VERSION ""

NS_ :

BS_:

BU_: ACU ALC BCM ESCL HFM HPCU HVAC_CU LCU_ADB LCU_MBL MainLiB12V USM eRDC_L eRDC_R

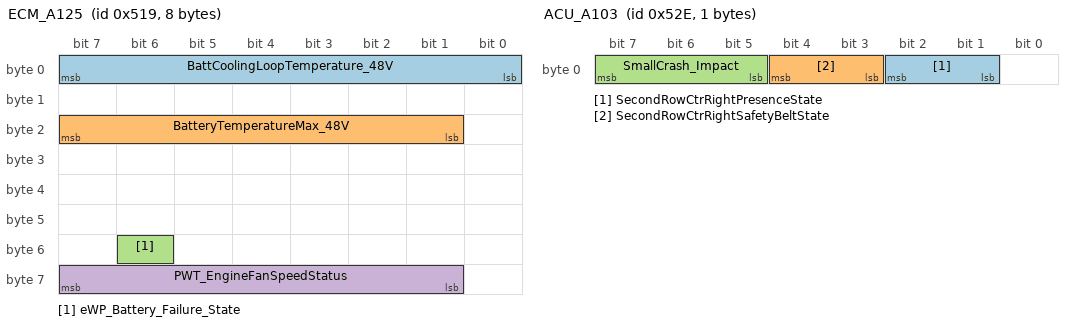
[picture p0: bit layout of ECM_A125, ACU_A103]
BO_ 1305 ECM_A125: 8 BCM
  SG_ BattCoolingLoopTemperature_48V : 7|8@0+ (1,-50) [-50|130] "°C" HVAC_CU
  SG_ BatteryTemperatureMax_48V : 23|7@0+ (1,-40) [-40|80] "°C" HVAC_CU
  SG_ eWP_Battery_Failure_State : 54|1@0+ (1,0) [0|0] "" HVAC_CU
  SG_ PWT_EngineFanSpeedStatus : 63|7@0+ (1,0) [0|100] "%" USM

BO_ 1306 HFM_BLM_pairing_Frame: 8 HFM
  SG_ HFM_BLM_pairing : 7|64@0+ (1,0) [0|0] "" BCM

BO_ 1308 BLM_HFM_pairing_Frame: 8 BCM
  SG_ BLM_HFM_pairing : 7|64@0+ (1,0) [0|0] "" HFM

BO_ 1311 BCM_A121: 3 BCM
  SG_ Flush_MovingRequest : 7|2@0+ (1,0) [0|0] "" HFM

BO_ 1315 BCM_A8: 3 BCM
  SG_ AbsoluteTimeSince1rstIgnition : 7|24@0+ (1,0) [0|1.677E7] "min" HVAC_CU,USM

BO_ 1322 HVAC_A9: 8 HVAC_CU
  SG_ HVAC_CalID2 : 7|64@0+ (1,0) [0|1.84467440737095E19] "" BCM

BO_ 1326 ACU_A103: 1 ACU
  SG_ SecondRowCtrRightPresenceState : 2|2@0+ (1,0) [0|0] "" BCM
  SG_ SecondRowCtrRightSafetyBeltState : 4|2@0+ (1,0) [0|0] "" BCM
  SG_ SmallCrash_Impact : 7|3@0+ (1,0) [0|0] "" BCM

BO_ 1328 HEVC_A167: 8 BCM
  SG_ HVbatCoolingSaveRequest : 57|1@0+ (1,0) [0|0] "" HVAC_CU
  SG_ HVbatCoolingSave_AmbTempThres : 63|6@0+ (1,-10) [-10|50] "degC" HVAC_CU

BO_ 1332 ACU_A101: 8 ACU
  SG_ CRC_ACU_A101 : 7|8@0+ (1,0) [0|255] "" BCM
  SG_ AIRBAGMalfunction : 8|1@0+ (1,0) [0|0] "" BCM
  SG_ ActiveHoodWarningLampCheck : 9|1@0+ (1,0) [0|0] "" BCM
  SG_ ActiveHoodMalfunction : 11|2@0+ (1,0) [0|0] "" BCM
  SG_ Clock_ACU_A101 : 15|4@0+ (1,0) [0|15] "" BCM
  SG_ PassengerAlertState : 17|2@0+ (1,0) [0|0] "" BCM
  SG_ PassengerAIRBAG_Inhibition : 18|1@0+ (1,0) [0|0] "" BCM
  SG_ CrashDetectionOutOfOrder_v2 : 20|2@0+ (1,0) [0|0] "" BCM
  SG_ CrashDetected_v2 : 22|2@0+ (1,0) [0|0] "" BCM
  SG_ AirbagWarningLampCheck : 23|1@0+ (1,0) [0|0] "" BCM
  SG_ SecondRowCenterPresenceState : 26|2@0+ (1,0) [0|0] "" BCM,HVAC_CU,USM
  SG_ RolloverDetectionMalfunction : 27|1@0+ (1,0) [0|0] "" BCM
  SG_ PassengerSafetyBeltBuckleState : 29|2@0+ (1,0) [0|0] "" BCM,HVAC_CU,USM
  SG_ PassengerPresenceState : 31|2@0+ (1,0) [0|0] "" BCM,HVAC_CU,USM
  SG_ SecondRowRightPresenceState : 33|2@0+ (1,0) [0|0] "" BCM,HVAC_CU,USM
  SG_ SecondRowLeftSafetyBeltState : 35|2@0+ (1,0) [0|0] "" BCM,HVAC_CU,USM
  SG_ SecondRowLeftPresenceState : 37|2@0+ (1,0) [0|0] "" BCM,HVAC_CU,USM
  SG_ SecondRowCenterSafetyBeltState : 39|2@0+ (1,0) [0|0] "" BCM,HVAC_CU,USM
  SG_ ThirdRowLeftPresenceState : 41|2@0+ (1,0) [0|0] "" BCM,HVAC_CU,USM
  SG_ ThirdRowCenterSafetyBeltState : 43|2@0+ (1,0) [0|0] "" BCM,HVAC_CU,USM
  SG_ ThirdRowCenterPresenceState : 45|2@0+ (1,0) [0|0] "" BCM,USM
  SG_ SecondRowRightSafetyBeltState : 47|2@0+ (1,0) [0|0] "" BCM,HVAC_CU,USM
  SG_ FirstRowCenterPresenceState : 49|2@0+ (1,0) [0|0] "" BCM,HVAC_CU,USM
  SG_ ThirdRowRightSafetyBeltState : 51|2@0+ (1,0) [0|0] "" BCM,HVAC_CU,USM
  SG_ ThirdRowRightPresenceState : 53|2@0+ (1,0) [0|0] "" BCM,HVAC_CU,USM
  SG_ ThirdRowLeftSafetyBeltState : 55|2@0+ (1,0) [0|0] "" BCM,HVAC_CU,USM
  SG_ PassengerAIRBAG_Status_Display : 59|2@0+ (1,0) [0|0] "" BCM
  SG_ PassengerAIRBAG_Inhibition_v2 : 61|2@0+ (1,0) [0|0] "" BCM
  SG_ FirstRowCenterSafetyBeltState : 63|2@0+ (1,0) [0|0] "" BCM,HVAC_CU,USM

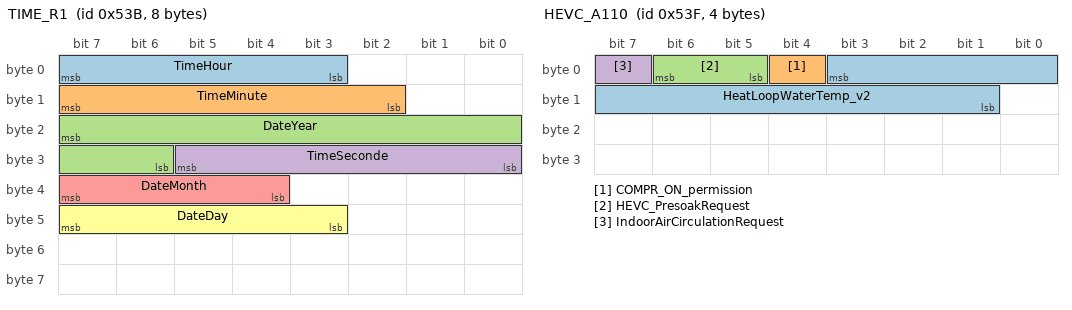
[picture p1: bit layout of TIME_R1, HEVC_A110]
BO_ 1339 TIME_R1: 8 BCM
  SG_ TimeHour : 7|5@0+ (1,0) [0|23] "h" ACU,HVAC_CU
  SG_ TimeMinute : 15|6@0+ (1,0) [0|59] "min" ACU,HVAC_CU
  SG_ DateYear : 23|10@0+ (1,2000) [2000|3000] "year" ACU
  SG_ TimeSeconde : 29|6@0+ (1,0) [0|59] "s" ACU
  SG_ DateMonth : 39|4@0+ (1,0) [0|12] "month" ACU
  SG_ DateDay : 47|5@0+ (1,0) [0|31] "day" ACU

BO_ 1343 HEVC_A110: 4 BCM
  SG_ HeatLoopWaterTemp_v2 : 3|11@0+ (0.1,-40) [-40|100] "°C" HVAC_CU
  SG_ COMPR_ON_permission : 4|1@0+ (1,0) [0|0] "" HVAC_CU
  SG_ HEVC_PresoakRequest : 6|2@0+ (1,0) [0|0] "" HVAC_CU
  SG_ IndoorAirCirculationRequest : 7|1@0+ (1,0) [0|0] "" HVAC_CU

BO_ 1352 HVAC_A8: 8 HVAC_CU
  SG_ HVAC_CalID1 : 7|64@0+ (1,0) [0|1.84467440737095E19] "" BCM

BO_ 1360 ECM_A121: 4 BCM
  SG_ EngineThrottlePosition : 7|7@0+ (1,0) [0|100] "%" ACU
  SG_ HVlightChargeRequest : 15|1@0+ (1,0) [0|0] "" USM

BO_ 1361 ADAS_A162: 8 BCM
  SG_ ELKA_OTOC_ActivationState : 52|1@0+ (1,0) [0|0] "" ACU
  SG_ ELKS_ActivationState : 54|1@0+ (1,0) [0|0] "" ACU

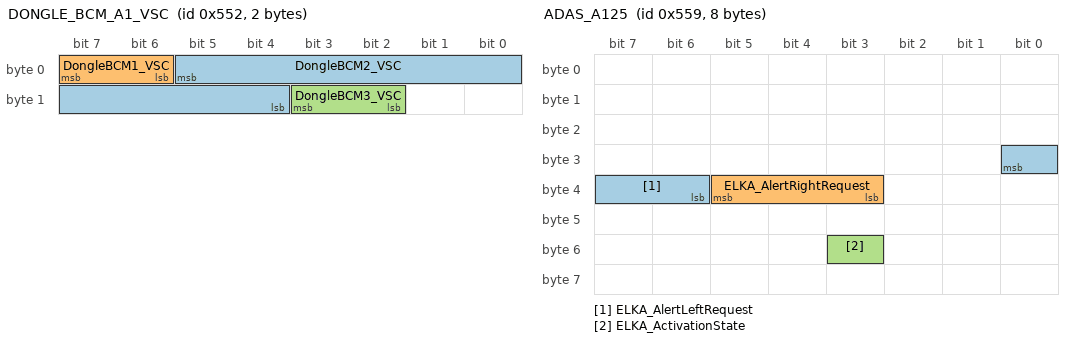
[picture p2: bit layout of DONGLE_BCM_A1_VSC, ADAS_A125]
BO_ 1362 DONGLE_BCM_A1_VSC: 2 HFM
  SG_ DongleBCM2_VSC : 5|10@0+ (1,0) [0|0] "" BCM
  SG_ DongleBCM1_VSC : 7|2@0+ (1,0) [0|0] "" BCM
  SG_ DongleBCM3_VSC : 11|2@0+ (1,0) [0|0] "" BCM

BO_ 1364 HVAC_A112: 7 HVAC_CU
  SG_ ClimElecConsumptionLimitDisplay : 1|2@0+ (1,0) [0|0] "" BCM
  SG_ ClimVariableAirFlowDisplay : 4|3@0+ (1,0) [0|0] "" BCM
  SG_ ClimRearOFFModeDisplay : 5|1@0+ (1,0) [0|0] "" BCM
  SG_ ClimRearLockStatus : 7|2@0+ (1,0) [0|0] "" BCM
  SG_ ClimLinkPrio3rdLSeatAutoDisp : 10|3@0+ (1,0) [0|0] "" BCM
  SG_ ClimIRSensorOn_Display : 12|2@0+ (1,0) [0|0] "" BCM
  SG_ ClimLinkPriorityRRSeatAutoDisp : 15|3@0+ (1,0) [0|0] "" BCM
  SG_ ProactiveRecyclingStatus : 16|1@0+ (1,0) [0|0] "" BCM
  SG_ ClimAllSeatAutoDisplay : 18|2@0+ (1,0) [0|0] "" BCM
  SG_ ClimLinkPrio3rdRSeatAutoDisp : 21|3@0+ (1,0) [0|0] "" BCM
  SG_ ClimRearOFFModeDisplayStatus : 22|1@0+ (1,0) [0|0] "" BCM
  SG_ ClimRearLockDisplayStatus : 23|1@0+ (1,0) [0|0] "" BCM
  SG_ HVBatteryCoolingType : 25|2@0+ (1,0) [0|0] "" BCM
  SG_ RecyPollutionStatus : 27|2@0+ (1,0) [0|0] "" BCM
  SG_ MistingRisk : 31|4@0+ (1,0) [0|10] "WU" BCM
  SG_ SecondRightSeatModeDisp : 33|2@0+ (1,0) [0|0] "" BCM
  SG_ SecondLeftSeatModeDisp : 35|2@0+ (1,0) [0|0] "" BCM
  SG_ FrontRightSeatModeDisp : 37|2@0+ (1,0) [0|0] "" BCM
  SG_ FrontLeftSeatModeDisp : 39|2@0+ (1,0) [0|0] "" BCM
  SG_ ClimLinkOccupantForSeatDisplay : 41|2@0+ (1,0) [0|0] "" BCM
  SG_ ClimLinkOccupantForDRZoneDisp : 43|2@0+ (1,0) [0|0] "" BCM
  SG_ ClimShortcutRequest : 47|4@0+ (1,0) [0|0] "" BCM
  SG_ ClimPartialAutoState : 55|1@0+ (1,0) [0|0] "" BCM

BO_ 1369 ADAS_A125: 8 BCM
  SG_ ELKA_AlertLeftRequest : 24|3@0+ (1,0) [0|0] "" ACU
  SG_ ELKA_AlertRightRequest : 37|3@0+ (1,0) [0|0] "" ACU
  SG_ ELKA_ActivationState : 51|1@0+ (1,0) [0|0] "" ACU

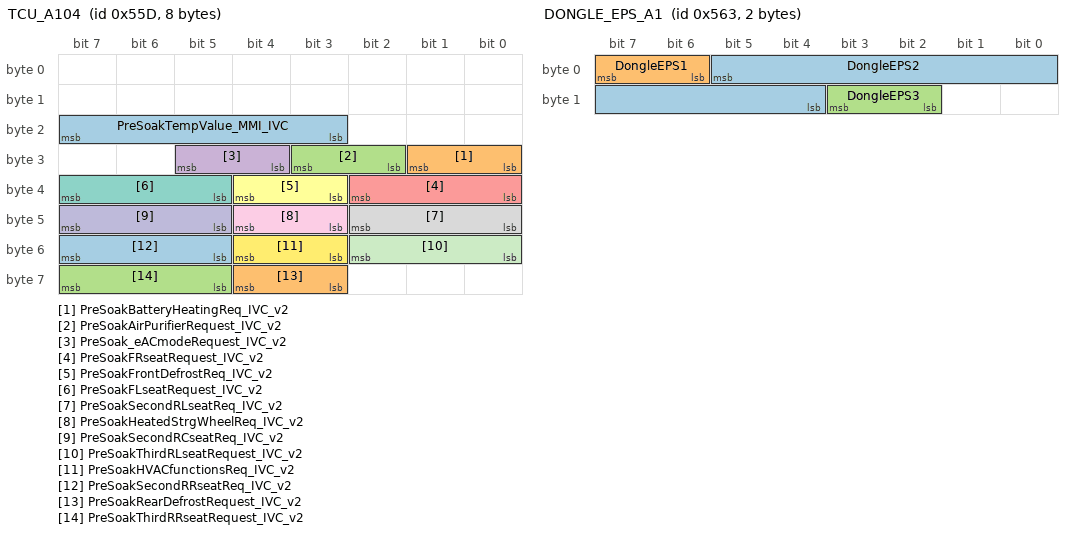
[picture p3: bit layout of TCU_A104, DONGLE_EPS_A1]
BO_ 1373 TCU_A104: 8 BCM
  SG_ PreSoakTempValue_MMI_IVC : 23|5@0+ (0.5,16) [16|32] "°C" HVAC_CU
  SG_ PreSoakBatteryHeatingReq_IVC_v2 : 25|2@0+ (1,0) [0|0] "" HVAC_CU
  SG_ PreSoakAirPurifierRequest_IVC_v2 : 27|2@0+ (1,0) [0|0] "" HVAC_CU
  SG_ PreSoak_eACmodeRequest_IVC_v2 : 29|2@0+ (1,0) [0|0] "" HVAC_CU
  SG_ PreSoakFRseatRequest_IVC_v2 : 34|3@0+ (1,0) [0|0] "" HVAC_CU
  SG_ PreSoakFrontDefrostReq_IVC_v2 : 36|2@0+ (1,0) [0|0] "" HVAC_CU
  SG_ PreSoakFLseatRequest_IVC_v2 : 39|3@0+ (1,0) [0|0] "" HVAC_CU
  SG_ PreSoakSecondRLseatReq_IVC_v2 : 42|3@0+ (1,0) [0|0] "" HVAC_CU
  SG_ PreSoakHeatedStrgWheelReq_IVC_v2 : 44|2@0+ (1,0) [0|0] "" HVAC_CU
  SG_ PreSoakSecondRCseatReq_IVC_v2 : 47|3@0+ (1,0) [0|0] "" HVAC_CU
  SG_ PreSoakThirdRLseatRequest_IVC_v2 : 50|3@0+ (1,0) [0|0] "" HVAC_CU
  SG_ PreSoakHVACfunctionsReq_IVC_v2 : 52|2@0+ (1,0) [0|0] "" HVAC_CU
  SG_ PreSoakSecondRRseatReq_IVC_v2 : 55|3@0+ (1,0) [0|0] "" HVAC_CU
  SG_ PreSoakRearDefrostRequest_IVC_v2 : 60|2@0+ (1,0) [0|0] "" HVAC_CU
  SG_ PreSoakThirdRRseatRequest_IVC_v2 : 63|3@0+ (1,0) [0|0] "" HVAC_CU

BO_ 1379 DONGLE_EPS_A1: 2 BCM
  SG_ DongleEPS2 : 5|10@0+ (1,0) [0|0] "" HFM
  SG_ DongleEPS1 : 7|2@0+ (1,0) [0|0] "" HFM
  SG_ DongleEPS3 : 11|2@0+ (1,0) [0|0] "" HFM

BO_ 1381 SRRR_A106: 6 BCM
  SG_ BSWrad_AlertStatus : 4|2@0+ (1,0) [0|0] "" ACU

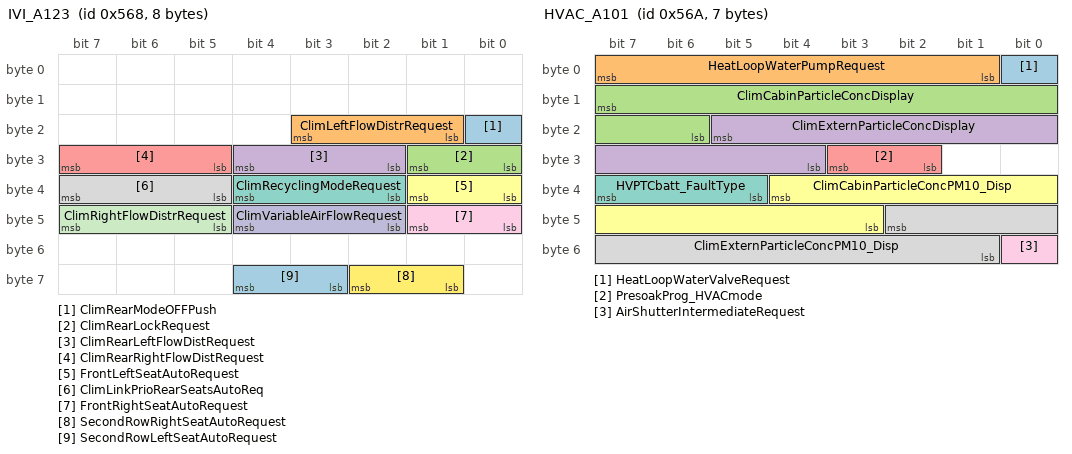
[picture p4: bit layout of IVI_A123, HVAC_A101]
BO_ 1384 IVI_A123: 8 BCM
  SG_ ClimRearModeOFFPush : 16|1@0+ (1,0) [0|1] "-" HVAC_CU
  SG_ ClimLeftFlowDistrRequest : 19|3@0+ (1,0) [0|0] "" HVAC_CU
  SG_ ClimRearLockRequest : 25|2@0+ (1,0) [0|0] "" HVAC_CU
  SG_ ClimRearLeftFlowDistRequest : 28|3@0+ (1,0) [0|0] "" HVAC_CU
  SG_ ClimRearRightFlowDistRequest : 31|3@0+ (1,0) [0|0] "" HVAC_CU
  SG_ FrontLeftSeatAutoRequest : 33|2@0+ (1,0) [0|0] "" HVAC_CU
  SG_ ClimRecyclingModeRequest : 36|3@0+ (1,0) [0|0] "" HVAC_CU
  SG_ ClimLinkPrioRearSeatsAutoReq : 39|3@0+ (1,0) [0|0] "" HVAC_CU
  SG_ FrontRightSeatAutoRequest : 41|2@0+ (1,0) [0|0] "" HVAC_CU
  SG_ ClimVariableAirFlowRequest : 44|3@0+ (1,0) [0|0] "" HVAC_CU
  SG_ ClimRightFlowDistrRequest : 47|3@0+ (1,0) [0|0] "" HVAC_CU
  SG_ SecondRowRightSeatAutoRequest : 58|2@0+ (1,0) [0|0] "" HVAC_CU
  SG_ SecondRowLeftSeatAutoRequest : 60|2@0+ (1,0) [0|0] "" HVAC_CU

BO_ 1386 HVAC_A101: 7 HVAC_CU
  SG_ HeatLoopWaterValveRequest : 0|1@0+ (1,0) [0|0] "" BCM
  SG_ HeatLoopWaterPumpRequest : 7|7@0+ (1,0) [0|100] "%" BCM
  SG_ ClimCabinParticleConcDisplay : 15|10@0+ (5,0) [0|4095] "µg/m3" BCM
  SG_ ClimExternParticleConcDisplay : 21|10@0+ (5,0) [0|4095] "µg/m3" BCM
  SG_ PresoakProg_HVACmode : 27|2@0+ (1,0) [0|0] "" BCM
  SG_ ClimCabinParticleConcPM10_Disp : 36|10@0+ (5,0) [0|4095] "µg/m3" BCM
  SG_ HVPTCbatt_FaultType : 39|3@0+ (1,0) [0|0] "" BCM
  SG_ ClimExternParticleConcPM10_Disp : 42|10@0+ (5,0) [0|4095] "µg/m3" BCM
  SG_ AirShutterIntermediateRequest : 48|1@0+ (1,0) [0|0] "" BCM

BO_ 1387 HVAC_A110: 8 HVAC_CU
  SG_ HVAC_CVN : 7|64@0+ (1,0) [0|1.84467440737095E19] "" BCM

BO_ 1391 HVAC_A109: 2 HVAC_CU
  SG_ AC_eBattPTCInterlockHVConnector : 11|2@0+ (1,0) [0|0] "" BCM

BO_ 1392 IVI_A119: 8 BCM
  SG_ FOTA_ReadyToSleep_IVI : 9|1@0+ (1,0) [0|0] "" USM

BO_ 1395 HEVC_A137: 6 BCM
  SG_ SecondaryShaft_Speed : 31|12@0+ (100,-32700) [-32700|32700] "rpm" ACU
  SG_ HSG_ElecMachineSpeed_EDR : 35|12@0+ (100,-20000) [-20000|20000] "rpm" ACU

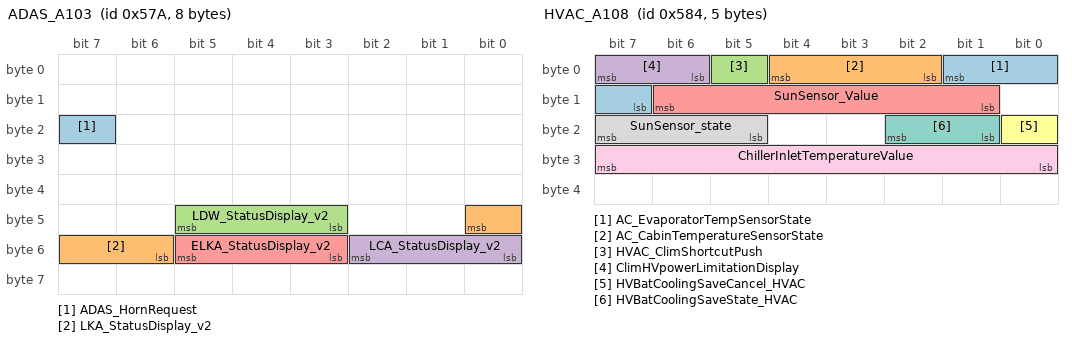
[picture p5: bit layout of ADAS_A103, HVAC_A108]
BO_ 1402 ADAS_A103: 8 BCM
  SG_ ADAS_HornRequest : 23|1@0+ (1,0) [0|0] "" USM
  SG_ LKA_StatusDisplay_v2 : 40|3@0+ (1,0) [0|0] "" ACU
  SG_ LDW_StatusDisplay_v2 : 45|3@0+ (1,0) [0|0] "" ACU
  SG_ LCA_StatusDisplay_v2 : 50|3@0+ (1,0) [0|0] "" ACU
  SG_ ELKA_StatusDisplay_v2 : 53|3@0+ (1,0) [0|0] "" ACU

BO_ 1405 AVM_N104: 7 BCM
  SG_ RPK_ModeRequest : 55|2@0+ (1,0) [0|0] "" HFM

BO_ 1409 ESCL3_to_BCM: 8 ESCL
  SG_ Blank_Coded : 0|1@0+ (1,0) [0|0] "" HFM
  SG_ LockingFinished : 1|1@0+ (1,0) [0|0] "" HFM
  SG_ Undefined_position : 2|1@0+ (1,0) [0|0] "" HFM
  SG_ UnlockingFinished : 3|1@0+ (1,0) [0|0] "" HFM
  SG_ LockForbidden : 4|1@0+ (1,0) [0|0] "" HFM
  SG_ AntiscanOn : 5|1@0+ (1,0) [0|0] "" HFM
  SG_ WrongCode : 6|1@0+ (1,0) [0|0] "" HFM
  SG_ SteeringLockCOP : 7|1@0+ (1,0) [0|0] "" HFM
  SG_ SteeringLockMajorElectronicFailure : 9|1@0+ (1,0) [0|0] "" HFM
  SG_ Steering_actuator_failure : 10|1@0+ (1,0) [0|0] "" HFM
  SG_ ESCL3Position : 13|3@0+ (1,0) [0|0] "" HFM
  SG_ SteeringLock_Minor_Electronic_Failure : 14|1@0+ (1,0) [0|0] "" HFM
  SG_ ResetInfo_Verrou : 15|1@0+ (1,0) [0|0] "" HFM
  SG_ PowerSupplyFeedback : 18|1@0+ (1,0) [0|0] "" HFM
  SG_ SafetyLineInhibition : 20|1@0+ (1,0) [0|0] "" HFM
  SG_ SpeedInhibition : 23|1@0+ (1,0) [0|0] "" HFM
  SG_ SensorTestAuthorized : 31|1@0+ (1,0) [0|0] "" HFM
  SG_ CRC_ESCL3_to_BCM : 39|8@0+ (1,0) [0|255] "" HFM
  SG_ Inconsistency_Frame : 43|1@0+ (1,0) [0|0] "" HFM
  SG_ Clock_ESCL3_to_BCM : 47|4@0+ (1,0) [0|15] "" HFM

BO_ 1412 HVAC_A108: 5 HVAC_CU
  SG_ AC_EvaporatorTempSensorState : 1|3@0+ (1,0) [0|0] "" BCM
  SG_ AC_CabinTemperatureSensorState : 4|3@0+ (1,0) [0|0] "" BCM
  SG_ HVAC_ClimShortcutPush : 5|1@0+ (1,0) [0|0] "" BCM
  SG_ ClimHVpowerLimitationDisplay : 7|2@0+ (1,0) [0|0] "" BCM
  SG_ SunSensor_Value : 14|6@0+ (25,0) [0|1200] "W/m2" BCM
  SG_ HVBatCoolingSaveCancel_HVAC : 16|1@0+ (1,0) [0|0] "" BCM
  SG_ HVBatCoolingSaveState_HVAC : 18|2@0+ (1,0) [0|0] "" BCM
  SG_ SunSensor_state : 23|3@0+ (1,0) [0|0] "" BCM
  SG_ ChillerInletTemperatureValue : 31|8@0+ (1,-40) [-40|105] "°C" BCM

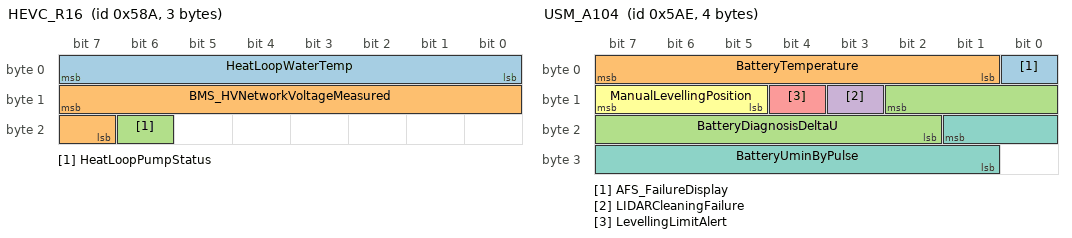
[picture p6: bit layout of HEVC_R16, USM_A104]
BO_ 1418 HEVC_R16: 3 BCM
  SG_ HeatLoopWaterTemp : 7|8@0+ (1,-40) [-40|214] "°C" HVAC_CU
  SG_ BMS_HVNetworkVoltageMeasured : 15|9@0+ (1,0) [0|500] "V" HVAC_CU
  SG_ HeatLoopPumpStatus : 22|1@0+ (1,0) [0|0] "" HVAC_CU

BO_ 1430 ADAS_A166: 1 BCM
  SG_ AEB_Classification : 4|3@0+ (1,0) [0|0] "" ACU
  SG_ AEB_Activation_Flag : 7|3@0+ (1,0) [0|0] "" ACU

BO_ 1436 HFP_R5: 6 BCM
  SG_ HFP_MapContentDisplay : 31|3@0+ (1,0) [0|0] "" ACU

BO_ 1449 IVI_A109: 8 BCM
  SG_ ClimFrontDefrostPush : 0|1@0+ (1,0) [0|1] "-" HVAC_CU
  SG_ ClimRearDefrostPush : 1|1@0+ (1,0) [0|1] "-" HVAC_CU
  SG_ SecondRowLeftSeatAutoPush : 2|1@0+ (1,0) [0|1] "-" HVAC_CU
  SG_ SecondRowRightSeatAutoPush : 3|1@0+ (1,0) [0|1] "-" HVAC_CU
  SG_ ThirdRowLeftSeatAutoPush : 4|1@0+ (1,0) [0|1] "-" HVAC_CU
  SG_ ThirdRowRightSeatAutoPush : 5|1@0+ (1,0) [0|1] "-" HVAC_CU
  SG_ ClimHeatedSteeringWheelPush : 6|1@0+ (1,0) [0|1] "-" HVAC_CU
  SG_ ClimHeatedSteeringWheelAutoPush : 7|1@0+ (1,0) [0|1] "-" HVAC_CU
  SG_ ClimRearLeftTempRequest : 15|9@0+ (0.5,10) [10|127.5] "°" HVAC_CU
  SG_ ClimRearRightTempRequest : 22|9@0+ (0.5,10) [10|127.5] "°" HVAC_CU
  SG_ ClimRearRightFlowDistrVentPush : 24|1@0+ (1,0) [0|1] "" HVAC_CU
  SG_ ClimRearLeftFlowDistrVentPush : 25|1@0+ (1,0) [0|1] "" HVAC_CU
  SG_ ClimRearRightFlowDistrDefPush : 26|1@0+ (1,0) [0|1] "" HVAC_CU
  SG_ ClimRearLeftFlowDistrDefPush : 27|1@0+ (1,0) [0|1] "" HVAC_CU
  SG_ ClimRearRightSyncPush : 28|1@0+ (1,0) [0|1] "" HVAC_CU
  SG_ ClimRearLeftSyncPush : 29|1@0+ (1,0) [0|1] "" HVAC_CU
  SG_ ClimLinkPriorityHeatStrgAutoReq : 34|3@0+ (1,0) [0|0] "" HVAC_CU
  SG_ ClimRearRightAutoNormalPush : 35|1@0+ (1,0) [0|1] "" HVAC_CU
  SG_ ClimRearLeftAutoNormalPush : 36|1@0+ (1,0) [0|1] "" HVAC_CU
  SG_ ClimRearACPush : 37|1@0+ (1,0) [0|1] "" HVAC_CU
  SG_ ClimRearRightFlowDistrFeetPush : 38|1@0+ (1,0) [0|1] "" HVAC_CU
  SG_ ClimRearLeftFlowDistrFeetPush : 39|1@0+ (1,0) [0|1] "" HVAC_CU
  SG_ ClimFPrearLeftBlowingRequest : 43|4@0+ (1,0) [0|0] "" HVAC_CU
  SG_ ClimFPrearRightBlowingRequest : 47|4@0+ (1,0) [0|0] "" HVAC_CU
  SG_ ClimLinkPriorityRRSeatAutoReq : 50|3@0+ (1,0) [0|0] "" HVAC_CU
  SG_ ClimACmaxPush : 51|1@0+ (1,0) [0|1] "-" HVAC_CU
  SG_ ClimAllSeatAutoNormalRequest : 57|2@0+ (1,0) [0|0] "" HVAC_CU
  SG_ ClimLinkPrio3rdRSeatAutoReq : 60|3@0+ (1,0) [0|0] "" HVAC_CU
  SG_ ClimLinkPrio3rdLSeatAutoReq : 63|3@0+ (1,0) [0|0] "" HVAC_CU

BO_ 1454 USM_A104: 4 USM
  SG_ AFS_FailureDisplay : 0|1@0+ (1,0) [0|0] "" BCM
  SG_ BatteryTemperature : 7|7@0+ (1,-40) [-40|80] "°C" BCM
  SG_ BatteryDiagnosisDeltaU : 10|9@0+ (0.05,0) [0|17] "V" BCM
  SG_ LIDARCleaningFailure : 11|1@0+ (1,0) [0|0] "" BCM
  SG_ LevellingLimitAlert : 12|1@0+ (1,0) [0|0] "" BCM
  SG_ ManualLevellingPosition : 15|3@0+ (1,0) [0|0] "" BCM
  SG_ BatteryUminByPulse : 17|9@0+ (0.05,0) [0|17] "V" BCM

BO_ 1457 BCM_R9: 4 BCM
  SG_ LightingSystemFailureDisplay : 17|1@0+ (1,0) [0|0] "" LCU_ADB

BO_ 1458 HEVC_R112: 8 BCM
  SG_ SportModeThmgtRequest : 63|2@0+ (1,0) [0|0] "" HVAC_CU

BO_ 1462 HVAC_A105: 8 HVAC_CU
  SG_ ClimRearLeftTempDisplay : 7|9@0+ (0.5,0) [10|127.5] "°" BCM
  SG_ ClimFrontDefrostDisplayStatus : 8|1@0+ (1,0) [0|0] "" BCM
  SG_ ClimHeatedSteerWheelDispStatus : 9|1@0+ (1,0) [0|0] "" BCM
  SG_ ClimRearLeftTempDisplayStatus : 10|1@0+ (1,0) [0|0] "" BCM
  SG_ ClimHeatedSteerWheelAutoDisplay : 12|2@0+ (1,0) [0|0] "" BCM
  SG_ ClimFrontDefrostDisplay : 14|2@0+ (1,0) [0|0] "" BCM
  SG_ ClimRearRightTempDisplay : 23|9@0+ (0.5,0) [10|127.5] "°" BCM
  SG_ ClimRearRightSyncDisplayStatus : 24|1@0+ (1,0) [0|0] "" BCM
  SG_ ClimRearRightSyncDisplay : 26|2@0+ (1,0) [0|0] "" BCM
  SG_ ClimRearLeftSyncDisplayStatus : 27|1@0+ (1,0) [0|0] "" BCM
  SG_ ClimRearLeftSyncDisplay : 29|2@0+ (1,0) [0|0] "" BCM
  SG_ ClimRearRightTempDisplayStatus : 30|1@0+ (1,0) [0|0] "" BCM
  SG_ ClimRearRightFlowDistDispStatus : 32|1@0+ (1,0) [0|0] "" BCM
  SG_ ClimRearRightFlowDistrDisplay : 35|3@0+ (1,0) [0|0] "" BCM
  SG_ ClimRearLeftFlowDistrDispStatus : 36|1@0+ (1,0) [0|0] "" BCM
  SG_ ClimRearLeftFlowDistrDisplay : 39|3@0+ (1,0) [0|0] "" BCM
  SG_ ClimRearLeftBlowingAutoDisplay : 41|2@0+ (1,0) [0|0] "" BCM
  SG_ ClimRearRightBlowingAutoDisplay : 43|2@0+ (1,0) [0|0] "" BCM
  SG_ ClimRearRightBlowLevelDisplay : 47|4@0+ (1,0) [0|0] "" BCM
  SG_ ClimRearACDisplay : 49|2@0+ (1,0) [0|0] "" BCM
  SG_ ClimRearRightBlowLevlDispStatus : 50|1@0+ (1,0) [0|0] "" BCM
  SG_ ClimRearLeftBlowLevelDispStatus : 51|1@0+ (1,0) [0|0] "" BCM
  SG_ ClimRearLeftBlowLevelDisplay : 55|4@0+ (1,0) [0|0] "" BCM
  SG_ ClimLinkPrioritHeatStrgAutoDisp : 58|3@0+ (1,0) [0|0] "" BCM
  SG_ ClimRearRightAutoDisplay : 60|2@0+ (1,0) [0|0] "" BCM
  SG_ ClimRearLeftAutoDisplay : 62|2@0+ (1,0) [0|0] "" BCM
  SG_ ClimRearACDisplayStatus : 63|1@0+ (1,0) [0|0] "" BCM

BO_ 1465 IVI_A110: 8 BCM
  SG_ PreSoakHVACfunctionsRequest : 0|2@0+ (1,0) [0|0] "" HVAC_CU
  SG_ PreSoakTempValue_MMI_v2 : 7|7@0+ (0.5,16) [16|32] "°C" HVAC_CU
  SG_ PreSoakFRseatRequest : 10|3@0+ (1,0) [0|0] "" HVAC_CU
  SG_ PreSoakFLseatRequest : 13|3@0+ (1,0) [0|0] "" HVAC_CU
  SG_ PreSoakSecondRLseatRequest : 18|3@0+ (1,0) [0|0] "" HVAC_CU
  SG_ PreSoakSecondRRseatRequest : 21|3@0+ (1,0) [0|0] "" HVAC_CU
  SG_ PreSoak_eACmodeRequest : 23|2@0+ (1,0) [0|0] "" HVAC_CU
  SG_ PreSoakThirdRLseatRequest : 26|3@0+ (1,0) [0|0] "" HVAC_CU
  SG_ PreSoakBatteryHeatingRequest : 28|2@0+ (1,0) [0|0] "" HVAC_CU
  SG_ PreSoakSecondRCseatRequest : 31|3@0+ (1,0) [0|0] "" HVAC_CU
  SG_ PreSoakAirPurifierRequest : 34|2@0+ (1,0) [0|0] "" HVAC_CU
  SG_ PreSoakFrontDefrostRequest : 36|2@0+ (1,0) [0|0] "" HVAC_CU
  SG_ PreSoakThirdRRseatRequest : 39|3@0+ (1,0) [0|0] "" HVAC_CU
  SG_ SecondRowCentralSeatRequest : 43|4@0+ (1,0) [0|0] "" HVAC_CU
  SG_ PreSoakRearDefrostRequest : 45|2@0+ (1,0) [0|0] "" HVAC_CU
  SG_ PreSoakHeatedStrgWheelRequest : 47|2@0+ (1,0) [0|0] "" HVAC_CU
  SG_ FrontRightSeatRequest : 51|4@0+ (1,0) [0|0] "" HVAC_CU
  SG_ FrontLeftSeatRequest : 55|4@0+ (1,0) [0|0] "" HVAC_CU

BO_ 1469 IVI_UserSetPref_A4: 8 BCM
  SG_ IoniserAutoLaunchReq2 : 51|2@0+ (1,0) [0|0] "" HVAC_CU

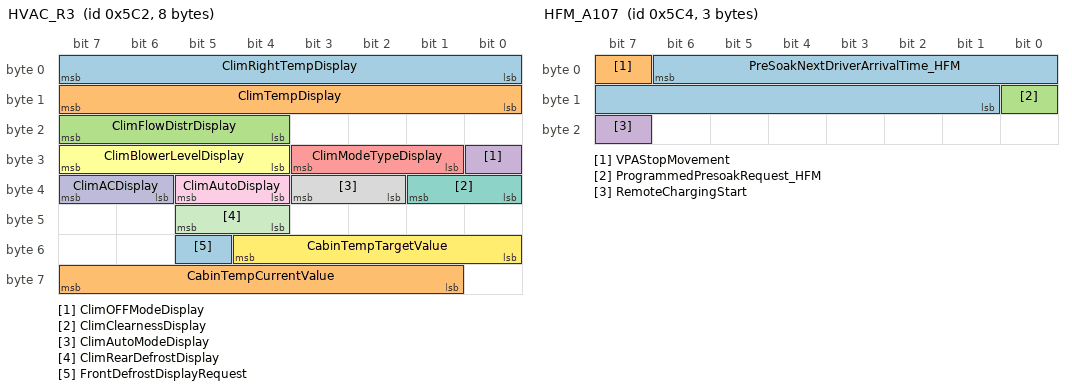
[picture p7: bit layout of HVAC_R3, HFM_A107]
BO_ 1474 HVAC_R3: 8 HVAC_CU
  SG_ ClimRightTempDisplay : 7|8@0+ (0.5,0) [10|127.5] "°" BCM
  SG_ ClimTempDisplay : 15|8@0+ (0.5,0) [10|127.5] "°" BCM
  SG_ ClimFlowDistrDisplay : 23|4@0+ (1,0) [0|0] "" BCM
  SG_ ClimOFFModeDisplay : 24|1@0+ (1,0) [0|0] "" BCM
  SG_ ClimModeTypeDisplay : 27|3@0+ (1,0) [0|0] "" BCM
  SG_ ClimBlowerLevelDisplay : 31|4@0+ (1,0) [0|0] "" BCM
  SG_ ClimClearnessDisplay : 33|2@0+ (1,0) [0|0] "" BCM
  SG_ ClimAutoModeDisplay : 35|2@0+ (1,0) [0|0] "" BCM
  SG_ ClimAutoDisplay : 37|2@0+ (1,0) [0|0] "" BCM
  SG_ ClimACDisplay : 39|2@0+ (1,0) [0|0] "" BCM
  SG_ ClimRearDefrostDisplay : 45|2@0+ (1,0) [0|0] "" BCM
  SG_ CabinTempTargetValue : 52|5@0+ (0.5,16) [16|26] "°C" BCM
  SG_ FrontDefrostDisplayRequest : 53|1@0+ (1,0) [0|0] "" BCM
  SG_ CabinTempCurrentValue : 63|7@0+ (1,-40) [-40|60] "°C" BCM

BO_ 1476 HFM_A107: 3 HFM
  SG_ PreSoakNextDriverArrivalTime_HFM : 6|14@0+ (1,0) [0|10080] "min" BCM
  SG_ VPAStopMovement : 7|1@0+ (1,0) [0|0] "" BCM
  SG_ ProgrammedPresoakRequest_HFM : 8|1@0+ (1,0) [0|0] "" BCM
  SG_ RemoteChargingStart : 23|1@0+ (1,0) [0|0] "" BCM

BO_ 1482 IVI_UserSetPref_A2: 8 BCM
  SG_ HandDrivingActivationRequest2 : 47|2@0+ (1,0) [0|0] "" USM
  SG_ AFS_ActivationRequest2 : 61|2@0+ (1,0) [0|0] "" USM

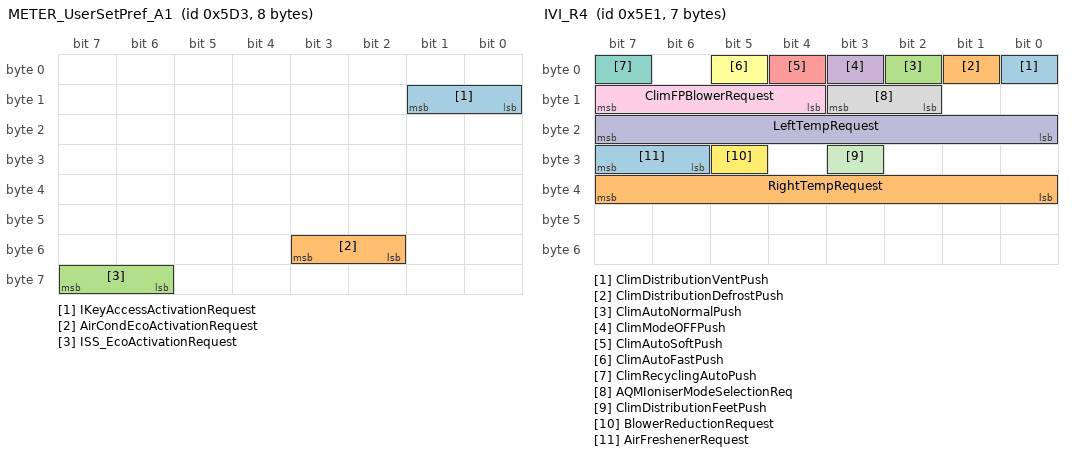
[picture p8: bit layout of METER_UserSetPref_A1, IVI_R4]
BO_ 1491 METER_UserSetPref_A1: 8 BCM
  SG_ IKeyAccessActivationRequest : 9|2@0+ (1,0) [0|0] "" HFM
  SG_ AirCondEcoActivationRequest : 51|2@0+ (1,0) [0|0] "" HVAC_CU
  SG_ ISS_EcoActivationRequest : 63|2@0+ (1,0) [0|0] "" HVAC_CU

BO_ 1499 RemoteFunctionService_HFM_Frame: 8 HFM
  SG_ RemoteFunctionService_HFM : 7|64@0+ (1,0) [0|0] "" BCM

BO_ 1505 IVI_R4: 7 BCM
  SG_ ClimDistributionVentPush : 0|1@0+ (1,0) [0|1] "" HVAC_CU
  SG_ ClimDistributionDefrostPush : 1|1@0+ (1,0) [0|1] "" HVAC_CU
  SG_ ClimAutoNormalPush : 2|1@0+ (1,0) [0|1] "" HVAC_CU
  SG_ ClimModeOFFPush : 3|1@0+ (1,0) [0|1] "" HVAC_CU
  SG_ ClimAutoSoftPush : 4|1@0+ (1,0) [0|1] "" HVAC_CU
  SG_ ClimAutoFastPush : 5|1@0+ (1,0) [0|1] "" HVAC_CU
  SG_ ClimRecyclingAutoPush : 7|1@0+ (1,0) [0|1] "" HVAC_CU
  SG_ AQMIoniserModeSelectionReq : 11|2@0+ (1,0) [0|0] "" HVAC_CU
  SG_ ClimFPBlowerRequest : 15|4@0+ (1,0) [0|0] "" HVAC_CU
  SG_ LeftTempRequest : 23|8@0+ (0.5,10) [10|127.5] "°" HVAC_CU
  SG_ ClimDistributionFeetPush : 27|1@0+ (1,0) [0|1] "" HVAC_CU
  SG_ BlowerReductionRequest : 29|1@0+ (1,0) [0|0] "" HVAC_CU
  SG_ AirFreshenerRequest : 31|2@0+ (1,0) [0|0] "" HVAC_CU
  SG_ RightTempRequest : 39|8@0+ (0.5,10) [10|127.5] "°" HVAC_CU

BO_ 1506 BCM_A101: 8 BCM
  SG_ RESPresoak_ImmediateReqForbid_SP : 60|1@0+ (1,0) [0|0] "" HFM

BO_ 1508 BCM_A115: 8 BCM
  SG_ RESPreSoak_ProgStatus : 9|2@0+ (1,0) [0|0] "" HVAC_CU

BO_ 1509 RemoteFunctionService_TCU_Frame: 8 BCM
  SG_ RemoteFunctionService_TCU : 7|64@0+ (1,0) [0|0] "" HFM

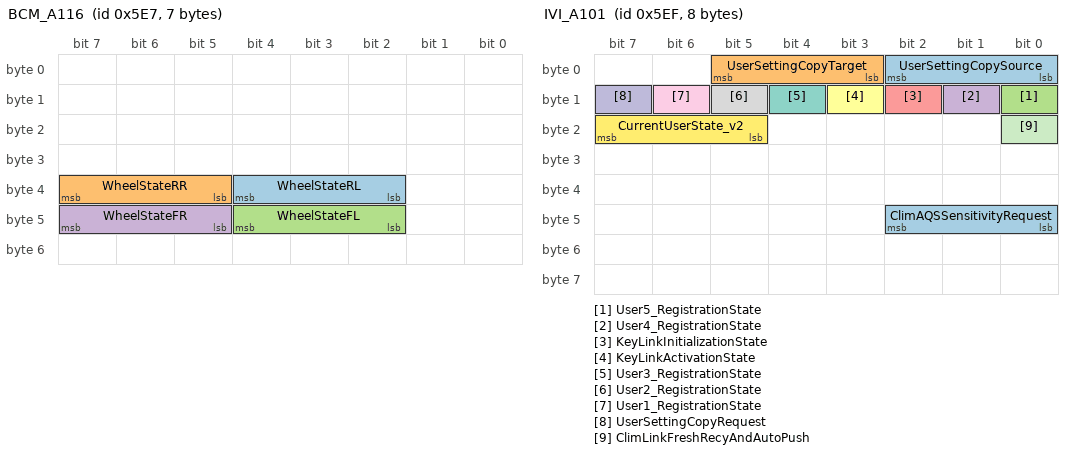
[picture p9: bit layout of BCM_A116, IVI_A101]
BO_ 1511 BCM_A116: 7 BCM
  SG_ WheelStateRL : 36|3@0+ (1,0) [0|0] "" ACU
  SG_ WheelStateRR : 39|3@0+ (1,0) [0|0] "" ACU
  SG_ WheelStateFL : 44|3@0+ (1,0) [0|0] "" ACU
  SG_ WheelStateFR : 47|3@0+ (1,0) [0|0] "" ACU

BO_ 1516 METER_UserSetPref_A2: 8 BCM
  SG_ AFS_ActivationRequest : 61|2@0+ (1,0) [0|0] "" USM

BO_ 1519 IVI_A101: 8 BCM
  SG_ UserSettingCopySource : 2|3@0+ (1,0) [0|0] "" HVAC_CU
  SG_ UserSettingCopyTarget : 5|3@0+ (1,0) [0|0] "" HVAC_CU
  SG_ User5_RegistrationState : 8|1@0+ (1,0) [0|0] "" HVAC_CU
  SG_ User4_RegistrationState : 9|1@0+ (1,0) [0|0] "" HVAC_CU
  SG_ KeyLinkInitializationState : 10|1@0+ (1,0) [0|0] "" HVAC_CU
  SG_ KeyLinkActivationState : 11|1@0+ (1,0) [0|0] "" HVAC_CU
  SG_ User3_RegistrationState : 12|1@0+ (1,0) [0|0] "" HVAC_CU
  SG_ User2_RegistrationState : 13|1@0+ (1,0) [0|0] "" HVAC_CU
  SG_ User1_RegistrationState : 14|1@0+ (1,0) [0|0] "" HVAC_CU
  SG_ UserSettingCopyRequest : 15|1@0+ (1,0) [0|0] "" HVAC_CU
  SG_ ClimLinkFreshRecyAndAutoPush : 16|1@0+ (1,0) [0|1] "" HVAC_CU
  SG_ CurrentUserState_v2 : 23|3@0+ (1,0) [0|0] "" HVAC_CU
  SG_ ClimAQSSensitivityRequest : 42|3@0+ (1,0) [0|0] "" HVAC_CU

BO_ 1526 HEVC_R110: 8 BCM
  SG_ PEBWaterTemp_BLMS : 7|8@0+ (1,-40) [-40|120] "°C" HPCU,HVAC_CU

BO_ 1529 IVI_UserSetPref_A3: 8 BCM
  SG_ WAL_ActivationRequest2 : 49|2@0+ (1,0) [0|0] "" HFM
  SG_ APPRUN_ActivationRequest2 : 63|2@0+ (1,0) [0|0] "" HFM

BO_ 1530 METER_UserSetPref_A3: 8 BCM
  SG_ WAL_ActivationRequest : 49|2@0+ (1,0) [0|0] "" HFM
  SG_ APPRUN_ActivationRequest : 63|2@0+ (1,0) [0|0] "" HFM

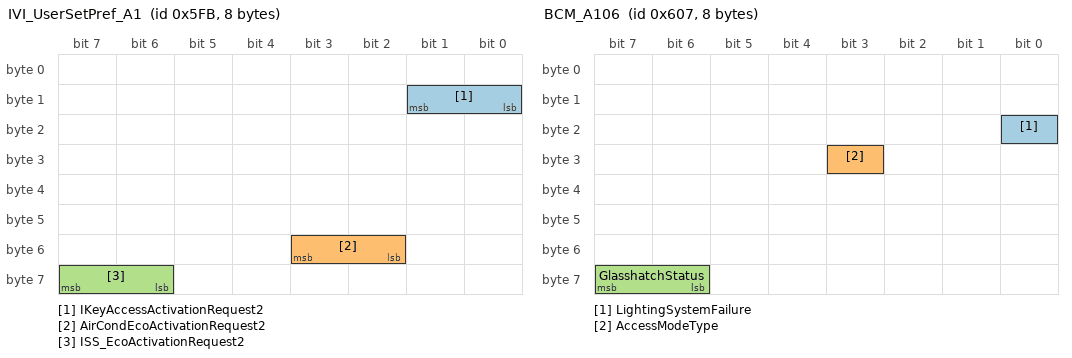
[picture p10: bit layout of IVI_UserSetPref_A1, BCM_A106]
BO_ 1531 IVI_UserSetPref_A1: 8 BCM
  SG_ IKeyAccessActivationRequest2 : 9|2@0+ (1,0) [0|0] "" HFM
  SG_ AirCondEcoActivationRequest2 : 51|2@0+ (1,0) [0|0] "" HVAC_CU
  SG_ ISS_EcoActivationRequest2 : 63|2@0+ (1,0) [0|0] "" HVAC_CU

BO_ 1536 USM_WakeUpFrame: 2 USM
  SG_ USM_WakeUp_Signal : 7|16@0+ (1,0) [0|0] "" BCM

BO_ 1537 ADAS_A119: 8 BCM
  SG_ ACC_StatusDisplay : 5|2@0+ (1,0) [0|0] "" ACU
  SG_ ADAS_ModeDisplay : 7|2@0+ (1,0) [0|0] "" ACU

BO_ 1538 ADAS_A120: 8 BCM
  SG_ LDW_AlertStatus : 21|2@0+ (1,0) [0|0] "" ACU

BO_ 1543 BCM_A106: 8 BCM
  SG_ LightingSystemFailure : 16|1@0+ (1,0) [0|0] "" USM
  SG_ AccessModeType : 27|1@0+ (1,0) [0|0] "" HFM
  SG_ GlasshatchStatus : 63|2@0+ (1,0) [0|0] "" HFM

BO_ 1546 HFM_WakeUpFrame: 2 HFM
  SG_ HFM_WakeUp_Signal : 7|16@0+ (1,0) [0|0] "" BCM

BO_ 1547 USM_N103: 8 USM
  SG_ USM_CalID2 : 7|64@0+ (1,0) [0|1.84467440737095E19] "-" BCM

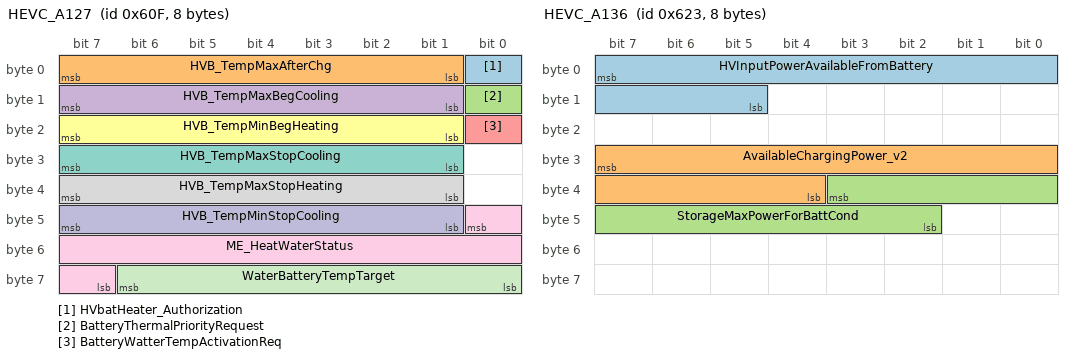
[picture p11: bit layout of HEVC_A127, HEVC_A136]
BO_ 1551 HEVC_A127: 8 BCM
  SG_ HVbatHeater_Authorization : 0|1@0+ (1,0) [0|0] "" HVAC_CU
  SG_ HVB_TempMaxAfterChg : 7|7@0+ (1,-40) [-40|80] "°C" HVAC_CU
  SG_ BatteryThermalPriorityRequest : 8|1@0+ (1,0) [0|0] "" HVAC_CU
  SG_ HVB_TempMaxBegCooling : 15|7@0+ (1,-40) [-40|80] "°C" HVAC_CU
  SG_ BatteryWatterTempActivationReq : 16|1@0+ (1,0) [0|0] "" HVAC_CU
  SG_ HVB_TempMinBegHeating : 23|7@0+ (1,-40) [-40|80] "°C" HVAC_CU
  SG_ HVB_TempMaxStopCooling : 31|7@0+ (1,-40) [-40|80] "°C" HVAC_CU
  SG_ HVB_TempMaxStopHeating : 39|7@0+ (1,-40) [-40|80] "°C" HVAC_CU
  SG_ ME_HeatWaterStatus : 40|10@0+ (10,0) [0|10000] "W" HVAC_CU
  SG_ HVB_TempMinStopCooling : 47|7@0+ (1,-40) [-40|80] "°C" HVAC_CU
  SG_ WaterBatteryTempTarget : 62|7@0+ (1,-40) [-40|60] "°C" HVAC_CU

BO_ 1553 HVAC_A106: 8 HVAC_CU
  SG_ SecondRowCentralSeatStatus : 2|3@0+ (1,0) [0|0] "" BCM
  SG_ ClimEVmodeAdviceForHeating : 5|3@0+ (1,0) [0|0] "" BCM
  SG_ ClimForcedFreshDisplayStatus : 6|1@0+ (1,0) [0|0] "" BCM
  SG_ ClimForcedRecyDisplayStatus : 7|1@0+ (1,0) [0|0] "" BCM
  SG_ ClimForcedFreshDisplay : 9|2@0+ (1,0) [0|0] "" BCM
  SG_ ClimAQSSensitivityDisplay : 12|3@0+ (1,0) [0|0] "" BCM
  SG_ ClimExternalAirPollutionDisplay : 15|3@0+ (1,0) [0|0] "" BCM
  SG_ ClimRearDefrostDisplayStatus : 16|1@0+ (1,0) [0|0] "" BCM
  SG_ ClimExternAirPollutioDispStatus : 17|1@0+ (1,0) [0|0] "" BCM
  SG_ ClimLinkPriorityFLSeatAutoDisp : 20|3@0+ (1,0) [0|0] "" BCM
  SG_ ClimLinkPriorityFRSeatAutoDisp : 23|3@0+ (1,0) [0|0] "" BCM
  SG_ FrontRightSeatDisplayStatus : 24|1@0+ (1,0) [0|0] "" BCM
  SG_ FrontRightSeatStatus : 27|3@0+ (1,0) [0|0] "" BCM
  SG_ FrontLeftSeatStatus : 30|3@0+ (1,0) [0|0] "" BCM
  SG_ FrontLeftSeatDisplayStatus : 31|1@0+ (1,0) [0|0] "" BCM
  SG_ SecondRowLeftSeatAutoDisplay : 33|2@0+ (1,0) [0|0] "" BCM
  SG_ SecondRowRightSeatAutoDisplay : 35|2@0+ (1,0) [0|0] "" BCM
  SG_ FrontLeftSeatAutoDisplay : 37|2@0+ (1,0) [0|0] "" BCM
  SG_ FrontRightSeatAutoDisplay : 39|2@0+ (1,0) [0|0] "" BCM
  SG_ ThirdRowLeftSeatAutoDisplay : 41|2@0+ (1,0) [0|0] "" BCM
  SG_ ThirdRowRightSeatDisplayStatus : 42|1@0+ (1,0) [0|0] "" BCM
  SG_ ThirdRowLeftSeatDisplayStatus : 43|1@0+ (1,0) [0|0] "" BCM
  SG_ ThirdRowRightSeatAutoDisplay : 45|2@0+ (1,0) [0|0] "" BCM
  SG_ SecondRowRightSeatDisplayStatus : 46|1@0+ (1,0) [0|0] "" BCM
  SG_ SecondRowLeftSeatDisplayStatus : 47|1@0+ (1,0) [0|0] "" BCM
  SG_ ClimCabinTempDisplayUnit : 48|1@0+ (1,0) [0|0] "" BCM
  SG_ ClimLastFuncModifiedByCustomer_v2 : 55|4@0+ (1,0) [0|0] "" BCM
  SG_ ClimLinkPrioRearSeatsAutoDisp : 58|3@0+ (1,0) [0|0] "" BCM
  SG_ ClimACmaxDisplay : 63|2@0+ (1,0) [0|0] "" BCM

BO_ 1556 HPCU_A103: 8 HPCU
  SG_ HPCU_CalID1 : 7|64@0+ (1,0) [0|1.84467440737095E19] "-" BCM

BO_ 1558 IVI_A106: 6 BCM
  SG_ ClimateDriverSetting : 13|2@0+ (1,0) [0|0] "" HVAC_CU

BO_ 1562 HEVC_A132: 8 BCM
  SG_ HVFOTAConditionCheckStatus : 34|2@0+ (1,0) [0|0] "" HPCU,HVAC_CU

BO_ 1571 HEVC_A136: 8 BCM
  SG_ HVInputPowerAvailableFromBattery : 7|11@0+ (10,0) [0|15000] "W" HVAC_CU
  SG_ AvailableChargingPower_v2 : 31|12@0+ (0.05,0) [0|200] "kW" HVAC_CU
  SG_ StorageMaxPowerForBattCond : 35|10@0+ (10,0) [0|10000] "W" HVAC_CU

BO_ 1572 HEVC_R105: 7 BCM
  SG_ RER_ElecMachineSpeed_EDR : 39|12@0+ (100,-20000) [-20000|20000] "rpm" ACU
  SG_ REL_ElecMachineSpeed_EDR : 43|12@0+ (100,-20000) [-20000|20000] "rpm" ACU

BO_ 1573 HEVC_A23: 6 BCM
  SG_ OperatingTypeStatus_BLMS : 39|4@0+ (1,0) [0|0] "" HVAC_CU

BO_ 1575 USM_N104: 3 USM
  SG_ BattSens_OBD_CurrRational_Suc : 0|1@0+ (1,0) [0|0] "" BCM
  SG_ BattSens_OBD_CurrRational_Fault : 1|1@0+ (1,0) [0|0] "" BCM
  SG_ BattSens_OBD_CurrOoRLo_Success : 2|1@0+ (1,0) [0|0] "" BCM
  SG_ BattSens_OBD_CurrOoRLo_Fault : 3|1@0+ (1,0) [0|0] "" BCM
  SG_ BattSens_OBD_CurrOoRHi_Success : 4|1@0+ (1,0) [0|0] "" BCM
  SG_ BattSens_OBD_CurrOoRHi_Fault : 5|1@0+ (1,0) [0|0] "" BCM
  SG_ BattSens_OBD_CurrOC_Success : 6|1@0+ (1,0) [0|0] "" BCM
  SG_ BattSens_OBD_CurrOC_Fault : 7|1@0+ (1,0) [0|0] "" BCM
  SG_ BattSensLostComFail_OBD_Success : 8|1@0+ (1,0) [0|0] "" BCM
  SG_ BattSensLostComFail_OBD_Fault : 9|1@0+ (1,0) [0|0] "" BCM
  SG_ BattSens_OBD_TempOoRLo_Success : 10|1@0+ (1,0) [0|0] "" BCM
  SG_ BattSens_OBD_TempOoRLo_Fault : 11|1@0+ (1,0) [0|0] "" BCM
  SG_ BattSens_OBD_TempOoRHi_Success : 12|1@0+ (1,0) [0|0] "" BCM
  SG_ BattSens_OBD_TempOoRHi_Fault : 13|1@0+ (1,0) [0|0] "" BCM
  SG_ BattSens_OBD_TempOC_Success : 14|1@0+ (1,0) [0|0] "" BCM
  SG_ BattSens_OBD_TempOC_Fault : 15|1@0+ (1,0) [0|0] "" BCM
  SG_ BattVoltMeas_OBDRational_Suc : 16|1@0+ (1,0) [0|0] "" BCM
  SG_ BattVoltMeas_OBDRational_Fault : 17|1@0+ (1,0) [0|0] "" BCM
  SG_ BattVoltMeas_OBDOPEN_Success : 18|1@0+ (1,0) [0|0] "" BCM
  SG_ BattVoltMeas_OBDOPEN_Fault : 19|1@0+ (1,0) [0|0] "" BCM
  SG_ BattVoltMeas_OBDOoRLo_Success : 20|1@0+ (1,0) [0|0] "" BCM
  SG_ BattVoltMeas_OBDOoRLo_Fault : 21|1@0+ (1,0) [0|0] "" BCM
  SG_ BattVoltMeas_OBDOoRHi_Success : 22|1@0+ (1,0) [0|0] "" BCM
  SG_ BattVoltMeas_OBDOoRHi_Fault : 23|1@0+ (1,0) [0|0] "" BCM

BO_ 1585 HEVC_A112: 8 BCM
  SG_ HybridTractionMode : 10|3@0+ (1,0) [0|0] "" HVAC_CU

BO_ 1589 USM_N102: 8 USM
  SG_ USM_CalID1 : 7|64@0+ (1,0) [0|1.84467440737095E19] "-" BCM

BO_ 1592 HVAC_A107: 8 HVAC_CU
  SG_ HVpowerRequest_HVAC : 0|1@0+ (1,0) [0|0] "" BCM
  SG_ HVbatteryWaterPumpRequest_HVAC : 7|7@0+ (1.25,0) [0|150] "l/min" BCM
  SG_ ME_HeatWaterRequest : 15|10@0+ (10,0) [0|10000] "W" BCM
  SG_ ValveBattStatus : 17|2@0+ (1,0) [0|0] "" BCM
  SG_ HVbatConditioningMode : 21|4@0+ (1,0) [0|0] "" BCM
  SG_ HeatingBattery_HVACmode : 25|2@0+ (1,0) [0|0] "" BCM
  SG_ DeIcing_HVACmode : 27|2@0+ (1,0) [0|0] "" BCM
  SG_ CoolingBattery_HVACmode : 29|2@0+ (1,0) [0|0] "" BCM
  SG_ CabinCondDuringCharge_HVACmode : 31|2@0+ (1,0) [0|0] "" BCM
  SG_ HVbatHeater_Power : 34|9@0+ (10,0) [0|5000] "W" BCM
  SG_ TractionBatteryCoolingLimited : 35|1@0+ (1,0) [0|0] "" BCM
  SG_ PresoakImmediate_HVACmode : 37|2@0+ (1,0) [0|0] "" BCM
  SG_ PreConditioningBattery_HVACmode : 39|2@0+ (1,0) [0|0] "" BCM
  SG_ eAC_RevCapStatus : 41|2@0+ (1,0) [0|0] "" BCM
  SG_ OutletAirEvaporatorTempValue : 55|8@0+ (1,-40) [-40|105] "degC" BCM
  SG_ EVBattDiag : 57|2@0+ (1,0) [0|0] "" BCM
  SG_ BattCoolingDiag : 59|2@0+ (1,0) [0|0] "" BCM
  SG_ EVLinStatus : 60|1@0+ (1,0) [0|0] "" BCM
  SG_ EVBattStatus : 61|1@0+ (1,0) [0|0] "" BCM
  SG_ IRStateDisplay : 63|2@0+ (1,0) [0|0] "" BCM

BO_ 1601 RemoteFunctionService_DOP_TCU_Frame: 8 BCM
  SG_ RemoteFunctionService_DOP_TCU : 7|64@0+ (1,0) [0|0] "" HFM

BO_ 1602 RemoteFunctionService_HFM_DOPRES_Frame: 8 HFM
  SG_ RemoteFunctionService_HFM_DOPRES : 7|64@0+ (1,0) [0|0] "" BCM

BO_ 1613 CGW_A101: 1 BCM
  SG_ FOTA_ReadyToSleep : 7|1@0+ (1,0) [0|0] "" USM

BO_ 1616 SONAR_A122: 2 BCM
  SG_ APA_CancelReason2 : 1|2@0+ (1,0) [0|0] "" ACU

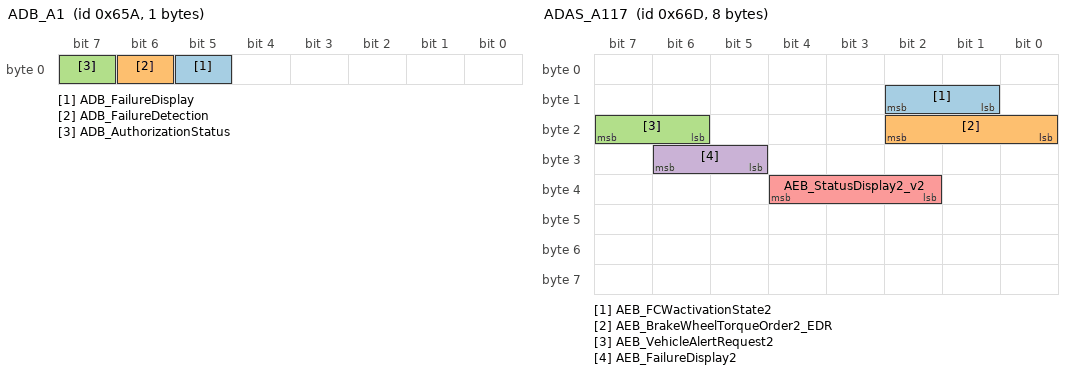
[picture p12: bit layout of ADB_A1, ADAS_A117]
BO_ 1626 ADB_A1: 1 LCU_ADB
  SG_ ADB_FailureDisplay : 5|1@0+ (1,0) [0|0] "" BCM
  SG_ ADB_FailureDetection : 6|1@0+ (1,0) [0|0] "" BCM,USM
  SG_ ADB_AuthorizationStatus : 7|1@0+ (1,0) [0|0] "" BCM

BO_ 1637 CDM_A112: 8 BCM
  SG_ MultiDriveMode_ADB : 39|3@0+ (1,0) [0|0] "" LCU_ADB
  SG_ MultiDriveMode_HVAC : 44|3@0+ (1,0) [0|0] "" HVAC_CU

BO_ 1639 HEVC_A113: 8 BCM
  SG_ ChargingPlugStatus : 0|1@0+ (1,0) [0|0] "" HVAC_CU

BO_ 1640 HEVC_A114: 8 BCM
  SG_ ChargeSpotPowerLevel : 43|9@0+ (0.3,0) [0|150] "kW" HVAC_CU

BO_ 1645 ADAS_A117: 8 BCM
  SG_ AEB_FCWactivationState2 : 10|2@0+ (1,0) [0|0] "" ACU
  SG_ AEB_BrakeWheelTorqueOrder2_EDR : 18|3@0+ (1,0) [0|0] "" ACU
  SG_ AEB_VehicleAlertRequest2 : 23|2@0+ (1,0) [0|0] "" ACU
  SG_ AEB_FailureDisplay2 : 30|2@0+ (1,0) [0|0] "" ACU
  SG_ AEB_StatusDisplay2_v2 : 36|3@0+ (1,0) [0|0] "" ACU

BO_ 1656 HPCU_A104: 8 HPCU
  SG_ HPCU_CalID2 : 7|64@0+ (1,0) [0|1.84467440737095E19] "-" BCM

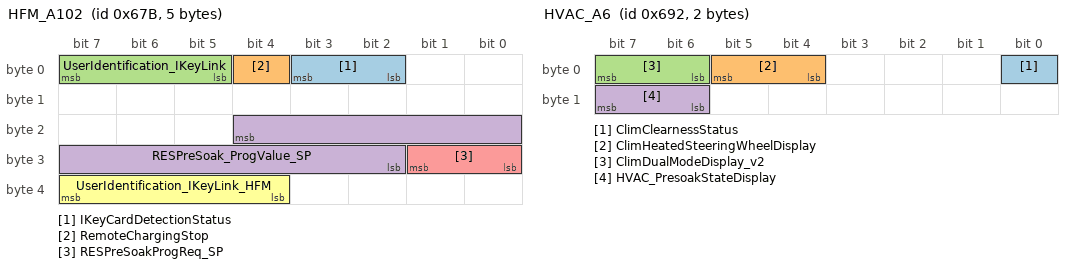
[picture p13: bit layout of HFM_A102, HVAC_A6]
BO_ 1659 HFM_A102: 5 HFM
  SG_ IKeyCardDetectionStatus : 3|2@0+ (1,0) [0|0] "" BCM
  SG_ RemoteChargingStop : 4|1@0+ (1,0) [0|0] "" BCM
  SG_ UserIdentification_IKeyLink : 7|3@0+ (1,0) [0|0] "" BCM,HVAC_CU
  SG_ RESPreSoak_ProgValue_SP : 20|11@0+ (1,0) [0|1440] "min" BCM
  SG_ RESPreSoakProgReq_SP : 25|2@0+ (1,0) [0|0] "" BCM
  SG_ UserIdentification_IKeyLink_HFM : 39|4@0+ (1,0) [0|0] "" BCM

BO_ 1660 HVAC_A102: 8 HVAC_CU
  SG_ RearSeatsLockStatus : 1|2@0+ (1,0) [0|0] "" BCM
  SG_ SecondRowRightSeatStatus : 4|3@0+ (1,0) [0|0] "" BCM
  SG_ SecondRowLeftSeatStatus : 7|3@0+ (1,0) [0|0] "" BCM
  SG_ ClimAutoRecyclingDisplayStatus : 8|1@0+ (1,0) [0|0] "" BCM
  SG_ ClimACDisplayStatus : 9|1@0+ (1,0) [0|0] "" BCM
  SG_ ThirdRowRightSeatStatus : 12|3@0+ (1,0) [0|0] "" BCM
  SG_ ThirdRowLeftSeatStatus : 15|3@0+ (1,0) [0|0] "" BCM
  SG_ ClimEVHeaterDisplayStatus : 16|1@0+ (1,0) [0|0] "" BCM
  SG_ ClimDriverZoneDisplayStatus : 17|1@0+ (1,0) [0|0] "" BCM
  SG_ ClimDriverZoneDisplay : 19|2@0+ (1,0) [0|0] "" BCM
  SG_ ClimClearnessDisplayStatus : 20|1@0+ (1,0) [0|0] "" BCM
  SG_ ClimBlowingLevelDisplayStatus : 21|1@0+ (1,0) [0|0] "" BCM
  SG_ ClimBlowingAutoDisplay : 23|2@0+ (1,0) [0|0] "" BCM
  SG_ ClimHumidityDisplayStatus : 24|1@0+ (1,0) [0|0] "" BCM
  SG_ ClimForestSettingDisplayStatus : 25|1@0+ (1,0) [0|0] "" BCM
  SG_ ClimForestDisplayStatus : 26|1@0+ (1,0) [0|0] "" BCM
  SG_ ClimForestDisplay : 28|2@0+ (1,0) [0|0] "" BCM
  SG_ ClimFlowDistrDisplayStatus : 29|1@0+ (1,0) [0|0] "" BCM
  SG_ ClimEVHeaterDisplay : 31|2@0+ (1,0) [0|0] "" BCM
  SG_ ClimLinkDefrostAndClearnesDisp : 33|2@0+ (1,0) [0|0] "" BCM
  SG_ ClimHumiditySensorSensitivDisp : 36|3@0+ (1,0) [0|0] "" BCM
  SG_ ClimHumidityDisplay : 39|3@0+ (1,0) [0|0] "" BCM
  SG_ ClimRightAutoDisplay : 41|2@0+ (1,0) [0|0] "" BCM
  SG_ ClimOFFModeDisplayStatus : 42|1@0+ (1,0) [0|0] "" BCM
  SG_ ClimLinkMaxFanSpeedAutoDisplay : 45|3@0+ (1,0) [0|0] "" BCM
  SG_ ClimLinkFreshRecyAndAutoDisplay : 47|2@0+ (1,0) [0|0] "" BCM
  SG_ ClimRightFlowDistrDisplayStatus : 48|1@0+ (1,0) [0|0] "" BCM
  SG_ ClimRightBlowingLevelDispStatus : 49|1@0+ (1,0) [0|0] "" BCM
  SG_ ClimRightBlowingLevelDisplay : 53|4@0+ (1,0) [0|0] "" BCM
  SG_ ClimRightBlowingAutoDisplay : 55|2@0+ (1,0) [0|0] "" BCM
  SG_ ClimTempDisplayStatus : 56|1@0+ (1,0) [0|0] "" BCM
  SG_ ClimSyncDisplayStatus : 57|1@0+ (1,0) [0|0] "" BCM
  SG_ ClimSyncDisplay : 59|2@0+ (1,0) [0|0] "" BCM
  SG_ ClimRightTempDisplayStatus : 60|1@0+ (1,0) [0|0] "" BCM
  SG_ ClimRightFlowDistrDisplay : 63|3@0+ (1,0) [0|0] "" BCM

BO_ 1662 IVI_A102: 8 BCM
  SG_ SecondRowRightSeatRequest : 11|4@0+ (1,0) [0|0] "" HVAC_CU
  SG_ SecondRowLeftSeatRequest : 15|4@0+ (1,0) [0|0] "" HVAC_CU
  SG_ ThirdRowRightSeatRequest : 19|4@0+ (1,0) [0|0] "" HVAC_CU
  SG_ ThirdRowLeftSeatRequest : 23|4@0+ (1,0) [0|0] "" HVAC_CU
  SG_ ClimClearnessPush : 24|1@0+ (1,0) [0|1] "-" HVAC_CU
  SG_ ClimACPush : 25|1@0+ (1,0) [0|1] "-" HVAC_CU
  SG_ RearSeatsLockRequest : 31|2@0+ (1,0) [0|0] "" HVAC_CU
  SG_ ClimHumiditySensorSensitivitReq : 34|3@0+ (1,0) [0|0] "" HVAC_CU
  SG_ ClimForestPush : 35|1@0+ (1,0) [0|1] "" HVAC_CU
  SG_ ClimForcedRecyclingPush : 36|1@0+ (1,0) [0|1] "-" HVAC_CU
  SG_ ClimForcedFreshPush : 37|1@0+ (1,0) [0|1] "-" HVAC_CU
  SG_ ClimEVHeaterPush : 38|1@0+ (1,0) [0|1] "-" HVAC_CU
  SG_ ClimDriverZonePush : 39|1@0+ (1,0) [0|1] "" HVAC_CU
  SG_ ClimRightFlowDistrDefPush : 40|1@0+ (1,0) [0|1] "-" HVAC_CU
  SG_ TimeFormatDisplay : 43|1@0+ (1,0) [0|0] "" HVAC_CU
  SG_ ClimFPrightBlowingRequest : 47|4@0+ (1,0) [0|0] "" HVAC_CU
  SG_ ClimRightFlowDistrVentPush : 48|1@0+ (1,0) [0|1] "-" HVAC_CU
  SG_ ClimRightFlowDistrFeetPush : 49|1@0+ (1,0) [0|1] "-" HVAC_CU
  SG_ ClimLinkPriorityFLSeatAutoReq : 52|3@0+ (1,0) [0|0] "" HVAC_CU
  SG_ ClimLinkMaxFanSpeedAutoReq : 55|3@0+ (1,0) [0|0] "" HVAC_CU
  SG_ ClimLinkDefrostAndClearnesPush : 56|1@0+ (1,0) [0|1] "" HVAC_CU
  SG_ ClimRightAutoNormalPush : 57|1@0+ (1,0) [0|1] "-" HVAC_CU
  SG_ FrontRightSeatAutoPush : 58|1@0+ (1,0) [0|1] "-" HVAC_CU
  SG_ FrontLeftSeatAutoPush : 59|1@0+ (1,0) [0|1] "-" HVAC_CU
  SG_ ClimSyncPush : 60|1@0+ (1,0) [0|1] "-" HVAC_CU
  SG_ ClimLinkPriorityFRSeatAutoReq : 63|3@0+ (1,0) [0|0] "" HVAC_CU

BO_ 1663 USM_N105: 8 USM
  SG_ USM_CVN : 7|64@0+ (1,0) [0|1.84467440737095E19] "-" BCM

BO_ 1670 IVI_A130: 8 BCM
  SG_ AnimationPatternRequest : 4|4@0+ (1,0) [0|0] "" USM

BO_ 1671 USM_A106: 1 USM
  SG_ AnimationPatternState : 7|4@0+ (1,0) [0|0] "" BCM

BO_ 1673 RemoteFunctionService_DOP_RES_Frame: 8 BCM
  SG_ RemoteFunctionService_DOP_RES : 7|64@0+ (1,0) [0|0] "" HFM

BO_ 1676 HFM_SGW_pairing_Frame: 8 HFM
  SG_ HFM_SGW_pairing : 7|64@0+ (1,0) [0|0] "" BCM

BO_ 1680 ParkOut_HFM_Frame: 3 HFM
  SG_ ParkOutCode : 7|16@0+ (1,0) [0|65535] "" BCM
  SG_ ParkOutCommand : 23|2@0+ (1,0) [0|0] "" BCM

BO_ 1682 HVAC_A6: 2 HVAC_CU
  SG_ ClimClearnessStatus : 0|1@0+ (1,0) [0|0] "" BCM
  SG_ ClimHeatedSteeringWheelDisplay : 5|2@0+ (1,0) [0|0] "" BCM
  SG_ ClimDualModeDisplay_v2 : 7|2@0+ (1,0) [0|0] "" BCM
  SG_ HVAC_PresoakStateDisplay : 15|2@0+ (1,0) [0|0] "" BCM

BO_ 1683 HPCU_A105: 8 HPCU
  SG_ CONDOutletTemperatureValue : 7|8@0+ (1,-40) [-40|105] "degC" BCM
  SG_ PressureSuction_Sens_Diag : 10|3@0+ (1,0) [0|0] "" BCM
  SG_ COND_Out_Temp_Sens_Diag : 13|3@0+ (1,0) [0|0] "" BCM
  SG_ COND_Out_Temp_Sens_Diag_Status : 15|2@0+ (1,0) [0|0] "" BCM
  SG_ PessureSuction_Value : 23|9@0+ (0.1,0) [0|51] "bar" BCM
  SG_ EXVBattCoolingDiag : 25|2@0+ (1,0) [0|0] "" BCM
  SG_ WaterCondInletTempDiag : 28|3@0+ (1,0) [0|0] "" BCM
  SG_ PressureSuction_Sens_Diag_Status : 30|2@0+ (1,0) [0|0] "" BCM
  SG_ EXVEvapoDiag : 33|2@0+ (1,0) [0|0] "" BCM
  SG_ InnerCondInletTempDiag : 36|3@0+ (1,0) [0|0] "" BCM
  SG_ WaterCondOutletTempDiag : 39|3@0+ (1,0) [0|0] "" BCM
  SG_ EVHeatingModeDiag : 42|2@0+ (1,0) [0|0] "" BCM
  SG_ EXVHeatingDiag : 44|2@0+ (1,0) [0|0] "" BCM
  SG_ InnerCondOutletTempDiag : 47|3@0+ (1,0) [0|0] "" BCM
  SG_ EVDehumidificationDiag : 49|2@0+ (1,0) [0|0] "" BCM
  SG_ HVACLossLinCom_HPCU : 51|2@0+ (1,0) [0|0] "" BCM
  SG_ HEVCLossCanCom_HPCU : 53|2@0+ (1,0) [0|0] "" BCM
  SG_ MeterLossCanCom_HPCU : 55|2@0+ (1,0) [0|0] "" BCM
  SG_ eEPR_Diag : 60|3@0+ (1,0) [0|0] "" BCM
  SG_ TsSensorDiag_HPCU : 63|3@0+ (1,0) [0|0] "" BCM

BO_ 1684 AVM_A118: 3 BCM
  SG_ HFP_MapContentDisplay2 : 10|2@0+ (1,0) [0|0] "" ACU
  SG_ RPES_Authorized : 23|1@0+ (1,0) [0|0] "" HFM

BO_ 1685 CGW_A2: 4 BCM
  SG_ FOTAConditionCheckRequest : 12|2@0+ (1,0) [0|0] "" HFM

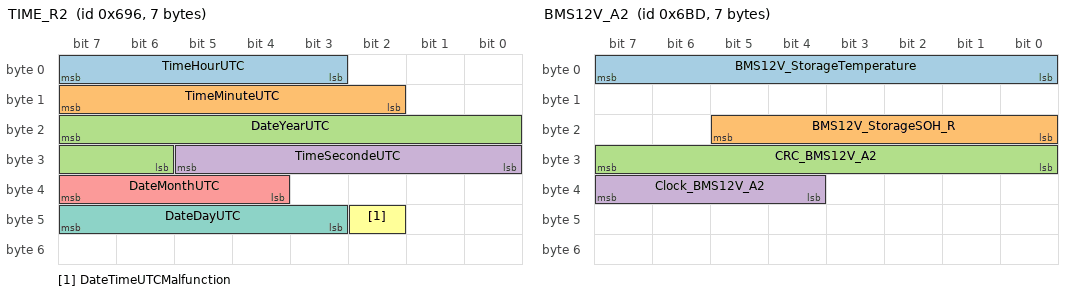
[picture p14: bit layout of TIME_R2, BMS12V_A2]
BO_ 1686 TIME_R2: 7 BCM
  SG_ TimeHourUTC : 7|5@0+ (1,0) [0|23] "h" ACU
  SG_ TimeMinuteUTC : 15|6@0+ (1,0) [0|59] "min" ACU
  SG_ DateYearUTC : 23|10@0+ (1,2000) [2000|3000] "year" ACU
  SG_ TimeSecondeUTC : 29|6@0+ (1,0) [0|59] "s" ACU
  SG_ DateMonthUTC : 39|4@0+ (1,0) [0|12] "month" ACU
  SG_ DateTimeUTCMalfunction : 42|1@0+ (1,0) [0|0] "" ACU
  SG_ DateDayUTC : 47|5@0+ (1,0) [0|31] "day" ACU

BO_ 1694 SGW_HFM_pairing_Frame: 8 BCM
  SG_ SGW_HFM_pairing : 7|64@0+ (1,0) [0|0] "" HFM

BO_ 1695 VehicleID_CANHS_R_01: 4 BCM
  SG_ VehicleID : 7|32@0+ (1,0) [0|0] "" ACU

BO_ 1710 RemoteFunctionService_HFM_DOPTCU_Frame: 8 HFM
  SG_ RemoteFunctionService_HFM_DOPTCU : 7|64@0+ (1,0) [0|0] "" BCM

BO_ 1720 METER_UserSetPref_A6: 3 BCM
  SG_ HandDrivingActivationRequest : 17|2@0+ (1,0) [0|0] "" USM

BO_ 1722 RemoteFunctionService_SGW_Frame: 8 BCM
  SG_ RemoteFunctionService_SGW : 7|64@0+ (1,0) [0|0] "" HFM

BO_ 1725 BMS12V_A2: 7 BCM
  SG_ BMS12V_StorageTemperature : 7|8@0+ (0.5,-45) [-45|80] "°C" USM
  SG_ BMS12V_StorageSOH_R : 21|6@0+ (1,100) [100|160] "%" USM
  SG_ CRC_BMS12V_A2 : 31|8@0+ (1,0) [0|255] "" USM
  SG_ Clock_BMS12V_A2 : 39|4@0+ (1,0) [0|15] "" USM

BO_ 1730 ECM_A120: 6 BCM
  SG_ PulseRecordingRequest : 34|1@0+ (1,0) [0|0] "" USM

BO_ 1737 HEVC_A22: 8 BCM
  SG_ HVBatteryTempMin_BLMS : 7|7@0+ (1,-40) [-40|80] "°C" HVAC_CU
  SG_ HVBatteryTempMax_BLMS : 23|7@0+ (1,-40) [-40|80] "°C" HVAC_CU

BO_ 1741 METER_A102: 8 BCM
  SG_ BatteryCool_eACLimitStatus : 47|2@0+ (1,0) [0|0] "" HVAC_CU

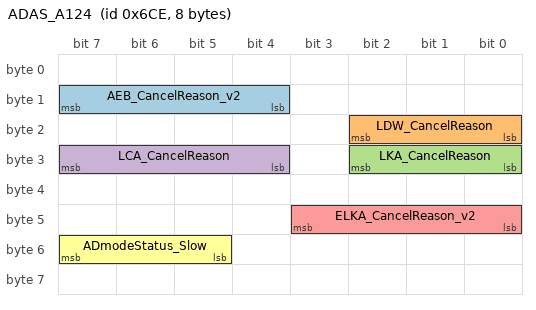
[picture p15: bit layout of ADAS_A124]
BO_ 1742 ADAS_A124: 8 BCM
  SG_ AEB_CancelReason_v2 : 15|4@0+ (1,0) [0|0] "" ACU
  SG_ LDW_CancelReason : 18|3@0+ (1,0) [0|0] "" ACU
  SG_ LKA_CancelReason : 26|3@0+ (1,0) [0|0] "" ACU
  SG_ LCA_CancelReason : 31|4@0+ (1,0) [0|0] "" ACU
  SG_ ELKA_CancelReason_v2 : 43|4@0+ (1,0) [0|0] "" ACU
  SG_ ADmodeStatus_Slow : 55|3@0+ (1,0) [0|0] "" ACU

BO_ 1748 HFM_VKM_pairing_Frame: 8 HFM
  SG_ HFM_VKM_pairing : 7|64@0+ (1,0) [0|0] "" BCM

BO_ 1749 VKM_N112: 8 BCM
  SG_ VKM_HFM_pairing : 7|64@0+ (1,0) [0|0] "" HFM

BO_ 1755 HEVC_A111: 8 BCM
  SG_ DCDCWaterTemp_BLMS : 7|8@0+ (1,-40) [-40|214] "°" HVAC_CU
  SG_ HVB_TempMinStopHeating : 39|7@0+ (1,-40) [-40|80] "°C" HVAC_CU

BO_ 1789 BCM_A114: 8 BCM
  SG_ ADB_RemoteLightingRequest : 5|1@0+ (1,0) [0|0] "" LCU_ADB
  SG_ RESPreSoak_NextDriverArrivalTime_v2 : 13|14@0+ (1,0) [0|10080] "min" HVAC_CU

BO_ 1860 DTOOL_to_HVAC: 8 BCM
  SG_ DTOOL_to_HVAC : 7|64@0+ (1,0) [0|0] "" HVAC_CU

BO_ 1869 DTOOL_to_USM: 8 BCM
  SG_ DTOOL_to_USM : 7|64@0+ (1,0) [0|0] "" USM

BO_ 1874 DTOOL_to_ACU: 8 BCM
  SG_ DTOOL_to_ACU : 7|64@0+ (1,0) [0|0] "" ACU

BO_ 1884 DTOOL_to_AFS: 8 BCM
  SG_ DTOOL_to_AFS : 7|64@0+ (1,0) [0|0] "" LCU_MBL

BO_ 1892 HVAC_to_DTOOL: 8 HVAC_CU
  SG_ HVAC_to_DTOOL : 7|64@0+ (1,0) [0|0] "" BCM

BO_ 1901 USM_to_DTOOL: 8 USM
  SG_ USM_to_DTOOL : 7|64@0+ (1,0) [0|0] "" BCM

BO_ 1906 ACU_to_DTOOL: 8 ACU
  SG_ ACU_to_DTOOL : 7|64@0+ (1,0) [0|0] "" BCM

BO_ 1916 AFS_to_DTOOL: 8 LCU_MBL
  SG_ AFS_to_DTOOL : 7|64@0+ (1,0) [0|0] "" BCM

BO_ 1945 DTOOL_to_HFM: 8 BCM
  SG_ DTOOL_to_HFM : 7|64@0+ (1,0) [0|0] "" HFM

BO_ 1977 HFM_to_DTOOL: 8 HFM
  SG_ HFM_to_DTOOL : 7|64@0+ (1,0) [0|0] "" BCM

BO_ 2033 Scrap_AuthorizationRequestFrame: 8 BCM
  SG_ Scrap_AuthorizationRequest : 7|64@0+ (1,0) [0|0] "" ACU

BO_ 2041 Scrap_AuthorizationStatusFrame: 8 ACU
  SG_ Scrap_AuthorizationStatus : 7|64@0+ (1,0) [0|0] "" BCM

BO_ 2563507968 SIGMA_CDMTriggerFrame: 7 BCM
  SG_ SIGMA_CDM : 4|29@0+ (1,0) [0|0] "" ACU,HFM,HPCU,HVAC_CU,USM,eRDC_L,eRDC_R
  SG_ SIGMA_DTCCDM : 39|24@0+ (1,0) [0|0] "" ACU,HFM,HPCU,HVAC_CU,USM,eRDC_L,eRDC_R

BO_ 2563508007 SIGMA_eHBoxTriggerFrame: 7 BCM
  SG_ SIGMA_eHBox : 4|29@0+ (1,0) [0|0] "" ACU,HFM,HPCU,HVAC_CU,USM,eRDC_L,eRDC_R
  SG_ SIGMA_DTCeHBox : 39|24@0+ (1,0) [0|0] "" ACU,HFM,HPCU,HVAC_CU,USM,eRDC_L,eRDC_R

BO_ 2563508009 SIGMA_PSD_RTriggerFrame: 7 BCM
  SG_ SIGMA_PSD_R : 4|29@0+ (1,0) [0|0] "" ACU,HFM,HPCU,HVAC_CU,USM,eRDC_L,eRDC_R
  SG_ SIGMA_DTCPSD_R : 39|24@0+ (1,0) [0|0] "" ACU,HFM,HPCU,HVAC_CU,USM,eRDC_L,eRDC_R

BO_ 2563508019 SIGMA_PBDTriggerFrame: 7 BCM
  SG_ SIGMA_PBD : 4|29@0+ (1,0) [0|0] "" ACU,HFM,HPCU,HVAC_CU,USM,eRDC_L,eRDC_R
  SG_ SIGMA_DTCPBD : 39|24@0+ (1,0) [0|0] "" ACU,HFM,HPCU,HVAC_CU,USM,eRDC_L,eRDC_R

BO_ 2563508021 SIGMA_RADARTriggerFrame: 7 BCM
  SG_ SIGMA_RADAR : 4|29@0+ (1,0) [0|0] "" ACU,HFM,HPCU,HVAC_CU,USM,eRDC_L,eRDC_R
  SG_ SIGMA_DTCRADAR : 39|24@0+ (1,0) [0|0] "" ACU,HFM,HPCU,HVAC_CU,USM,eRDC_L,eRDC_R

BO_ 2563508022 SIGMA_PSCUTriggerFrame: 7 BCM
  SG_ SIGMA_PSCU : 4|29@0+ (1,0) [0|0] "" ACU,HFM,HPCU,HVAC_CU,USM,eRDC_L,eRDC_R
  SG_ SIGMA_DTCPSCU : 39|24@0+ (1,0) [0|0] "" ACU,HFM,HPCU,HVAC_CU,USM,eRDC_L,eRDC_R

BO_ 2563508030 SIGMA_SRad_RLTriggerFrame: 7 BCM
  SG_ SIGMA_SRad_RL : 4|29@0+ (1,0) [0|0] "" ACU,HFM,HPCU,HVAC_CU,USM,eRDC_L,eRDC_R
  SG_ SIGMA_DTCSRad_RL : 39|24@0+ (1,0) [0|0] "" ACU,HFM,HPCU,HVAC_CU,USM,eRDC_L,eRDC_R

BO_ 2563508035 SIGMA_eRDC_LTriggerFrame: 7 eRDC_L
  SG_ SIGMA_eRDC_L : 4|29@0+ (1,0) [0|0] "" ACU,BCM,HFM,HPCU,HVAC_CU,USM,eRDC_R
  SG_ SIGMA_DTCeRDC_L : 39|24@0+ (1,0) [0|0] "" ACU,BCM,HFM,HPCU,HVAC_CU,USM,eRDC_R

BO_ 2563508037 SIGMA_eRDC_RTriggerFrame: 7 eRDC_R
  SG_ SIGMA_eRDC_R : 4|29@0+ (1,0) [0|0] "" ACU,BCM,HFM,HPCU,HVAC_CU,USM,eRDC_L
  SG_ SIGMA_DTCeRDC_R : 39|24@0+ (1,0) [0|0] "" ACU,BCM,HFM,HPCU,HVAC_CU,USM,eRDC_L

BO_ 2563508042 SIGMA_ANCTriggerFrame: 7 BCM
  SG_ SIGMA_ANC : 4|29@0+ (1,0) [0|0] "" ACU,HFM,HPCU,HVAC_CU,USM,eRDC_L,eRDC_R
  SG_ SIGMA_DTCANC : 39|24@0+ (1,0) [0|0] "" ACU,HFM,HPCU,HVAC_CU,USM,eRDC_L,eRDC_R

BO_ 2563508064 SIGMA_VDCTriggerFrame: 7 BCM
  SG_ SIGMA_VDC : 4|29@0+ (1,0) [0|0] "" ACU,HFM,HPCU,HVAC_CU,USM,eRDC_L,eRDC_R
  SG_ SIGMA_DTCVDC : 39|24@0+ (1,0) [0|0] "" ACU,HFM,HPCU,HVAC_CU,USM,eRDC_L,eRDC_R

BO_ 2563508066 SIGMA_EPSTriggerFrame: 7 BCM
  SG_ SIGMA_EPS : 4|29@0+ (1,0) [0|0] "" ACU,HFM,HPCU,HVAC_CU,USM,eRDC_L,eRDC_R
  SG_ SIGMA_DTCEPS : 39|24@0+ (1,0) [0|0] "" ACU,HFM,HPCU,HVAC_CU,USM,eRDC_L,eRDC_R

BO_ 2563508067 SIGMA_METERTriggerFrame: 7 BCM
  SG_ SIGMA_METER : 4|29@0+ (1,0) [0|0] "" ACU,HFM,HPCU,HVAC_CU,USM,eRDC_L,eRDC_R
  SG_ SIGMA_DTCMETER : 39|24@0+ (1,0) [0|0] "" ACU,HFM,HPCU,HVAC_CU,USM,eRDC_L,eRDC_R

BO_ 2563508068 SIGMA_HVACTriggerFrame: 7 HVAC_CU
  SG_ SIGMA_HVAC : 4|29@0+ (1,0) [0|0] "" ACU,BCM,HFM,HPCU,USM,eRDC_L,eRDC_R
  SG_ SIGMA_DTCHVAC : 39|24@0+ (1,0) [0|0] "" ACU,BCM,HFM,HPCU,USM,eRDC_L,eRDC_R

BO_ 2563508069 SIGMA_BCMTriggerFrame: 7 BCM
  SG_ SIGMA_BCM : 4|29@0+ (1,0) [0|0] "" ACU,HFM,HPCU,HVAC_CU,USM,eRDC_L,eRDC_R
  SG_ SIGMA_DTCBCM : 39|24@0+ (1,0) [0|0] "" ACU,HFM,HPCU,HVAC_CU,USM,eRDC_L,eRDC_R

BO_ 2563508071 SIGMA_IVITriggerFrame: 7 BCM
  SG_ SIGMA_IVI : 4|29@0+ (1,0) [0|0] "" ACU,HFM,HPCU,HVAC_CU,USM,eRDC_L,eRDC_R
  SG_ SIGMA_DTCIVI : 39|24@0+ (1,0) [0|0] "" ACU,HFM,HPCU,HVAC_CU,USM,eRDC_L,eRDC_R

BO_ 2563508072 SIGMA_4WDTriggerFrame: 7 BCM
  SG_ SIGMA_4WD : 4|29@0+ (1,0) [0|0] "" ACU,HFM,HPCU,HVAC_CU,USM,eRDC_L,eRDC_R
  SG_ SIGMA_DTC4WD : 39|24@0+ (1,0) [0|0] "" ACU,HFM,HPCU,HVAC_CU,USM,eRDC_L,eRDC_R

BO_ 2563508077 SIGMA_USMTriggerFrame: 7 USM
  SG_ SIGMA_USM : 4|29@0+ (1,0) [0|0] "" ACU,BCM,HFM,HPCU,HVAC_CU,eRDC_L,eRDC_R
  SG_ SIGMA_DTCUSM : 39|24@0+ (1,0) [0|0] "" ACU,BCM,HFM,HPCU,HVAC_CU,eRDC_L,eRDC_R

BO_ 2563508078 SIGMA_SONARTriggerFrame: 7 BCM
  SG_ SIGMA_SONAR : 4|29@0+ (1,0) [0|0] "" ACU,HFM,HPCU,HVAC_CU,USM,eRDC_L,eRDC_R
  SG_ SIGMA_DTCSONAR : 39|24@0+ (1,0) [0|0] "" ACU,HFM,HPCU,HVAC_CU,USM,eRDC_L,eRDC_R

BO_ 2563508079 SIGMA_DSMUTriggerFrame: 7 BCM
  SG_ SIGMA_DSMU : 4|29@0+ (1,0) [0|0] "" ACU,HFM,HPCU,HVAC_CU,USM,eRDC_L,eRDC_R
  SG_ SIGMA_DTCDSMU : 39|24@0+ (1,0) [0|0] "" ACU,HFM,HPCU,HVAC_CU,USM,eRDC_L,eRDC_R

BO_ 2563508082 SIGMA_ACUTriggerFrame: 7 ACU
  SG_ SIGMA_ACU : 4|29@0+ (1,0) [0|0] "" BCM,HFM,HPCU,HVAC_CU,USM,eRDC_L,eRDC_R
  SG_ SIGMA_DTCACU : 39|24@0+ (1,0) [0|0] "" BCM,HFM,HPCU,HVAC_CU,USM,eRDC_L,eRDC_R

BO_ 2563508089 SIGMA_PSD_LTriggerFrame: 7 BCM
  SG_ SIGMA_PSD_L : 4|29@0+ (1,0) [0|0] "" ACU,HFM,HPCU,HVAC_CU,USM,eRDC_L,eRDC_R
  SG_ SIGMA_DTCPSD_L : 39|24@0+ (1,0) [0|0] "" ACU,HFM,HPCU,HVAC_CU,USM,eRDC_L,eRDC_R

BO_ 2563508093 SIGMA_ADASTriggerFrame: 7 BCM
  SG_ SIGMA_ADAS : 4|29@0+ (1,0) [0|0] "" ACU,HFM,HPCU,HVAC_CU,USM,eRDC_L,eRDC_R
  SG_ SIGMA_DTCADAS : 39|24@0+ (1,0) [0|0] "" ACU,HFM,HPCU,HVAC_CU,USM,eRDC_L,eRDC_R

BO_ 2563508099 SIGMA_A_IVCTriggerFrame: 7 BCM
  SG_ SIGMA_A_IVC : 4|29@0+ (1,0) [0|0] "" ACU,HFM,HPCU,HVAC_CU,USM,eRDC_L,eRDC_R
  SG_ SIGMA_DTCA_IVC : 39|24@0+ (1,0) [0|0] "" ACU,HFM,HPCU,HVAC_CU,USM,eRDC_L,eRDC_R

BO_ 2563508108 SIGMA_INV_METriggerFrame: 7 BCM
  SG_ SIGMA_INV_ME : 4|29@0+ (1,0) [0|0] "" ACU,HFM,HPCU,HVAC_CU,USM,eRDC_L,eRDC_R
  SG_ SIGMA_DTCINV_ME : 39|24@0+ (1,0) [0|0] "" ACU,HFM,HPCU,HVAC_CU,USM,eRDC_L,eRDC_R

BO_ 2563508115 SIGMA_OBC_ACTriggerFrame: 7 BCM
  SG_ SIGMA_OBC_AC : 4|29@0+ (1,0) [0|0] "" ACU,HFM,HPCU,HVAC_CU,USM,eRDC_L,eRDC_R
  SG_ SIGMA_DTCOBC_AC : 39|24@0+ (1,0) [0|0] "" ACU,HFM,HPCU,HVAC_CU,USM,eRDC_L,eRDC_R

BO_ 2563508122 SIGMA_HEVCTriggerFrame: 7 BCM
  SG_ SIGMA_HEVC : 4|29@0+ (1,0) [0|0] "" ACU,HFM,HPCU,HVAC_CU,USM,eRDC_L,eRDC_R
  SG_ SIGMA_DTCHEVC : 39|24@0+ (1,0) [0|0] "" ACU,HFM,HPCU,HVAC_CU,USM,eRDC_L,eRDC_R

BO_ 2563508130 SIGMA_AUDIOampTriggerFrame: 7 BCM
  SG_ SIGMA_AUDIOamp : 4|29@0+ (1,0) [0|0] "" ACU,HFM,HPCU,HVAC_CU,USM,eRDC_L,eRDC_R
  SG_ SIGMA_DTCAUDIOamp : 39|24@0+ (1,0) [0|0] "" ACU,HFM,HPCU,HVAC_CU,USM,eRDC_L,eRDC_R

BO_ 2563508133 SIGMA_HNSTriggerFrame: 7 BCM
  SG_ SIGMA_HNS : 4|29@0+ (1,0) [0|0] "" ACU,HFM,HPCU,HVAC_CU,USM,eRDC_L,eRDC_R
  SG_ SIGMA_DTCHNS : 39|24@0+ (1,0) [0|0] "" ACU,HFM,HPCU,HVAC_CU,USM,eRDC_L,eRDC_R

BO_ 2563508139 SIGMA_VKMTriggerFrame: 7 BCM
  SG_ SIGMA_VKM : 4|29@0+ (1,0) [0|0] "" ACU,HFM,HPCU,HVAC_CU,USM,eRDC_L,eRDC_R
  SG_ SIGMA_DTCVKM : 39|24@0+ (1,0) [0|0] "" ACU,HFM,HPCU,HVAC_CU,USM,eRDC_L,eRDC_R

BO_ 2563508153 SIGMA_HFMTriggerFrame: 7 HFM
  SG_ SIGMA_HFM : 4|29@0+ (1,0) [0|0] "" ACU,BCM,HPCU,HVAC_CU,USM,eRDC_L,eRDC_R
  SG_ SIGMA_DTCHFM : 39|24@0+ (1,0) [0|0] "" ACU,BCM,HPCU,HVAC_CU,USM,eRDC_L,eRDC_R

BO_ 2563508154 SIGMA_AVMTriggerFrame: 7 BCM
  SG_ SIGMA_AVM : 4|29@0+ (1,0) [0|0] "" ACU,HFM,HPCU,HVAC_CU,USM,eRDC_L,eRDC_R
  SG_ SIGMA_DTCAVM : 39|24@0+ (1,0) [0|0] "" ACU,HFM,HPCU,HVAC_CU,USM,eRDC_L,eRDC_R

BO_ 2563508157 SIGMA_SCUTriggerFrame: 7 BCM
  SG_ SIGMA_SCU : 4|29@0+ (1,0) [0|0] "" ACU,HFM,HPCU,HVAC_CU,USM,eRDC_L,eRDC_R
  SG_ SIGMA_DTCSCU : 39|24@0+ (1,0) [0|0] "" ACU,HFM,HPCU,HVAC_CU,USM,eRDC_L,eRDC_R

BO_ 2563508164 SIGMA_eShifterTriggerFrame: 7 BCM
  SG_ SIGMA_eShifter : 4|29@0+ (1,0) [0|0] "" ACU,HFM,HPCU,HVAC_CU,USM,eRDC_L,eRDC_R
  SG_ SIGMA_DTCeShifter : 39|24@0+ (1,0) [0|0] "" ACU,HFM,HPCU,HVAC_CU,USM,eRDC_L,eRDC_R

BO_ 2563508181 SIGMA_SRad_RRTriggerFrame: 7 BCM
  SG_ SIGMA_SRad_RR : 4|29@0+ (1,0) [0|0] "" ACU,HFM,HPCU,HVAC_CU,USM,eRDC_L,eRDC_R
  SG_ SIGMA_DTCSRad_RR : 39|24@0+ (1,0) [0|0] "" ACU,HFM,HPCU,HVAC_CU,USM,eRDC_L,eRDC_R

BO_ 2563508189 SIGMA_FrCameraTriggerFrame: 7 BCM
  SG_ SIGMA_FrCamera : 4|29@0+ (1,0) [0|0] "" ACU,HFM,HPCU,HVAC_CU,USM,eRDC_L,eRDC_R
  SG_ SIGMA_DTCFrCamera : 39|24@0+ (1,0) [0|0] "" ACU,HFM,HPCU,HVAC_CU,USM,eRDC_L,eRDC_R

BO_ 2563508200 SIGMA_ECMTriggerFrame: 7 BCM
  SG_ SIGMA_ECM : 4|29@0+ (1,0) [0|0] "" ACU,HFM,HPCU,HVAC_CU,USM,eRDC_L,eRDC_R
  SG_ SIGMA_DTCECM : 39|24@0+ (1,0) [0|0] "" ACU,HFM,HPCU,HVAC_CU,USM,eRDC_L,eRDC_R

BO_ 2563508201 SIGMA_ATCUTriggerFrame: 7 BCM
  SG_ SIGMA_ATCU : 4|29@0+ (1,0) [0|0] "" ACU,HFM,HPCU,HVAC_CU,USM,eRDC_L,eRDC_R
  SG_ SIGMA_DTCATCU : 39|24@0+ (1,0) [0|0] "" ACU,HFM,HPCU,HVAC_CU,USM,eRDC_L,eRDC_R

BO_ 2563508205 SIGMA_BMS_HVTriggerFrame: 7 BCM
  SG_ SIGMA_BMS_HV : 4|29@0+ (1,0) [0|0] "" ACU,HFM,HPCU,HVAC_CU,USM,eRDC_L,eRDC_R
  SG_ SIGMA_DTCBMS_HV : 39|24@0+ (1,0) [0|0] "" ACU,HFM,HPCU,HVAC_CU,USM,eRDC_L,eRDC_R

BO_ 2563508207 SIGMA_INV_HSGTriggerFrame: 7 BCM
  SG_ SIGMA_INV_HSG : 4|29@0+ (1,0) [0|0] "" ACU,HFM,HPCU,HVAC_CU,USM,eRDC_L,eRDC_R
  SG_ SIGMA_DTCINV_HSG : 39|24@0+ (1,0) [0|0] "" ACU,HFM,HPCU,HVAC_CU,USM,eRDC_L,eRDC_R

BO_ 2563567883 SIGMA_BMS_12VTriggerFrame: 7 BCM
  SG_ SIGMA_BMS_12V : 4|29@0+ (1,0) [0|0] "" ACU,HFM,HPCU,HVAC_CU,USM,eRDC_L,eRDC_R
  SG_ SIGMA_DTCBMS_12V : 39|24@0+ (1,0) [0|0] "" ACU,HFM,HPCU,HVAC_CU,USM,eRDC_L,eRDC_R

BO_ 2563567951 SIGMA_EPS_subTriggerFrame: 7 BCM
  SG_ SIGMA_EPS_sub : 4|29@0+ (1,0) [0|0] "" ACU,HFM,HPCU,HVAC_CU,USM,eRDC_L,eRDC_R
  SG_ SIGMA_DTCEPS_sub : 39|24@0+ (1,0) [0|0] "" ACU,HFM,HPCU,HVAC_CU,USM,eRDC_L,eRDC_R

BO_ 2563567958 SIGMA_eShiftActTriggerFrame: 7 BCM
  SG_ SIGMA_eShiftAct : 4|29@0+ (1,0) [0|0] "" ACU,HFM,HPCU,HVAC_CU,USM,eRDC_L,eRDC_R
  SG_ SIGMA_DTCeShiftAct : 39|24@0+ (1,0) [0|0] "" ACU,HFM,HPCU,HVAC_CU,USM,eRDC_L,eRDC_R

BO_ 2563567968 SIGMA_HUDTriggerFrame: 7 BCM
  SG_ SIGMA_HUD : 4|29@0+ (1,0) [0|0] "" ACU,HFM,HPCU,HVAC_CU,USM,eRDC_L,eRDC_R
  SG_ SIGMA_DTCHUD : 39|24@0+ (1,0) [0|0] "" ACU,HFM,HPCU,HVAC_CU,USM,eRDC_L,eRDC_R

BO_ 2563568024 SIGMA_HPCUTriggerFrame: 7 HPCU
  SG_ SIGMA_HPCU : 4|29@0+ (1,0) [0|0] "" ACU,BCM,HFM,HVAC_CU,USM,eRDC_L,eRDC_R
  SG_ SIGMA_DTCHPCU : 39|24@0+ (1,0) [0|0] "" ACU,BCM,HFM,HVAC_CU,USM,eRDC_L,eRDC_R

BO_ 2563568093 SIGMA_DCDC_HVTriggerFrame: 7 BCM
  SG_ SIGMA_DCDC_HV : 4|29@0+ (1,0) [0|0] "" ACU,HFM,HPCU,HVAC_CU,USM,eRDC_L,eRDC_R
  SG_ SIGMA_DTCDCDC_HV : 39|24@0+ (1,0) [0|0] "" ACU,HFM,HPCU,HVAC_CU,USM,eRDC_L,eRDC_R

BO_ 2563568098 SIGMA_EBATriggerFrame: 7 BCM
  SG_ SIGMA_EBA : 4|29@0+ (1,0) [0|0] "" ACU,HFM,HPCU,HVAC_CU,USM,eRDC_L,eRDC_R
  SG_ SIGMA_DTCEBA : 39|24@0+ (1,0) [0|0] "" ACU,HFM,HPCU,HVAC_CU,USM,eRDC_L,eRDC_R

BO_ 2563568101 SIGMA_INV_RETriggerFrame: 7 BCM
  SG_ SIGMA_INV_RE : 4|29@0+ (1,0) [0|0] "" ACU,HFM,HPCU,HVAC_CU,USM,eRDC_L,eRDC_R
  SG_ SIGMA_DTCINV_RE : 39|24@0+ (1,0) [0|0] "" ACU,HFM,HPCU,HVAC_CU,USM,eRDC_L,eRDC_R

BO_ 2563568130 SIGMA_AirSUSPTriggerFrame: 7 BCM
  SG_ SIGMA_AirSUSP : 4|29@0+ (1,0) [0|0] "" ACU,HFM,HPCU,HVAC_CU,USM,eRDC_L,eRDC_R
  SG_ SIGMA_DTCAirSUSP : 39|24@0+ (1,0) [0|0] "" ACU,HFM,HPCU,HVAC_CU,USM,eRDC_L,eRDC_R

BO_ 2563568148 SIGMA_BSGTriggerFrame: 7 BCM
  SG_ SIGMA_BSG : 4|29@0+ (1,0) [0|0] "" ACU,HFM,HPCU,HVAC_CU,USM,eRDC_L,eRDC_R
  SG_ SIGMA_DTCBSG : 39|24@0+ (1,0) [0|0] "" ACU,HFM,HPCU,HVAC_CU,USM,eRDC_L,eRDC_R

BO_ 2563568163 SIGMA_SRad_FL_TriggerFrame: 7 BCM
  SG_ SIGMA_SRad_FL : 4|29@0+ (1,0) [0|0] "" ACU,HFM,HPCU,HVAC_CU,USM,eRDC_L,eRDC_R
  SG_ SIGMA_DTCSRad_FL : 39|24@0+ (1,0) [0|0] "" ACU,HFM,HPCU,HVAC_CU,USM,eRDC_L,eRDC_R

BO_ 2563568164 SIGMA_SRad_FRTriggerFrame: 7 BCM
  SG_ SIGMA_SRad_FR : 4|29@0+ (1,0) [0|0] "" ACU,HFM,HPCU,HVAC_CU,USM,eRDC_L,eRDC_R
  SG_ SIGMA_DTCSRad_FR : 39|24@0+ (1,0) [0|0] "" ACU,HFM,HPCU,HVAC_CU,USM,eRDC_L,eRDC_R

BO_ 2563568201 SIGMA_STBWTriggerFrame: 7 BCM
  SG_ SIGMA_STBW : 4|29@0+ (1,0) [0|0] "" ACU,HFM,HPCU,HVAC_CU,USM,eRDC_L,eRDC_R
  SG_ SIGMA_DTCSTBW : 39|24@0+ (1,0) [0|0] "" ACU,HFM,HPCU,HVAC_CU,USM,eRDC_L,eRDC_R

BO_ 2563568233 SIGMA_DMCTriggerFrame: 7 BCM
  SG_ SIGMA_DMC : 4|29@0+ (1,0) [0|0] "" ACU,HFM,HPCU,HVAC_CU,USM,eRDC_L,eRDC_R
  SG_ SIGMA_DTCDMC : 39|24@0+ (1,0) [0|0] "" ACU,HFM,HPCU,HVAC_CU,USM,eRDC_L,eRDC_R

BO_ 2563568267 SIGMA_RSCU3RTriggerFrame: 7 BCM
  SG_ SIGMA_RSCU3R : 4|29@0+ (1,0) [0|0] "" ACU,HFM,HPCU,HVAC_CU,USM,eRDC_L,eRDC_R
  SG_ SIGMA_DTCRSCU3R : 39|24@0+ (1,0) [0|0] "" ACU,HFM,HPCU,HVAC_CU,USM,eRDC_L,eRDC_R

BO_ 2563568288 SIGMA_BLM_RPKTriggerFrame: 7 BCM
  SG_ SIGMA_BLM_RPK : 4|29@0+ (1,0) [0|0] "" ACU,HFM,HPCU,HVAC_CU,USM,eRDC_L,eRDC_R
  SG_ SIGMA_DTCBLM_RPK : 39|24@0+ (1,0) [0|0] "" ACU,HFM,HPCU,HVAC_CU,USM,eRDC_L,eRDC_R

BO_ 2563568290 SIGMA_SCCMTriggerFrame: 7 BCM
  SG_ SIGMA_SCCM : 4|29@0+ (1,0) [0|0] "" ACU,HFM,HPCU,HVAC_CU,USM,eRDC_L,eRDC_R
  SG_ SIGMA_DTCSCCM : 39|24@0+ (1,0) [0|0] "" ACU,HFM,HPCU,HVAC_CU,USM,eRDC_L,eRDC_R

BO_ 2563568300 SIGMA_RSCU2RTriggerFrame: 7 BCM
  SG_ SIGMA_RSCU2R : 4|29@0+ (1,0) [0|0] "" ACU,HFM,HPCU,HVAC_CU,USM,eRDC_L,eRDC_R
  SG_ SIGMA_DTCRSCU2R : 39|24@0+ (1,0) [0|0] "" ACU,HFM,HPCU,HVAC_CU,USM,eRDC_L,eRDC_R

BO_ 2563639107 SIGMA_eRDC_L_ReadMeReq_Frame: 8 eRDC_L
  SG_ SIGMA_eRDC_L_ReadMeReqRDIAG : 7|64@0+ (1,0) [0|0] "" BCM

BO_ 2563639109 SIGMA_eRDC_R_ReadMeReq_Frame: 8 eRDC_R
  SG_ SIGMA_eRDC_R_ReadMeReqRDIAG : 7|64@0+ (1,0) [0|0] "" BCM

BO_ 2563639149 SIGMA_USM_ReadMeReq_Frame: 8 USM
  SG_ SIGMA_USM_ReadMeReqRDIAG : 7|64@0+ (1,0) [0|0] "" BCM

BO_ 2564441074 DTOOL_to_eRDC_L: 8 BCM
  SG_ DTOOL_to_eRDC_L : 7|64@0+ (1,0) [0|0] "" eRDC_L

BO_ 2564441586 DTOOL_to_eRDC_R: 8 BCM
  SG_ DTOOL_to_eRDC_R : 7|64@0+ (1,0) [0|0] "" eRDC_R

BO_ 2564452850 DTOOL_to_LCU_ADBextd: 8 BCM
  SG_ DTOOL_to_LCU_ADBextd : 7|64@0+ (1,0) [0|0] "" LCU_ADB

BO_ 2564453106 DTOOL_to_ADBdriverL: 8 BCM
  SG_ DTOOL_to_ADBdriverL : 7|64@0+ (1,0) [0|0] "" LCU_ADB

BO_ 2564453362 DTOOL_to_ADBdriverR: 8 BCM
  SG_ DTOOL_to_ADBdriverR : 7|64@0+ (1,0) [0|0] "" LCU_ADB

BO_ 2564462833 DTOOL_to_HVAC2: 8 BCM
  SG_ DTOOL_to_HVAC2 : 7|64@0+ (1,0) [0|0] "" HPCU

BO_ 2564485528 HVAC2_to_DTOOL: 8 HPCU
  SG_ HVAC2_to_DTOOL : 7|64@0+ (1,0) [0|0] "" BCM

BO_ 2564485699 eRDC_L_to_DTOOL: 8 eRDC_L
  SG_ ERDC_L_to_DTOOL : 7|64@0+ (1,0) [0|0] "" BCM

BO_ 2564485701 eRDC_R_to_DTOOL: 8 eRDC_R
  SG_ ERDC_R_to_DTOOL : 7|64@0+ (1,0) [0|0] "" BCM

BO_ 2564485745 LCU_ADB_to_DTOOLextd: 8 LCU_ADB
  SG_ LCU_ADB_to_DTOOLextd : 7|64@0+ (1,0) [0|0] "" BCM

BO_ 2564485746 ADBdriverL_To_DTOOL: 8 LCU_ADB
  SG_ ADBdriverL_To_DTOOL : 7|64@0+ (1,0) [0|0] "" BCM

BO_ 2564485747 ADBdriverR_To_DTOOL: 8 LCU_ADB
  SG_ ADBdriverR_To_DTOOL : 7|64@0+ (1,0) [0|0] "" BCM

BO_ 2609102862 BCM_WakeUpFrame_extd: 2 BCM
  SG_ BCM_WakeUp_Signal : 7|16@0+ (1,0) [0|0] "" USM

BO_ 2609102915 ERDC_L_WakeUpFrame_extd: 2 eRDC_L
  SG_ ERDC_L_WakeUp_Signal : 7|16@0+ (1,0) [0|0] "" BCM

BO_ 2609102917 ERDC_R_WakeUpFrame_extd: 2 eRDC_R
  SG_ ERDC_R_WakeUp_Signal : 7|16@0+ (1,0) [0|0] "" BCM

BO_ 2615028210 FTOOLS_CGWtoHVAC: 8 BCM
  SG_ FTOOLS_CGWtoHVAC : 7|64@0+ (1,0) [0|0] "" HVAC_CU

BO_ 2615034610 FTOOLS_CGWtoUSM: 8 BCM
  SG_ FTOOLS_CGWtoUSM : 7|64@0+ (1,0) [0|0] "" USM

BO_ 2615056625 FTOOLS_CGWtoHPCU: 8 BCM
  SG_ FTOOLS_CGWtoHPCU : 7|64@0+ (1,0) [0|0] "" HPCU

BO_ 2615066866 FTOOLS_CGWtoHFM: 8 BCM
  SG_ FTOOLS_CGWtoHFM : 7|64@0+ (1,0) [0|0] "" HFM

BO_ 2615079320 FTOOLS_HPCUtoCGW: 8 HPCU
  SG_ FTOOLS_HPCUtoCGW : 7|64@0+ (1,0) [0|0] "" BCM

BO_ 2615079465 FTOOLS_HVACtoCGW: 8 HVAC_CU
  SG_ FTOOLS_HVACtoCGW : 7|64@0+ (1,0) [0|0] "" BCM

BO_ 2615079490 FTOOLS_USMtoCGW: 8 USM
  SG_ FTOOLS_USMtoCGW : 7|64@0+ (1,0) [0|0] "" BCM

BO_ 2615079616 FTOOLS_HFMtoCGW: 8 HFM
  SG_ FTOOLS_HFMtoCGW : 7|64@0+ (1,0) [0|0] "" BCM

CM_ BO_ 1386 "[C1AHS-T3-2017]: Specific C1A  frame";
VAL_ 1305 eWP_Battery_Failure_State 0 "no failure" 1 "failure with water pump stopped";
VAL_ 1306 HFM_BLM_pairing 0 "Table Value29848";
VAL_ 1308 BLM_HFM_pairing 0 "Table Value29845";
VAL_ 1311 Flush_MovingRequest 0 "No request" 1 "Ejected position requested" 2 "Retracted position requested" 3 "Not used";
VAL_ 1326 SecondRowCtrRightPresenceState 0 "Not Monitored" 1 "Present" 2 "Absent" 3 "Unknown";
VAL_ 1326 SecondRowCtrRightSafetyBeltState 0 "SB not monitored" 1 "SB unfastened" 2 "SB fastened" 3 "Unavailable";
VAL_ 1326 SmallCrash_Impact 0 "No Crash" 1 "Front impact" 2 "Left side impact" 3 "Right side impact" 4 "Rear crash impact" 5 "Not used" 6 "Not used" 7 "Not used";
VAL_ 1328 HVbatCoolingSaveRequest 0 "No request" 1 "Cooling save request";
VAL_ 1332 AIRBAGMalfunction 0 "no AIRBAG system malfunction" 1 "AIRBAG system malfunction";
VAL_ 1332 ActiveHoodWarningLampCheck 0 "Lamp check not activated" 1 "Lamp check activated";
VAL_ 1332 ActiveHoodMalfunction 0 "Not used" 1 "No active hood system malfunction" 2 "Active hood system malfunction" 3 "unavailable";
VAL_ 1332 PassengerAlertState 0 "SB not monitored" 1 "SB unfastened" 2 "SB fastened or passenger absent" 3 "Unavailable";
VAL_ 1332 PassengerAIRBAG_Inhibition 0 "Passenger AIRBAG not inhibited" 1 "Passenger AIRBAG inhibited";
VAL_ 1332 CrashDetectionOutOfOrder_v2 0 "Detection functional" 1 "Malfunction for rear crash" 2 "Malfunction for side or front crash" 3 "Malfunction for crash detection";
VAL_ 1332 CrashDetected_v2 0 "Reserved for safety" 1 "No crash detected" 2 "Crash detected" 3 "Reserved for safety";
VAL_ 1332 AirbagWarningLampCheck 0 "Lamp check not activated" 1 "Lamp check activated";
VAL_ 1332 SecondRowCenterPresenceState 0 "Not monitored" 1 "Present" 2 "Absent" 3 "Unknown";
VAL_ 1332 RolloverDetectionMalfunction 0 "Normal rollover detection functional " 1 "Malfunction for rollover detection";
VAL_ 1332 PassengerSafetyBeltBuckleState 0 "SB Not monitored" 1 "SB unfastened" 2 "SB fastened" 3 "Unavailable";
VAL_ 1332 PassengerPresenceState 0 "Not monitored" 1 "Present" 2 "Absent" 3 "Unknown";
VAL_ 1332 SecondRowRightPresenceState 0 "Not monitored" 1 "Present" 2 "Absent" 3 "Unknown";
VAL_ 1332 SecondRowLeftSafetyBeltState 0 "SB not monitored" 1 "SB unfastened" 2 "SB fastened" 3 "Unavailable";
VAL_ 1332 SecondRowLeftPresenceState 0 "Not monitored" 1 "Present" 2 "Absent" 3 "Unknown";
VAL_ 1332 SecondRowCenterSafetyBeltState 0 "SB not monitored" 1 "SB unfastened" 2 "SB fastened" 3 "Unavailable";
VAL_ 1332 ThirdRowLeftPresenceState 0 "Not monitored" 1 "Present" 2 "Absent" 3 "Unknown";
VAL_ 1332 ThirdRowCenterSafetyBeltState 0 "SB not monitored" 1 "SB unfastened" 2 "SB fastened" 3 "Unavailable";
VAL_ 1332 ThirdRowCenterPresenceState 0 "Not monitored" 1 "Present" 2 "Absent" 3 "Unknown";
VAL_ 1332 SecondRowRightSafetyBeltState 0 "SB not monitored" 1 "SB unfastened" 2 "SB fastened" 3 "Unavailable";
VAL_ 1332 FirstRowCenterPresenceState 0 "Not monitored" 1 "Present" 2 "Absent" 3 "Unknown";
VAL_ 1332 ThirdRowRightSafetyBeltState 0 "SB not monitored" 1 "SB unfastened" 2 "SB fastened" 3 "Unavailable";
VAL_ 1332 ThirdRowRightPresenceState 0 "Not monitored" 1 "Present" 2 "Absent" 3 "Unknown";
VAL_ 1332 ThirdRowLeftSafetyBeltState 0 "SB not monitored" 1 "SB unfastened" 2 "SB fastened" 3 "Unavailable";
VAL_ 1332 PassengerAIRBAG_Status_Display 0 "No display" 1 "Passenger Airbag not inhibited" 2 "Passenger Airbag inhibited" 3 "Not Used";
VAL_ 1332 PassengerAIRBAG_Inhibition_v2 0 "No display" 1 "Passenger AIRBAG not inhibited" 2 "Passenger AIRBAG inhibited" 3 "Not used";
VAL_ 1332 FirstRowCenterSafetyBeltState 0 "SB Not monitored" 1 "SB unfastened" 2 "SB fastened" 3 "Unavailable";
VAL_ 1343 COMPR_ON_permission 0 "Compressor ON forbidden" 1 "Compressor ON permit";
VAL_ 1343 HEVC_PresoakRequest 0 "Immediat Presoak Request" 1 "Programmed Presoak Request" 2 "Presoak Stop" 3 "Unavailable";
VAL_ 1343 IndoorAirCirculationRequest 0 "No request" 1 "Request";
VAL_ 1360 HVlightChargeRequest 0 "No request" 1 "Request";
VAL_ 1361 ELKA_OTOC_ActivationState 0 "Activated" 1 "Deactivated";
VAL_ 1361 ELKS_ActivationState 0 "Activated" 1 "Deactivated";
VAL_ 1362 DongleBCM2_VSC 0 "Table Value420128";
VAL_ 1362 DongleBCM1_VSC 0 "Table Value420127";
VAL_ 1362 DongleBCM3_VSC 0 "Table Value420129";
VAL_ 1364 ClimElecConsumptionLimitDisplay 0 "No display" 1 "Electrical Consumption Limitation ON" 2 "Electrical Consumption Limitation OFF" 3 "Unavailable";
VAL_ 1364 ClimVariableAirFlowDisplay 0 "No display" 1 "Level 1" 2 "Level 2" 3 "Level 3" 4 "Level 4" 5 "Level 5" 6 "OFF" 7 "Not used";
VAL_ 1364 ClimRearOFFModeDisplay 0 "No display" 1 "OFF Mode Activated Display";
VAL_ 1364 ClimRearLockStatus 0 "No display" 1 "Rear climate lock display" 2 "Rear climate unlock display" 3 "Not used";
VAL_ 1364 ClimLinkPrio3rdLSeatAutoDisp 0 "No display" 1 "Level 1" 2 "Level 2" 3 "Level 3" 4 "Level 4" 5 "Level 5" 6 "OFF" 7 "Not Used";
VAL_ 1364 ClimIRSensorOn_Display 0 "No display" 1 "IR sensing function link to Auto ON" 2 "IR sensing function link to Auto OFF" 3 "Not Used";
VAL_ 1364 ClimLinkPriorityRRSeatAutoDisp 0 "No display" 1 "Level 1" 2 "Level 2" 3 "Level 3" 4 "Level 4" 5 "Level 5" 6 "OFF" 7 "Not used";
VAL_ 1364 ProactiveRecyclingStatus 0 "Proactive prohibited" 1 "Proactive authorized";
VAL_ 1364 ClimAllSeatAutoDisplay 0 "No display" 1 "Auto activated" 2 "Auto not activated" 3 "Not Used";
VAL_ 1364 ClimLinkPrio3rdRSeatAutoDisp 0 "No display" 1 "Level 1" 2 "Level 2" 3 "Level 3" 4 "Level 4" 5 "Level 5" 6 "OFF" 7 "Not Used";
VAL_ 1364 ClimRearOFFModeDisplayStatus 0 "Function not available" 1 "Function available";
VAL_ 1364 ClimRearLockDisplayStatus 0 "Function not available" 1 "Function available";
VAL_ 1364 HVBatteryCoolingType 0 "no battery cooling" 1 "battery cooling" 2 "battery cooling in severe condition" 3 "not used";
VAL_ 1364 RecyPollutionStatus 0 "No Pollution" 1 "Pollution limited" 2 "Pollution protected" 3 "Unavailable value";
VAL_ 1364 SecondRightSeatModeDisp 0 "No display" 1 "Seat Heater" 2 "Seat Ventilation" 3 "Not used";
VAL_ 1364 SecondLeftSeatModeDisp 0 "No display" 1 "Seat Heater" 2 "Seat Ventilation" 3 "Not used";
VAL_ 1364 FrontRightSeatModeDisp 0 "No display" 1 "Seat Heater" 2 "Seat Ventilation" 3 "Not used";
VAL_ 1364 FrontLeftSeatModeDisp 0 "No display" 1 "Seat Heater" 2 "Seat Ventilation" 3 "Not used";
VAL_ 1364 ClimLinkOccupantForSeatDisplay 0 "No display" 1 "SeatOccupantLink ON" 2 "SeatOccupantLink OFF" 3 "Not Used";
VAL_ 1364 ClimLinkOccupantForDRZoneDisp 0 "No display" 1 "DRZNOccupantLink ON" 2 "DRZNOccupantLink OFF" 3 "Not Used";
VAL_ 1364 ClimShortcutRequest 0 "NoRequest" 1 "FrControlPanel" 2 "RrControlPanel" 3 "FrontLeftSeat" 4 "FrontRightSeat" 5 "FrontLeftSeat and FrontRightSeat" 6 "RearLeftSeat" 7 "RearRightSeat" 8 "RearLeftSeat and RearRightSeat" 9 "Not used" 10 "Not used" 11 "Not used" 12 "Not used" 13 "Not used" 14 "Not used" 15 "Not used";
VAL_ 1364 ClimPartialAutoState 0 "Manual" 1 "FAN AUTO";
VAL_ 1369 ELKA_AlertLeftRequest 0 "No Alert" 1 "Oncoming Alert level 1" 2 "Oncoming Alert level 2" 3 "Overtaking Alert level 1" 4 "Overtaking Alert level 2" 5 "Roadedge Alert level 1" 6 "Roadedge Alert level 2" 7 "Alert reminder";
VAL_ 1369 ELKA_AlertRightRequest 0 "No Alert" 1 "Oncoming Alert level 1" 2 "Oncoming Alert level 2" 3 "Overtaking Alert level 1" 4 "Overtaking Alert level 2" 5 "Roadedge Alert level 1" 6 "Roadedge Alert level 2" 7 "Alert reminder";
VAL_ 1369 ELKA_ActivationState 0 "Activated" 1 "Deactivated";
VAL_ 1373 PreSoakBatteryHeatingReq_IVC_v2 0 "No Request" 1 "Battery heating OFF request" 2 "Battery heating ON request" 3 "Not Used";
VAL_ 1373 PreSoakAirPurifierRequest_IVC_v2 0 "No Request" 1 "Air purifier OFF request" 2 "Air purifier ON request" 3 "Not Used";
VAL_ 1373 PreSoak_eACmodeRequest_IVC_v2 0 "No Request" 1 "Normal request" 2 "Quick request" 3 "Not Used";
VAL_ 1373 PreSoakFRseatRequest_IVC_v2 0 "No Request" 1 "Heater OFF request" 2 "Heater ON request" 3 "Ventilated OFF request" 4 "Ventilated ON request" 5 "Not Used" 6 "Not Used" 7 "Not Used";
VAL_ 1373 PreSoakFrontDefrostReq_IVC_v2 0 "No Request" 1 "Front defrost OFF request" 2 "Front defrost ON request" 3 "Not Used";
VAL_ 1373 PreSoakFLseatRequest_IVC_v2 0 "No Request" 1 "Heater OFF request" 2 "Heater ON request" 3 "Ventilated OFF request" 4 "Ventilated ON request" 5 "Not Used" 6 "Not Used" 7 "Not Used";
VAL_ 1373 PreSoakSecondRLseatReq_IVC_v2 0 "No Request" 1 "Heater OFF request" 2 "Heater ON request" 3 "Ventilated OFF request" 4 "Ventilated ON request" 5 "Not Used" 6 "Not Used" 7 "Not Used";
VAL_ 1373 PreSoakHeatedStrgWheelReq_IVC_v2 0 "No Request" 1 "Heated steering wheel OFF request" 2 "Heated steering wheel ON request" 3 "Not Used";
VAL_ 1373 PreSoakSecondRCseatReq_IVC_v2 0 "No Request" 1 "Heater OFF request" 2 "Heater ON request" 3 "Ventilated OFF request" 4 "Ventilated ON request" 5 "Not Used" 6 "Not Used" 7 "Not Used";
VAL_ 1373 PreSoakThirdRLseatRequest_IVC_v2 0 "No Request" 1 "Heater OFF request" 2 "Heater ON request" 3 "Ventilated OFF request" 4 "Ventilated ON request" 5 "Not Used" 6 "Not Used" 7 "Not Used";
VAL_ 1373 PreSoakHVACfunctionsReq_IVC_v2 0 "No Request" 1 "Cabin air conditioning/heating OFF request" 2 "Cabin air conditioning/heating ON request" 3 "Not Used";
VAL_ 1373 PreSoakSecondRRseatReq_IVC_v2 0 "No Request" 1 "Heater OFF request" 2 "Heater ON request" 3 "Ventilated OFF request" 4 "Ventilated ON request" 5 "Not Used" 6 "Not Used" 7 "Not Used";
VAL_ 1373 PreSoakRearDefrostRequest_IVC_v2 0 "No Request" 1 "Rear defrost OFF request" 2 "Rear defrost ON request" 3 "Not Used";
VAL_ 1373 PreSoakThirdRRseatRequest_IVC_v2 0 "No Request" 1 "Heater OFF request" 2 "Heater ON request" 3 "Ventilated OFF request" 4 "Ventilated ON request" 5 "Not Used" 6 "Not Used" 7 "Not Used";
VAL_ 1379 DongleEPS2 0 "Table Value22084";
VAL_ 1379 DongleEPS1 0 "Table Value22080";
VAL_ 1379 DongleEPS3 0 "Table Value22085";
VAL_ 1381 BSWrad_AlertStatus 0 "No alert" 1 "Right alert" 2 "Left alert" 3 "Right and left alert";
VAL_ 1384 ClimLeftFlowDistrRequest 0 "No request" 1 "Feet" 2 "Vent" 3 "Vent + Feet" 4 "Defrost" 5 "Defrost + Feet" 6 "Defrost + Vent" 7 "Defrost + Vent + Feet";
VAL_ 1384 ClimRearLockRequest 0 "No request" 1 "Rear climate lock request" 2 "Rear climate unlock request" 3 "Reset request";
VAL_ 1384 ClimRearLeftFlowDistRequest 0 "No request" 1 "Feet" 2 "Vent" 3 "Vent + Feet" 4 "Defrost" 5 "Defrost + Feet" 6 "Defrost + Vent" 7 "Defrost + Vent + Feet";
VAL_ 1384 ClimRearRightFlowDistRequest 0 "No request" 1 "Feet" 2 "Vent" 3 "Vent + Feet" 4 "Defrost" 5 "Defrost + Feet" 6 "Defrost + Vent" 7 "Defrost + Vent + Feet";
VAL_ 1384 FrontLeftSeatAutoRequest 0 "No request" 1 "Auto mode activation" 2 "Auto mode deactivation" 3 "Reset request";
VAL_ 1384 ClimRecyclingModeRequest 0 "No request" 1 "Fresh" 2 "Auto" 3 "Recycling" 4 "Auto + Fresh" 5 "Auto + Recycling" 6 "Not Used" 7 "Not Used";
VAL_ 1384 ClimLinkPrioRearSeatsAutoReq 0 "No request" 1 "Level 1" 2 "Level 2" 3 "Level 3" 4 "Level 4" 5 "Level 5" 6 "OFF request" 7 "Reset request";
VAL_ 1384 FrontRightSeatAutoRequest 0 "No request" 1 "Auto mode activation" 2 "Auto mode deactivation" 3 "Reset request";
VAL_ 1384 ClimVariableAirFlowRequest 0 "No request" 1 "Level 1" 2 "Level 2" 3 "Level 3" 4 "Level 4" 5 "Level 5" 6 "OFF request" 7 "Reset request";
VAL_ 1384 ClimRightFlowDistrRequest 0 "No request" 1 "Feet" 2 "Vent" 3 "Vent + Feet" 4 "Defrost" 5 "Defrost + Feet" 6 "Defrost + Vent" 7 "Defrost + Vent + Feet";
VAL_ 1384 SecondRowRightSeatAutoRequest 0 "No request" 1 "Auto mode activation" 2 "Auto mode deactivation" 3 "Reset request";
VAL_ 1384 SecondRowLeftSeatAutoRequest 0 "No request" 1 "Auto mode activation" 2 "Auto mode deactivation" 3 "Reset request";
VAL_ 1386 HeatLoopWaterValveRequest 0 "Engine loop request" 1 "Short loop request";
VAL_ 1386 PresoakProg_HVACmode 0 "No Presoak Programmed" 1 "Presoak programmed in progress" 2 "Not used" 3 "Unavailable";
VAL_ 1386 HVPTCbatt_FaultType 0 "No failure and HV PTC ON" 1 "No failure and HV PTC OFF" 2 "Downgraded mode for HV PTC" 3 "Failure mode for HV PTC" 4 "To Change HV PTC" 5 "Not Used" 6 "Not Used" 7 "Unavailable";
VAL_ 1386 AirShutterIntermediateRequest 0 "No Air Shutters Intermadiate Opening Request" 1 "Air Shutters Intermadiate Opening Request";
VAL_ 1391 AC_eBattPTCInterlockHVConnector 0 "Not used" 1 "Interlock Opened" 2 "Interlock Closed" 3 "Unavailable";
VAL_ 1392 FOTA_ReadyToSleep_IVI 0 "Refuse to sleep due to FOTA" 1 "Ready to sleep";
VAL_ 1402 ADAS_HornRequest 0 "No Request" 1 "Request";
VAL_ 1402 LKA_StatusDisplay_v2 0 "No display" 1 "Not operational" 2 "Operational" 3 "Temporary failure" 4 "Permanent failure" 5 "OFF Value" 6 "Not Used" 7 "Not Used";
VAL_ 1402 LDW_StatusDisplay_v2 0 "No display" 1 "Not operational" 2 "Operational" 3 "Temporary failure" 4 "Permanent failure" 5 "OFF Value" 6 "Not Used" 7 "Not Used";
VAL_ 1402 LCA_StatusDisplay_v2 0 "No display" 1 "Not operational" 2 "Operational" 3 "Temporary failure" 4 "Permanent failure" 5 "MRM active" 6 "Not Used" 7 "Not Used";
VAL_ 1402 ELKA_StatusDisplay_v2 0 "No display" 1 "ELKA OFF" 2 "Operational" 3 "Not operational" 4 "Temporary failure" 5 "Permanent failure" 6 "Not Used" 7 "Not Used";
VAL_ 1405 RPK_ModeRequest 0 "Normal Mode Request" 1 "RPK Mode Request" 2 "RPK Register Mode Request" 3 "Not Used";
VAL_ 1409 Blank_Coded 0 "coded" 1 "blank";
VAL_ 1409 LockingFinished 0 "locking movement not finished" 1 "locking movement finished";
VAL_ 1409 Undefined_position 0 "position OK (compliant with the theoritical position processed from calculations)" 1 "undefined position (not compliant with the theoritical position processed from calculations)";
VAL_ 1409 UnlockingFinished 0 "unlocking movement not finished" 1 "unlocking movement finished";
VAL_ 1409 LockForbidden 0 "no locking inhibition" 1 "locking inhibition";
VAL_ 1409 AntiscanOn 0 "antiscan off" 1 "antiscan on";
VAL_ 1409 WrongCode 0 "right code" 1 "wrong code";
VAL_ 1409 SteeringLockCOP 0 "Table Value16351";
VAL_ 1409 SteeringLockMajorElectronicFailure 0 "no major internal electronic failure" 1 "Major internal electronic failure";
VAL_ 1409 Steering_actuator_failure 0 "no actuator failure" 1 "actuator failure";
VAL_ 1409 ESCL3Position 0 "reserved" 1 "sensor or wire command failure" 2 "unlocked and secured position" 3 "undefined position" 4 "pseudo-armed" 5 "sensor or wire command short-circuit" 6 "reserved" 7 "reserved";
VAL_ 1409 SteeringLock_Minor_Electronic_Failure 0 "no minor internal electronic failure" 1 "minor internal electronic failure";
VAL_ 1409 ResetInfo_Verrou 0 "exit from reset" 1 "no exit from reset";
VAL_ 1409 PowerSupplyFeedback 0 "Hall effect sensor supplied" 1 "Hall effect sensor not supplied";
VAL_ 1409 SafetyLineInhibition 0 "locking allowed" 1 "locking forbidden";
VAL_ 1409 SpeedInhibition 0 "vehicle speed equal to 0 km/h" 1 "vehicle speed > 0 km/h or frame absent or vehicle speed = FFFFh";
VAL_ 1409 SensorTestAuthorized 0 "sensor test forbidden" 1 "sensor test authorized";
VAL_ 1409 Inconsistency_Frame 0 "Frame received is correct" 1 "Frame received is uncorrect";
VAL_ 1412 AC_EvaporatorTempSensorState 0 "Normal" 1 "Open to Circuit" 2 "Short to Ground" 3 "Short to 12V" 4 "Out of Range Lo" 5 "Out of Range Hi" 6 "Not Used" 7 "Not Used";
VAL_ 1412 AC_CabinTemperatureSensorState 0 "Normal" 1 "Open to Circuit" 2 "Short to Ground" 3 "Short to 12V" 4 "Out of Range Lo" 5 "Out of Range Hi" 6 "Not Used" 7 "Not Used";
VAL_ 1412 HVAC_ClimShortcutPush 0 "Switch not pushed" 1 "Switch pushed";
VAL_ 1412 ClimHVpowerLimitationDisplay 0 "No display" 1 "Thermal Comfort available" 2 "SOC decreasing warning" 3 "No Thermal Comfort available";
VAL_ 1412 HVBatCoolingSaveCancel_HVAC 0 "Not cancelled" 1 "Cancelled";
VAL_ 1412 HVBatCoolingSaveState_HVAC 0 "No message" 1 "Message01" 2 "Message02" 3 "Message03";
VAL_ 1412 SunSensor_state 0 "Normal" 1 "Open to Circuit" 2 "Short to Ground" 3 "Short to 12V" 4 "Out of Range Lo" 5 "Out of Range Hi" 6 "Not Used" 7 "Not Used";
VAL_ 1418 HeatLoopPumpStatus 0 "OFF" 1 "ON";
VAL_ 1430 AEB_Classification 0 "Not Detected" 1 "Car" 2 "Motorcyclist" 3 "Bicyclist" 4 "Pedestrian" 5 "Unknown" 6 "Not Used" 7 "Not Used";
VAL_ 1430 AEB_Activation_Flag 0 "No Warning" 1 "Warning" 2 "Pre-fill Brake" 3 "Pre-Brake" 4 "Full-Brake" 5 "DBA" 6 "Not Used" 7 "Not Used";
VAL_ 1436 HFP_MapContentDisplay 0 "Empty Display" 1 "scanning Display" 2 "parkOutConfirmation Display" 3 "guidance Display" 4 "Not used" 5 "Not used" 6 "Not used" 7 "unavailable";
VAL_ 1449 ClimLinkPriorityHeatStrgAutoReq 0 "No request" 1 "Level 1" 2 "Level 2" 3 "Level 3" 4 "Level 4" 5 "Level 5" 6 "OFF request" 7 "Reset request";
VAL_ 1449 ClimFPrearLeftBlowingRequest 0 "No Request" 1 "Level 1" 2 "Level 2" 3 "Level 3" 4 "Level 4" 5 "Level 5" 6 "Level 6" 7 "Level 7" 8 "Level 8" 9 "Level 9" 10 "Level 10" 11 "Level 11" 12 "Level 12" 13 "Level 13" 14 "Level 14" 15 "Blower OFF";
VAL_ 1449 ClimFPrearRightBlowingRequest 0 "No Request" 1 "Level 1" 2 "Level 2" 3 "Level 3" 4 "Level 4" 5 "Level 5" 6 "Level 6" 7 "Level 7" 8 "Level 8" 9 "Level 9" 10 "Level 10" 11 "Level 11" 12 "Level 12" 13 "Level 13" 14 "Level 14" 15 "Blower OFF";
VAL_ 1449 ClimLinkPriorityRRSeatAutoReq 0 "No request" 1 "Level 1" 2 "Level 2" 3 "Level 3" 4 "Level 4" 5 "Level 5" 6 "OFF request" 7 "Reset request";
VAL_ 1449 ClimAllSeatAutoNormalRequest 0 "No Request" 1 "OFF" 2 "ON" 3 "Not used";
VAL_ 1449 ClimLinkPrio3rdRSeatAutoReq 0 "No request" 1 "Level 1" 2 "Level 2" 3 "Level 3" 4 "Level 4" 5 "Level 5" 6 "OFF request" 7 "Reset request";
VAL_ 1449 ClimLinkPrio3rdLSeatAutoReq 0 "No request" 1 "Level 1" 2 "Level 2" 3 "Level 3" 4 "Level 4" 5 "Level 5" 6 "OFF request" 7 "Reset request";
VAL_ 1454 AFS_FailureDisplay 0 "No Failure" 1 "Failure on AFS";
VAL_ 1454 LIDARCleaningFailure 0 "No Failure" 1 "Failure";
VAL_ 1454 LevellingLimitAlert 0 "No alert" 1 "Alert";
VAL_ 1454 ManualLevellingPosition 0 "Position 0" 1 "Position 1" 2 "Position 2" 3 "Position 3" 4 "Position 4" 5 "Not used" 6 "Not used" 7 "Unavailable";
VAL_ 1457 LightingSystemFailureDisplay 0 "No failure" 1 "Failure detected";
VAL_ 1458 SportModeThmgtRequest 0 "No sport mode activation request" 1 "sport mode activation boost 1" 2 "sport mode activation boost 2" 3 "Not used";
VAL_ 1462 ClimRearLeftTempDisplay 0 "No display" 8 "Display Lo" 10 "Display Hi";
VAL_ 1462 ClimFrontDefrostDisplayStatus 0 "Function not available" 1 "Function available";
VAL_ 1462 ClimHeatedSteerWheelDispStatus 0 "Function not available" 1 "Function available";
VAL_ 1462 ClimRearLeftTempDisplayStatus 0 "Function not available" 1 "Function available";
VAL_ 1462 ClimHeatedSteerWheelAutoDisplay 0 "No display" 1 "Heated steering wheel Auto ON" 2 "Heated steering wheel Auto OFF" 3 "Not Used";
VAL_ 1462 ClimFrontDefrostDisplay 0 "No display" 1 "Front defrost ON" 2 "Front defrost OFF" 3 "Not Used";
VAL_ 1462 ClimRearRightTempDisplay 0 "No display" 8 "Display Lo" 10 "Display Hi";
VAL_ 1462 ClimRearRightSyncDisplayStatus 0 "Function not available" 1 "Function available";
VAL_ 1462 ClimRearRightSyncDisplay 0 "No display" 1 "Sync mode ON" 2 "Sync mode OFF" 3 "Not used";
VAL_ 1462 ClimRearLeftSyncDisplayStatus 0 "Function not available" 1 "Function available";
VAL_ 1462 ClimRearLeftSyncDisplay 0 "No display" 1 "Sync mode ON" 2 "Sync mode OFF" 3 "Not used";
VAL_ 1462 ClimRearRightTempDisplayStatus 0 "Function not available" 1 "Function available";
VAL_ 1462 ClimRearRightFlowDistDispStatus 0 "Function not available" 1 "Function available";
VAL_ 1462 ClimRearRightFlowDistrDisplay 0 "No display" 1 "Feet" 2 "Vent" 3 "Feet + Vent" 4 "Defrost" 5 "Defrost + Feet" 6 "Defrost + Vent" 7 "Defrost + Vent + Feet";
VAL_ 1462 ClimRearLeftFlowDistrDispStatus 0 "Function not available" 1 "Function available";
VAL_ 1462 ClimRearLeftFlowDistrDisplay 0 "No display" 1 "Feet" 2 "Vent" 3 "Feet + Vent" 4 "Defrost" 5 "Defrost + Feet" 6 "Defrost + Vent" 7 "Defrost + Vent + Feet";
VAL_ 1462 ClimRearLeftBlowingAutoDisplay 0 "No display" 1 "Blowing auto ON" 2 "Blowing auto OFF" 3 "Not used";
VAL_ 1462 ClimRearRightBlowingAutoDisplay 0 "No display" 1 "Blowing auto ON" 2 "Blowing auto OFF" 3 "Not used";
VAL_ 1462 ClimRearRightBlowLevelDisplay 0 "No display" 1 "Level 1" 2 "Level 2" 3 "Level 3" 4 "Level 4" 5 "Level 5" 6 "Level 6" 7 "Level 7" 8 "Level 8" 9 "Level 9" 10 "Level 10" 11 "Level 11" 12 "Level 12" 13 "Level 13" 14 "Level 14" 15 "Blower OFF";
VAL_ 1462 ClimRearACDisplay 0 "No display" 1 "AC ON" 2 "AC OFF" 3 "Not used";
VAL_ 1462 ClimRearRightBlowLevlDispStatus 0 "Function not available" 1 "Function available";
VAL_ 1462 ClimRearLeftBlowLevelDispStatus 0 "Function not available" 1 "Function available";
VAL_ 1462 ClimRearLeftBlowLevelDisplay 0 "No display" 1 "Level 1" 2 "Level 2" 3 "Level 3" 4 "Level 4" 5 "Level 5" 6 "Level 6" 7 "Level 7" 8 "Level 8" 9 "Level 9" 10 "Level 10" 11 "Level 11" 12 "Level 12" 13 "Level 13" 14 "Level 14" 15 "Blower OFF";
VAL_ 1462 ClimLinkPrioritHeatStrgAutoDisp 0 "No display" 1 "Level 1" 2 "Level 2" 3 "Level 3" 4 "Level 4" 5 "Level 5" 6 "OFF" 7 "Not used";
VAL_ 1462 ClimRearRightAutoDisplay 0 "No display" 1 "Auto ON" 2 "Auto OFF" 3 "Not used";
VAL_ 1462 ClimRearLeftAutoDisplay 0 "No display" 1 "Auto ON" 2 "Auto OFF" 3 "Not used";
VAL_ 1462 ClimRearACDisplayStatus 0 "Function not available" 1 "Function available";
VAL_ 1465 PreSoakHVACfunctionsRequest 0 "Not used" 1 "Cabin air conditioning/heating OFF request" 2 "Cabin air conditioning/heating ON request" 3 "Not used";
VAL_ 1465 PreSoakFRseatRequest 0 "Not used" 1 "Heater OFF request" 2 "Heater ON request" 3 "Ventilated OFF request" 4 "Ventilated ON request" 5 "Not used" 6 "Not used" 7 "Not used";
VAL_ 1465 PreSoakFLseatRequest 0 "Not used" 1 "Heater OFF request" 2 "Heater ON request" 3 "Ventilated OFF request" 4 "Ventilated ON request" 5 "Not used" 6 "Not used" 7 "Not used";
VAL_ 1465 PreSoakSecondRLseatRequest 0 "Not used" 1 "Heater OFF request" 2 "Heater ON request" 3 "Ventilated OFF request" 4 "Ventilated ON request" 5 "Not used" 6 "Not used" 7 "Not used";
VAL_ 1465 PreSoakSecondRRseatRequest 0 "Not used" 1 "Heater OFF request" 2 "Heater ON request" 3 "Ventilated OFF request" 4 "Ventilated ON request" 5 "Not used" 6 "Not used" 7 "Not used";
VAL_ 1465 PreSoak_eACmodeRequest 0 "Not used" 1 "Normal request" 2 "Quick request" 3 "Not used";
VAL_ 1465 PreSoakThirdRLseatRequest 0 "Not used" 1 "Heater OFF request" 2 "Heater ON request" 3 "Ventilated OFF request" 4 "Ventilated ON request" 5 "Not used" 6 "Not used" 7 "Not used";
VAL_ 1465 PreSoakBatteryHeatingRequest 0 "Not used" 1 "Battery heating OFF request" 2 "Battery heating ON request" 3 "Not used";
VAL_ 1465 PreSoakSecondRCseatRequest 0 "Not used" 1 "Heater OFF request" 2 "Heater ON request" 3 "Ventilated OFF request" 4 "Ventilated ON request" 5 "Not used" 6 "Not used" 7 "Not used";
VAL_ 1465 PreSoakAirPurifierRequest 0 "Not used" 1 "Air purifier OFF request" 2 "Air purifier ON request" 3 "Not used";
VAL_ 1465 PreSoakFrontDefrostRequest 0 "Not used" 1 "Front defrost OFF request" 2 "Front defrost ON request" 3 "Not used";
VAL_ 1465 PreSoakThirdRRseatRequest 0 "Not used" 1 "Heater OFF request" 2 "Heater ON request" 3 "Ventilated OFF request" 4 "Ventilated ON request" 5 "Not used" 6 "Not used" 7 "Not used";
VAL_ 1465 SecondRowCentralSeatRequest 0 "No request" 1 "OFF request" 2 "Heater Low request" 3 "Heater Middle request" 4 "Heater High request" 5 "Ventilated Low request" 6 "Ventilated Middle request" 7 "Ventilated High request" 8 "Reset request" 9 "Not Used" 10 "Not Used" 11 "Not Used" 12 "Not Used" 13 "Not Used" 14 "Not Used" 15 "Not Used";
VAL_ 1465 PreSoakRearDefrostRequest 0 "Not used" 1 "Rear defrost OFF request" 2 "Rear defrost ON request" 3 "Not used";
VAL_ 1465 PreSoakHeatedStrgWheelRequest 0 "Not used" 1 "Heated steering wheel OFF request" 2 "Heated steering wheel ON request" 3 "Not used";
VAL_ 1465 FrontRightSeatRequest 0 "No request" 1 "OFF request" 2 "Heater Low request" 3 "Heater Middle request" 4 "Heater High request" 5 "Ventilated Low request" 6 "Ventilated Middle request" 7 "Ventilated High request" 8 "Reset request" 9 "Not Used" 10 "Not Used" 11 "Not Used" 12 "Not Used" 13 "Not Used" 14 "Not Used" 15 "Not Used";
VAL_ 1465 FrontLeftSeatRequest 0 "No request" 1 "OFF request" 2 "Heater Low request" 3 "Heater Middle request" 4 "Heater High request" 5 "Ventilated Low request" 6 "Ventilated Middle request" 7 "Ventilated High request" 8 "Reset request" 9 "Not Used" 10 "Not Used" 11 "Not Used" 12 "Not Used" 13 "Not Used" 14 "Not Used" 15 "Not Used";
VAL_ 1469 IoniserAutoLaunchReq2 0 "No request" 1 "Activation request" 2 "Deactivation request" 3 "Reset request";
VAL_ 1474 ClimRightTempDisplay 0 "No display" 8 "Display Lo" 10 "Display Hi";
VAL_ 1474 ClimTempDisplay 0 "No display" 8 "Display Lo" 10 "Display Hi";
VAL_ 1474 ClimFlowDistrDisplay 0 "No display" 1 "Feet" 2 "Aerator" 3 "Feet + Aerator" 4 "Mild flow" 5 "Feet + Mild flow" 6 "Mild flow + Aerator" 7 "Feet + Aerator Mild flow" 8 "Defrost" 9 "Feet + Defrost" 10 "Aerator + Defrost" 11 "Feet + Aerator + Defrost" 12 "Mild flow + Defrost" 13 "Feet + Mild flow + Defrost" 14 "Aerator + Mild flow + Defrost" 15 "Feet + Aerator + Mild flow + Defrost";
VAL_ 1474 ClimOFFModeDisplay 0 "No Display" 1 "OFF Mode Activated Display";
VAL_ 1474 ClimModeTypeDisplay 0 "No display" 1 "Auto Mode" 2 "Eco Mode" 3 "Clearness Mode" 4 "Manual Mode" 5 "OFF" 6 "Not Used" 7 "Not Used";
VAL_ 1474 ClimBlowerLevelDisplay 0 "No display" 1 "Level 1" 2 "Level 2" 3 "Level 3" 4 "Level 4" 5 "Level 5" 6 "Level 6" 7 "Level 7" 8 "Level 8" 9 "Level 9" 10 "Level 10" 11 "Level 11" 12 "Level 12" 13 "Level 13" 14 "Level 14" 15 "Blower Off";
VAL_ 1474 ClimClearnessDisplay 0 "No display" 1 "Clearness ON" 2 "Clearness OFF" 3 "Not Used";
VAL_ 1474 ClimAutoModeDisplay 0 "No display" 1 "Soft display" 2 "Fast display" 3 "Auto display";
VAL_ 1474 ClimAutoDisplay 0 "No display" 1 "Auto activated" 2 "Auto not activated" 3 "Not used";
VAL_ 1474 ClimACDisplay 0 "No display" 1 "AC ON" 2 "AC OFF" 3 "Not used";
VAL_ 1474 ClimRearDefrostDisplay 0 "No display" 1 "Rear defrost ON" 2 "Rear defrost OFF" 3 "Not Used";
VAL_ 1474 FrontDefrostDisplayRequest 0 "NO Front Defrog Display Request" 1 "Front Degrog Display Request";
VAL_ 1476 VPAStopMovement 0 "No stop" 1 "Stop movement";
VAL_ 1476 ProgrammedPresoakRequest_HFM 0 "No request" 1 "Programmed Presoak Request";
VAL_ 1476 RemoteChargingStart 0 "No Request" 1 "Start charge Request";
VAL_ 1482 HandDrivingActivationRequest2 0 "No request" 1 "Right Hand Driving requested" 2 "Left Hand Driving requested" 3 "Reset request";
VAL_ 1482 AFS_ActivationRequest2 0 "No request" 1 "Activation" 2 "Deactivation" 3 "Reset request";
VAL_ 1491 IKeyAccessActivationRequest 0 "No Request" 1 "iKey Access Activation request" 2 "iKey Access Desactivation request" 3 "Reset Request";
VAL_ 1491 AirCondEcoActivationRequest 0 "No request" 1 "Eco activation request" 2 "Eco deactivation request" 3 "Reset request";
VAL_ 1491 ISS_EcoActivationRequest 0 "No request" 1 "Eco activation request" 2 "Eco deactivation request" 3 "Reset request";
VAL_ 1499 RemoteFunctionService_HFM 0 "Table Value30439";
VAL_ 1505 AQMIoniserModeSelectionReq 0 "No request" 1 "Off" 2 "Clean" 3 "Relax";
VAL_ 1505 ClimFPBlowerRequest 0 "No Request" 1 "Level 1" 2 "Level 2" 3 "Level 3" 4 "Level 4" 5 "Level 5" 6 "Level 6" 7 "Level 7" 8 "Level 8" 9 "Level 9" 10 "Level 10" 11 "Level 11" 12 "Level 12" 13 "Level 13" 14 "Level 14" 15 "Blower OFF";
VAL_ 1505 BlowerReductionRequest 0 "Blower Speed Reduction not Requested" 1 "Blower Speed Reduction Requested";
VAL_ 1505 AirFreshenerRequest 0 "No request" 1 "Air Freshener ON requested" 2 "Air Freshener OFF requested" 3 "Not Used";
VAL_ 1506 RESPresoak_ImmediateReqForbid_SP 0 "Immediate authorized" 1 "Immediate forbidden";
VAL_ 1508 RESPreSoak_ProgStatus 0 "No programmed" 1 "1 time only (RES or Presoak)" 2 "Every two hours (5 times max)" 3 "Not used";
VAL_ 1509 RemoteFunctionService_TCU 0 "Table Value30440";
VAL_ 1511 WheelStateRL 0 "Pressure ok and no failure" 1 "Failure" 2 "Underinflation" 3 "Underinflation and failure" 4 "Puncture" 5 "Puncture and failure" 6 "Puncture and underinflation" 7 "Puncture and underinflation and failure";
VAL_ 1511 WheelStateRR 0 "Pressure ok and no failure" 1 "Failure" 2 "Underinflation" 3 "Underinflation and failure" 4 "Puncture" 5 "Puncture and failure" 6 "Puncture and underinflation" 7 "Puncture and underinflation and failure";
VAL_ 1511 WheelStateFL 0 "Pressure ok and no failure" 1 "Failure" 2 "Underinflation" 3 "Underinflation and failure" 4 "Puncture" 5 "Puncture and failure" 6 "Puncture and underinflation" 7 "Puncture and underinflation and failure";
VAL_ 1511 WheelStateFR 0 "Pressure ok and no failure" 1 "Failure" 2 "Underinflation" 3 "Underinflation and failure" 4 "Puncture" 5 "Puncture and failure" 6 "Puncture and underinflation" 7 "Puncture and underinflation and failure";
VAL_ 1516 AFS_ActivationRequest 0 "No request" 1 "Activation" 2 "Deactivation" 3 "Reset request";
VAL_ 1519 UserSettingCopySource 0 "Not copy" 1 "Guest" 2 "User1" 3 "User2" 4 "User3" 5 "User4" 6 "User5" 7 "Not used";
VAL_ 1519 UserSettingCopyTarget 0 "Not copy" 1 "Guest" 2 "User1" 3 "User2" 4 "User3" 5 "User4" 6 "User5" 7 "Not used";
VAL_ 1519 User5_RegistrationState 0 "Not Registered" 1 "Registered";
VAL_ 1519 User4_RegistrationState 0 "Not Registered" 1 "Registered";
VAL_ 1519 KeyLinkInitializationState 0 "Initialization in progress" 1 "Initialization completed";
VAL_ 1519 KeyLinkActivationState 0 "Activate" 1 "Deactivate";
VAL_ 1519 User3_RegistrationState 0 "Not Registered" 1 "Registered";
VAL_ 1519 User2_RegistrationState 0 "Not Registered" 1 "Registered";
VAL_ 1519 User1_RegistrationState 0 "Not Registered" 1 "Registered";
VAL_ 1519 UserSettingCopyRequest 0 "No request" 1 "Request";
VAL_ 1519 CurrentUserState_v2 0 "Guest" 1 "User 1" 2 "User 2" 3 "User 3" 4 "User 4" 5 "User 5" 6 "Not used" 7 "Unavailable";
VAL_ 1519 ClimAQSSensitivityRequest 0 "No request" 1 "Level 1" 2 "Level 2" 3 "Level 3" 4 "Level 4" 5 "Level 5" 6 "OFF request" 7 "Reset request";
VAL_ 1529 WAL_ActivationRequest2 0 "No request" 1 "WAL activation request" 2 "WAL deactivation request" 3 "WAL factory setting reset request";
VAL_ 1529 APPRUN_ActivationRequest2 0 "No Request" 1 "Approach Unlock Activation request" 2 "Approach Unlock Desactivation request" 3 "Approach Unlock Factory setting reset request";
VAL_ 1530 WAL_ActivationRequest 0 "No request" 1 "WAL activation request" 2 "WAL deactivation request" 3 "WAL factory setting reset request";
VAL_ 1530 APPRUN_ActivationRequest 0 "No Request" 1 "Approach Unlock activation request" 2 "Approach Unlock deactivation request" 3 "Approach Unlock Factory setting reset request";
VAL_ 1531 IKeyAccessActivationRequest2 0 "No Request" 1 "iKey Access Activation request" 2 "iKey Access Desactivation request" 3 "Reset Request";
VAL_ 1531 AirCondEcoActivationRequest2 0 "No request" 1 "Eco activation request" 2 "Eco deactivation request" 3 "Reset request";
VAL_ 1531 ISS_EcoActivationRequest2 0 "No request" 1 "Eco activation request" 2 "Eco deactivation request" 3 "Reset request";
VAL_ 1536 USM_WakeUp_Signal 0 "Table Value16489";
VAL_ 1537 ACC_StatusDisplay 0 "No display request" 1 "ACC waiting" 2 "ACC suspended" 3 "ACC activated";
VAL_ 1537 ADAS_ModeDisplay 0 "Cruise Control mode" 1 "Adaptive Cruise Control mode" 2 "TJP mode" 3 "Unavailable";
VAL_ 1538 LDW_AlertStatus 0 "No alert" 1 "Right alert" 2 "Left alert" 3 "Not used";
VAL_ 1543 LightingSystemFailure 0 "No Failure" 1 "Failure detected";
VAL_ 1543 AccessModeType 0 "Standard mode" 1 "Secure mode";
VAL_ 1543 GlasshatchStatus 0 "Unavailable Value" 1 "Glasshatch closed" 2 "Glasshatch open" 3 "Not Used";
VAL_ 1546 HFM_WakeUp_Signal 0 "Table Value16485";
VAL_ 1551 HVbatHeater_Authorization 0 "No autorisation of high voltage battery heater" 1 "Autorisation of high voltage battery heater";
VAL_ 1551 BatteryThermalPriorityRequest 0 "No request" 1 "Traction battery cooling priority request";
VAL_ 1551 BatteryWatterTempActivationReq 0 "No activation request" 1 "Battery water temp activation request";
VAL_ 1553 SecondRowCentralSeatStatus 0 "Unavailable" 1 "OFF display" 2 "Heater Low display" 3 "Heater Middle display" 4 "Heater High display" 5 "Ventilated Low display" 6 "Ventilated Middle display" 7 "Ventilated High display";
VAL_ 1553 ClimEVmodeAdviceForHeating 0 "No display" 1 "Heating not available, turn OFF EV mode" 2 "Heating not available, with EV mode ON" 3 "Heating perf decrease, turn OFF EV mode" 4 "Heating perf decrease, with EV mode ON" 5 "Heating perf decrease, in charge, with low temperature" 6 "Not used" 7 "Not used";
VAL_ 1553 ClimForcedFreshDisplayStatus 0 "Function not available" 1 "Function available";
VAL_ 1553 ClimForcedRecyDisplayStatus 0 "Function not available" 1 "Function available";
VAL_ 1553 ClimForcedFreshDisplay 0 "No display" 1 "Fresh ON" 2 "Fresh OFF" 3 "Not Used";
VAL_ 1553 ClimAQSSensitivityDisplay 0 "No display" 1 "Level 1" 2 "Level 2" 3 "Level 3" 4 "Level 4" 5 "Level 5" 6 "OFF" 7 "Not used";
VAL_ 1553 ClimExternalAirPollutionDisplay 0 "No display" 1 "LEVEL 1" 2 "LEVEL 2" 3 "LEVEL 3" 4 "LEVEL 4" 5 "LEVEL 5" 6 "Not used" 7 "Not used";
VAL_ 1553 ClimRearDefrostDisplayStatus 0 "Function not available" 1 "Function available";
VAL_ 1553 ClimExternAirPollutioDispStatus 0 "Function not available" 1 "Function available";
VAL_ 1553 ClimLinkPriorityFLSeatAutoDisp 0 "No display" 1 "Level 1" 2 "Level 2" 3 "Level 3" 4 "Level 4" 5 "Level 5" 6 "OFF" 7 "Not used";
VAL_ 1553 ClimLinkPriorityFRSeatAutoDisp 0 "No display" 1 "Level 1" 2 "Level 2" 3 "Level 3" 4 "Level 4" 5 "Level 5" 6 "OFF" 7 "Not used";
VAL_ 1553 FrontRightSeatDisplayStatus 0 "Function not available" 1 "Function available";
VAL_ 1553 FrontRightSeatStatus 0 "Unavailable" 1 "OFF display" 2 "Heater Low display" 3 "Heater Middle display" 4 "Heater High display" 5 "Ventilated Low display" 6 "Ventilated Middle display" 7 "Ventilated High display";
VAL_ 1553 FrontLeftSeatStatus 0 "Unavailable" 1 "OFF display" 2 "Heater Low display" 3 "Heater Middle display" 4 "Heater High display" 5 "Ventilated Low display" 6 "Ventilated Middle display" 7 "Ventilated High display";
VAL_ 1553 FrontLeftSeatDisplayStatus 0 "Function not available" 1 "Function available";
VAL_ 1553 SecondRowLeftSeatAutoDisplay 0 "No display" 1 "Seat Auto ON" 2 "Seat Auto OFF" 3 "Not used";
VAL_ 1553 SecondRowRightSeatAutoDisplay 0 "No display" 1 "Seat Auto ON" 2 "Seat Auto OFF" 3 "Not used";
VAL_ 1553 FrontLeftSeatAutoDisplay 0 "No display" 1 "Seat Auto ON" 2 "Seat Auto OFF" 3 "Not used";
VAL_ 1553 FrontRightSeatAutoDisplay 0 "No display" 1 "Seat Auto ON" 2 "Seat Auto OFF" 3 "Not used";
VAL_ 1553 ThirdRowLeftSeatAutoDisplay 0 "No display" 1 "Seat Auto ON" 2 "Seat Auto OFF" 3 "Not used";
VAL_ 1553 ThirdRowRightSeatDisplayStatus 0 "Function not available" 1 "Function available";
VAL_ 1553 ThirdRowLeftSeatDisplayStatus 0 "Function not available" 1 "Function available";
VAL_ 1553 ThirdRowRightSeatAutoDisplay 0 "No display" 1 "Seat Auto ON" 2 "Seat Auto OFF" 3 "Not used";
VAL_ 1553 SecondRowRightSeatDisplayStatus 0 "Function not available" 1 "Function available";
VAL_ 1553 SecondRowLeftSeatDisplayStatus 0 "Function not available" 1 "Function available";
VAL_ 1553 ClimCabinTempDisplayUnit 0 "display mode in °C" 1 "display mode in °F";
VAL_ 1553 ClimLastFuncModifiedByCustomer_v2 0 "No last action" 1 "Temperature" 2 "Rear Climate" 3 "Rear defrost" 4 "Clearness" 5 "Flow Distribution" 6 "Forced Recycling" 7 "OFF Button" 8 "Blower Level" 9 "Seat heating / ventilating" 10 "Auto" 11 "AC" 12 "Auto Recycling" 13 "Front defrost" 14 "Sync" 15 "Steering Wheel Heater";
VAL_ 1553 ClimLinkPrioRearSeatsAutoDisp 0 "No display" 1 "Level 1" 2 "Level 2" 3 "Level 3" 4 "Level 4" 5 "Level 5" 6 "OFF" 7 "Not used";
VAL_ 1553 ClimACmaxDisplay 0 "No display" 1 "AC max ON" 2 "AC max OFF" 3 "Not Used";
VAL_ 1558 ClimateDriverSetting 0 "Defog priority" 1 "Climate AutoMode" 2 "No Climate AutoMode" 3 "Not Used";
VAL_ 1562 HVFOTAConditionCheckStatus 0 "No request" 1 "Pending Conditions" 2 "Achieved Conditions" 3 "Error Detected";
VAL_ 1573 OperatingTypeStatus_BLMS 0 "No request" 1 "Isolated charge" 2 "Non-isolated charge" 3 "External charge (battery outside vehicle)" 4 "Transitory" 5 "Driving" 6 "Init" 7 "DC Charging without RISOL" 8 "risolCheckMode" 9 "DC Charging with RISOL" 10 "V2G" 11 "V2L" 12 "Reserved" 13 "Reserved" 14 "Reserved" 15 "Reserved";
VAL_ 1575 BattSens_OBD_CurrRational_Suc 0 "OK status is not detected" 1 "OK status is detected";
VAL_ 1575 BattSens_OBD_CurrRational_Fault 0 "NOK status is not detected" 1 "NOK status is detected";
VAL_ 1575 BattSens_OBD_CurrOoRLo_Success 0 "OK status is not detected" 1 "OK status is detected";
VAL_ 1575 BattSens_OBD_CurrOoRLo_Fault 0 "NOK status is not detected" 1 "NOK status is detected";
VAL_ 1575 BattSens_OBD_CurrOoRHi_Success 0 "OK status is not detected" 1 "OK status is detected";
VAL_ 1575 BattSens_OBD_CurrOoRHi_Fault 0 "NOK status is not detected" 1 "NOK status is detected";
VAL_ 1575 BattSens_OBD_CurrOC_Success 0 "OK status is not detected" 1 "OK status is detected";
VAL_ 1575 BattSens_OBD_CurrOC_Fault 0 "NOK status is not detected" 1 "NOK status is detected";
VAL_ 1575 BattSensLostComFail_OBD_Success 0 "OK status is not detected" 1 "OK status is detected";
VAL_ 1575 BattSensLostComFail_OBD_Fault 0 "NOK status is not detected" 1 "NOK status is detected";
VAL_ 1575 BattSens_OBD_TempOoRLo_Success 0 "OK status is not detected" 1 "OK status is detected";
VAL_ 1575 BattSens_OBD_TempOoRLo_Fault 0 "NOK status is not detected" 1 "NOK status is detected";
VAL_ 1575 BattSens_OBD_TempOoRHi_Success 0 "OK status is not detected" 1 "OK status is detected";
VAL_ 1575 BattSens_OBD_TempOoRHi_Fault 0 "NOK status is not detected" 1 "NOK status is detected";
VAL_ 1575 BattSens_OBD_TempOC_Success 0 "OK status is not detected" 1 "OK status is detected";
VAL_ 1575 BattSens_OBD_TempOC_Fault 0 "NOK status is not detected" 1 "NOK status is detected";
VAL_ 1575 BattVoltMeas_OBDRational_Suc 0 "OK status is not detected" 1 "OK status is detected";
VAL_ 1575 BattVoltMeas_OBDRational_Fault 0 "NOK status is not detected" 1 "NOK status is detected";
VAL_ 1575 BattVoltMeas_OBDOPEN_Success 0 "OK status is not detected" 1 "OK status is detected";
VAL_ 1575 BattVoltMeas_OBDOPEN_Fault 0 "NOK status is not detected" 1 "NOK status is detected";
VAL_ 1575 BattVoltMeas_OBDOoRLo_Success 0 "OK status is not detected" 1 "OK status is detected";
VAL_ 1575 BattVoltMeas_OBDOoRLo_Fault 0 "NOK status is not detected" 1 "NOK status is detected";
VAL_ 1575 BattVoltMeas_OBDOoRHi_Success 0 "OK status is not detected" 1 "OK status is detected";
VAL_ 1575 BattVoltMeas_OBDOoRHi_Fault 0 "NOK status is not detected" 1 "NOK status is detected";
VAL_ 1585 HybridTractionMode 0 "No display" 1 "ZEV mode activated" 2 "Auto mode activated" 3 "Charge Battery" 4 "Sport mode activated" 5 "Temporary no ZEV" 6 "Save Battery level activated" 7 "Not used";
VAL_ 1592 HVpowerRequest_HVAC 0 "No request" 1 "HV Power request";
VAL_ 1592 ValveBattStatus 0 "No error" 1 "Short circuit" 2 "Open circuit" 3 "Not Used";
VAL_ 1592 HVbatConditioningMode 0 "No request" 1 "Cooling by Chiller" 2 "Heating Recovery" 3 "Heating by PTC" 4 "Battery Range Boost" 5 "Cooling by Radiator" 6 "Heating Recovery without Battery" 7 "Not used" 8 "Not used" 9 "Not used" 10 "Not used" 11 "Not used" 12 "Not used" 13 "Not used" 14 "Not used" 15 "Not used";
VAL_ 1592 HeatingBattery_HVACmode 0 "No battery heating requested" 1 "Battery heating on going" 2 "Not used" 3 "Unavailable";
VAL_ 1592 DeIcing_HVACmode 0 "No De_Icing requested" 1 "De_Icing requested" 2 "Not used" 3 "Unavailable";
VAL_ 1592 CoolingBattery_HVACmode 0 "No battery cooling requested" 1 "Battery cooling on going" 2 "Not used" 3 "Unavailable";
VAL_ 1592 CabinCondDuringCharge_HVACmode 0 "No Cabin Conditionning during charge requested" 1 "Cabin conditionning during charge on going" 2 "Not used" 3 "Unavailable";
VAL_ 1592 TractionBatteryCoolingLimited 0 "Not limited" 1 "Traction battery cooling limited";
VAL_ 1592 PresoakImmediate_HVACmode 0 "No Immediate Presoak Requested" 1 "Immediate Presoak in progress" 2 "Not used" 3 "Unavailable";
VAL_ 1592 PreConditioningBattery_HVACmode 0 "No Battery Preconditionning requested" 1 "Battery Preconditionning on going" 2 "Not used" 3 "Unavailable";
VAL_ 1592 eAC_RevCapStatus 0 "Unavailable" 1 "Capped eAC rpm" 2 "Uncapped eAC rpm" 3 "Not used";
VAL_ 1592 EVBattDiag 0 "No error" 1 "Short circuit to ground" 2 "Short circuit to supply or Open Circuit" 3 "Not used";
VAL_ 1592 BattCoolingDiag 0 "diagnosis not started or on going" 1 "diagnosis finished and battery cooling OK" 2 "diagnosis finished and battery cooling NOK" 3 "diagnosis unavailable";
VAL_ 1592 EVLinStatus 0 "No error" 1 "LIN communication error";
VAL_ 1592 EVBattStatus 0 "No error" 1 "Stuck";
VAL_ 1592 IRStateDisplay 0 "No Display" 1 "IR ON" 2 "IR OFF" 3 "Not Used";
VAL_ 1601 RemoteFunctionService_DOP_TCU 0 "Table Value16369";
VAL_ 1602 RemoteFunctionService_HFM_DOPRES 0 "Table Value16370";
VAL_ 1613 FOTA_ReadyToSleep 0 "Refuse to sleep due to FOTA" 1 "Ready to sleep";
VAL_ 1616 APA_CancelReason2 0 "No display" 1 "APA Permanent Failure" 2 "Parking Sensor permanent Failure" 3 "Not Used";
VAL_ 1626 ADB_FailureDisplay 0 "No ADB Failure" 1 "ADB Failure";
VAL_ 1626 ADB_FailureDetection 0 "No Failure" 1 "Failure";
VAL_ 1626 ADB_AuthorizationStatus 0 "ADB is on low beam" 1 "ADB is on high beam";
VAL_ 1637 MultiDriveMode_ADB 0 "Mode ADB 1 (Normal)" 1 "Mode ADB 2" 2 "Mode ADB 3 (Sport)" 3 "Mode ADB 4" 4 "Mode ADB 5 (Eco)" 5 "Mode ADB 6 (Race)" 6 "Mode ADB 7 (Snow)" 7 "Unavailable";
VAL_ 1637 MultiDriveMode_HVAC 0 "Mode HVAC 1 (Normal)" 1 "Mode HVAC 2" 2 "Mode HVAC 3" 3 "Mode HVAC 4" 4 "Mode HVAC 5 (Eco)" 5 "Mode HVAC 6 (Race)" 6 "Mode HVAC 7 " 7 "Unavailable";
VAL_ 1639 ChargingPlugStatus 0 "Not connected" 1 "Connected";
VAL_ 1645 AEB_FCWactivationState2 0 "AEB OFF / FCW OFF" 1 "AEB OFF / FCW ON" 2 "Not used" 3 "AEB ON / FCW ON";
VAL_ 1645 AEB_BrakeWheelTorqueOrder2_EDR 0 "No Brake Request" 1 "Brake Torque AEB moderate" 2 "Brake Torque AEB strong" 3 "Brake Torque AEB city" 4 "Brake Torque AEB Maximum" 5 "Not used" 6 "Not used" 7 "unavailable";
VAL_ 1645 AEB_VehicleAlertRequest2 0 "No AEB vehicle alert" 1 "AEB vehicle Approach alert" 2 "AEB vehicle Collision alert" 3 "AEB vehicle Alert reminder";
VAL_ 1645 AEB_FailureDisplay2 0 "No display" 1 "Temporary Failure Display" 2 "Permanent Failure Display" 3 "Not used";
VAL_ 1645 AEB_StatusDisplay2_v2 0 "No display" 1 "AEB Off" 2 "operation" 3 "Not operation" 4 "Temporary failure" 5 "Permanent failure" 6 "Initial" 7 "Not Used";
VAL_ 1659 IKeyCardDetectionStatus 0 "No information (unavailable)" 1 "IKey in the vehicle" 2 "IKey not in the vehicle" 3 "Not Used";
VAL_ 1659 RemoteChargingStop 0 "No Request" 1 "Stop charge Request";
VAL_ 1659 UserIdentification_IKeyLink 0 "No request" 1 "Key No. 1" 2 "Key No. 2" 3 "Key No. 3" 4 "Key No. 4" 5 "Not used" 6 "Not used" 7 "Not used";
VAL_ 1659 RESPreSoakProgReq_SP 0 "No Timer" 1 "Start Timer Request - one time" 2 "Start Timer Request - every two hours (5 times max)" 3 "Not used";
VAL_ 1659 UserIdentification_IKeyLink_HFM 0 "No request" 1 "Key No. 1" 2 "Key No. 2" 3 "Key No. 3" 4 "Key No. 4" 5 "Owner Key" 6 "Friend Key ID 1" 7 "Friend Key ID 2" 8 "Friend Key ID 3" 9 "Friend Key ID 4" 10 "Friend Key ID 5" 11 "Not used" 12 "Not used" 13 "Not used" 14 "Not used" 15 "Unavailable";
VAL_ 1660 RearSeatsLockStatus 0 "Unavailable" 1 "Thermal comfort lockdisplay" 2 "Thermal comfort unlock display" 3 "Not Used";
VAL_ 1660 SecondRowRightSeatStatus 0 "Unvailable" 1 "OFF display" 2 "Heater Low display" 3 "Heater Middle display" 4 "Heater High display" 5 "Ventilated Low display" 6 "Ventilated Middle display" 7 "Ventilated High display";
VAL_ 1660 SecondRowLeftSeatStatus 0 "Unvailable" 1 "OFF display" 2 "Heater Low display" 3 "Heater Middle display" 4 "Heater High display" 5 "Ventilated Low display" 6 "Ventilated Middle display" 7 "Ventilated High display";
VAL_ 1660 ClimAutoRecyclingDisplayStatus 0 "Function not available" 1 "Function available";
VAL_ 1660 ClimACDisplayStatus 0 "Function not available" 1 "Function available";
VAL_ 1660 ThirdRowRightSeatStatus 0 "Unvailable" 1 "OFF display" 2 "Heater Low display" 3 "Heater Middle display" 4 "Heater High display" 5 "Ventilated Low display" 6 "Ventilated Middle display" 7 "Ventilated High display";
VAL_ 1660 ThirdRowLeftSeatStatus 0 "Unvailable" 1 "OFF display" 2 "Heater Low display" 3 "Heater Middle display" 4 "Heater High display" 5 "Ventilated Low display" 6 "Ventilated Middle display" 7 "Ventilated High display";
VAL_ 1660 ClimEVHeaterDisplayStatus 0 "Function not available" 1 "Function available";
VAL_ 1660 ClimDriverZoneDisplayStatus 0 "Function not available" 1 "Function available";
VAL_ 1660 ClimDriverZoneDisplay 0 "No display" 1 "Driver zone ON" 2 "Driver zone OFF" 3 "Not used";
VAL_ 1660 ClimClearnessDisplayStatus 0 "Function not available" 1 "Function available";
VAL_ 1660 ClimBlowingLevelDisplayStatus 0 "Function not available" 1 "Function available";
VAL_ 1660 ClimBlowingAutoDisplay 0 "No display" 1 "Blowing auto ON" 2 "Blowing auto OFF" 3 "Not used";
VAL_ 1660 ClimHumidityDisplayStatus 0 "Function not available" 1 "Function available";
VAL_ 1660 ClimForestSettingDisplayStatus 0 "Function not available" 1 "Function available";
VAL_ 1660 ClimForestDisplayStatus 0 "Function not available" 1 "Function available";
VAL_ 1660 ClimForestDisplay 0 "No display" 1 "Forest ON" 2 "Forest OFF" 3 "Not used";
VAL_ 1660 ClimFlowDistrDisplayStatus 0 "Function not available" 1 "Function available";
VAL_ 1660 ClimEVHeaterDisplay 0 "No display" 1 "EV heater ON" 2 "EV heater OFF" 3 "Not Used";
VAL_ 1660 ClimLinkDefrostAndClearnesDisp 0 "No display" 1 "HFS and Rear def link to Clearness ON" 2 "HFS and Rear def link to Clearness OFF" 3 "Not used";
VAL_ 1660 ClimHumiditySensorSensitivDisp 0 "No display" 1 "Level 1" 2 "Level 2" 3 "Level 3" 4 "Level 4" 5 "Level 5" 6 "OFF" 7 "not used";
VAL_ 1660 ClimHumidityDisplay 0 "No display" 1 "Humidity OFF" 2 "Humidity Low" 3 "Humidity Mid" 4 "Humidity High" 5 "Not used" 6 "Not used" 7 "Not used";
VAL_ 1660 ClimRightAutoDisplay 0 "No display" 1 "Auto ON" 2 "Auto OFF" 3 "Not Used";
VAL_ 1660 ClimOFFModeDisplayStatus 0 "Function not available" 1 "Function available";
VAL_ 1660 ClimLinkMaxFanSpeedAutoDisplay 0 "No display" 1 "Level 1" 2 "Level 2" 3 "Level 3" 4 "Level 4" 5 "Level 5" 6 "OFF" 7 "not used";
VAL_ 1660 ClimLinkFreshRecyAndAutoDisplay 0 "No display" 1 "Air intake link to Auto ON" 2 "Air intake link to Auto OFF" 3 "Not used";
VAL_ 1660 ClimRightFlowDistrDisplayStatus 0 "Function not available" 1 "Function available";
VAL_ 1660 ClimRightBlowingLevelDispStatus 0 "Function not available" 1 "Function available";
VAL_ 1660 ClimRightBlowingLevelDisplay 0 "No display" 1 "Level 1" 2 "Level 2" 3 "Level 3" 4 "Level 4" 5 "Level 5" 6 "Level 6" 7 "Level 7" 8 "Level 8" 9 "Level 9" 10 "Level 10" 11 "Level 11" 12 "Level 12" 13 "Level 13" 14 "Level 14" 15 "Blower OFF";
VAL_ 1660 ClimRightBlowingAutoDisplay 0 "No display" 1 "Blowing auto ON" 2 "Blowing auto OFF" 3 "Not used";
VAL_ 1660 ClimTempDisplayStatus 0 "Function not available" 1 "Function available";
VAL_ 1660 ClimSyncDisplayStatus 0 "Function not available" 1 "Function available";
VAL_ 1660 ClimSyncDisplay 0 "No display" 1 "Sync mode ON" 2 "Sync mode OFF" 3 "Not Used";
VAL_ 1660 ClimRightTempDisplayStatus 0 "Function not available" 1 "Function available";
VAL_ 1660 ClimRightFlowDistrDisplay 0 "No display" 1 "Feet" 2 "Vent" 3 "Feet + Vent" 4 "Defrost" 5 "Defrost + Feet" 6 "Defrost + Vent" 7 "Defrost + Vent + Feet";
VAL_ 1662 SecondRowRightSeatRequest 0 "No request" 1 "OFF request" 2 "Heater Low request" 3 "Heater Middle request" 4 "Heater High request" 5 "Ventilated Low request" 6 "Ventilated Middle request" 7 "Ventilated High request" 8 "Reset request" 9 "Not Used" 10 "Not Used" 11 "Not Used" 12 "Not Used" 13 "Not Used" 14 "Not Used" 15 "Not Used";
VAL_ 1662 SecondRowLeftSeatRequest 0 "No request" 1 "OFF request" 2 "Heater Low request" 3 "Heater Middle request" 4 "Heater High request" 5 "Ventilated Low request" 6 "Ventilated Middle request" 7 "Ventilated High request" 8 "Reset request" 9 "Not Used" 10 "Not Used" 11 "Not Used" 12 "Not Used" 13 "Not Used" 14 "Not Used" 15 "Not Used";
VAL_ 1662 ThirdRowRightSeatRequest 0 "No request" 1 "OFF request" 2 "Heater Low request" 3 "Heater Middle request" 4 "Heater High request" 5 "Ventilated Low request" 6 "Ventilated Middle request" 7 "Ventilated High request" 8 "Reset request" 9 "Not Used" 10 "Not Used" 11 "Not Used" 12 "Not Used" 13 "Not Used" 14 "Not Used" 15 "Not Used";
VAL_ 1662 ThirdRowLeftSeatRequest 0 "No request" 1 "OFF request" 2 "Heater Low request" 3 "Heater Middle request" 4 "Heater High request" 5 "Ventilated Low request" 6 "Ventilated Middle request" 7 "Ventilated High request" 8 "Reset request" 9 "Not Used" 10 "Not Used" 11 "Not Used" 12 "Not Used" 13 "Not Used" 14 "Not Used" 15 "Not Used";
VAL_ 1662 RearSeatsLockRequest 0 "No request" 1 "Thermal comfort lock request" 2 "Thermal comfort unlock request" 3 "Reset request";
VAL_ 1662 ClimHumiditySensorSensitivitReq 0 "No request" 1 "Level 1" 2 "Level 2" 3 "Level 3" 4 "Level 4" 5 "Level 5" 6 "OFF request" 7 "Reset request";
VAL_ 1662 TimeFormatDisplay 0 "24h format" 1 "12h format";
VAL_ 1662 ClimFPrightBlowingRequest 0 "No Request" 1 "Level 1" 2 "Level 2" 3 "Level 3" 4 "Level 4" 5 "Level 5" 6 "Level 6" 7 "Level 7" 8 "Level 8" 9 "Level 9" 10 "Level 10" 11 "Level 11" 12 "Level 12" 13 "Level 13" 14 "Level 14" 15 "Blower OFF";
VAL_ 1662 ClimLinkPriorityFLSeatAutoReq 0 "No request" 1 "Level 1" 2 "Level 2" 3 "Level 3" 4 "Level 4" 5 "Level 5" 6 "OFF request" 7 "Reset request";
VAL_ 1662 ClimLinkMaxFanSpeedAutoReq 0 "No request" 1 "Level 1" 2 "Level 2" 3 "Level 3" 4 "Level 4" 5 "Level 5" 6 "OFF request" 7 "Reset request";
VAL_ 1662 ClimLinkPriorityFRSeatAutoReq 0 "No request" 1 "Level 1" 2 "Level 2" 3 "Level 3" 4 "Level 4" 5 "Level 5" 6 "OFF request" 7 "Reset request";
VAL_ 1670 AnimationPatternRequest 0 "No Request" 1 "Pattern1" 2 "Pattern2" 3 "Pattern3" 4 "Pattern4" 5 "Pattern5" 6 "Pattern6" 7 "Pattern7" 8 "Pattern8" 9 "Pattern9" 10 "Pattern10" 11 "Pattern11" 12 "Pattern12" 13 "Pattern13" 14 "Pattern14" 15 "Reset requested";
VAL_ 1671 AnimationPatternState 0 "Not used" 1 "Pattern1" 2 "Pattern2" 3 "Pattern3" 4 "Pattern4" 5 "Pattern5" 6 "Pattern6" 7 "Pattern7" 8 "Pattern8" 9 "Pattern9" 10 "Pattern10" 11 "Pattern11" 12 "Pattern12" 13 "Pattern13" 14 "Pattern14" 15 "Unavailable";
VAL_ 1673 RemoteFunctionService_DOP_RES 0 "Table Value16368";
VAL_ 1676 HFM_SGW_pairing 0 "Table Value161916";
VAL_ 1680 ParkOutCommand 0 "No request" 1 "Master Blanking request" 2 "Master Write code request" 3 "Master Park-out authorization request";
VAL_ 1682 ClimClearnessStatus 0 "Clearness OFF" 1 "Clearness ON";
VAL_ 1682 ClimHeatedSteeringWheelDisplay 0 "No display" 1 "Heated Steering Wheel ON" 2 "Heated Steering Wheel OFF" 3 "Not used";
VAL_ 1682 ClimDualModeDisplay_v2 0 "No Display" 1 "Dual Mode ON" 2 "Dual Mode OFF" 3 "Not used";
VAL_ 1682 HVAC_PresoakStateDisplay 0 "No Presoak in progress" 1 "Presoak Forbidden" 2 "Presoak in progress" 3 "Unavailable";
VAL_ 1683 PressureSuction_Sens_Diag 0 "unavailable" 1 "open Circuit" 2 "short Circuit" 3 "out of range low" 4 "out of range high" 5 "Reserved" 6 "Reserved" 7 "Reserved";
VAL_ 1683 COND_Out_Temp_Sens_Diag 0 "unavailable" 1 "open Circuit" 2 "short Circuit" 3 "out of range low" 4 "out of range high" 5 "Rationality1" 6 "Rationality2" 7 "Reserved";
VAL_ 1683 COND_Out_Temp_Sens_Diag_Status 0 "diagnosis complete" 1 "diagnosis on going" 2 "failure detected" 3 "no failure";
VAL_ 1683 EXVBattCoolingDiag 0 "No error" 1 "Short circuit to ground" 2 "Short circuit to supply" 3 "Open Circuit";
VAL_ 1683 WaterCondInletTempDiag 0 "No Failure" 1 "Open circuit" 2 "Short circuit to ground" 3 "Short circuit to supply" 4 "Out of range low" 5 "Out of range high" 6 "Reserved" 7 "Reserved";
VAL_ 1683 PressureSuction_Sens_Diag_Status 0 "diagnosis complete" 1 "diagnosis on going" 2 "failure detected" 3 "no failure";
VAL_ 1683 EXVEvapoDiag 0 "No error" 1 "Short circuit to ground" 2 "Short circuit to supply" 3 "Open Circuit";
VAL_ 1683 InnerCondInletTempDiag 0 "No Failure" 1 "Open circuit" 2 "Short circuit to ground" 3 "Short circuit to supply" 4 "Out of range low" 5 "Out of range high" 6 "Rationality1" 7 "Rationality2";
VAL_ 1683 WaterCondOutletTempDiag 0 "No Failure" 1 "Open circuit" 2 "Short circuit to ground" 3 "Short circuit to supply" 4 "Out of range low" 5 "Out of range high" 6 "Reserved" 7 "Reserved";
VAL_ 1683 EVHeatingModeDiag 0 "No error" 1 "Short circuit to ground" 2 "Short circuit to supply" 3 "Open Circuit";
VAL_ 1683 EXVHeatingDiag 0 "No error" 1 "Short circuit to ground" 2 "Short circuit to supply" 3 "Open Circuit";
VAL_ 1683 InnerCondOutletTempDiag 0 "No Failure" 1 "Open circuit" 2 "Short circuit to ground" 3 "Short circuit to supply" 4 "Out of range low" 5 "Out of range high" 6 "Rationality1" 7 "Rationality2";
VAL_ 1683 EVDehumidificationDiag 0 "No error" 1 "Short circuit to ground" 2 "Short circuit to supply" 3 "Open Circuit";
VAL_ 1683 HVACLossLinCom_HPCU 0 "Not tested" 1 "Tested OK" 2 "Tested NOK" 3 "Disabled";
VAL_ 1683 HEVCLossCanCom_HPCU 0 "Not tested" 1 "Tested OK" 2 "Tested NOK" 3 "Disabled";
VAL_ 1683 MeterLossCanCom_HPCU 0 "Not tested" 1 "Tested OK" 2 "Tested NOK" 3 "Disabled";
VAL_ 1683 eEPR_Diag 0 "Not Tested" 1 "Open Circuit" 2 "Short Circuit" 3 "No Error" 4 "Not Used" 5 "Not Used" 6 "Not Used" 7 "Unavailable";
VAL_ 1683 TsSensorDiag_HPCU 0 "No Failure" 1 "Open circuit" 2 "Short circuit to ground" 3 "Short circuit to supply" 4 "Out of range low" 5 "Out of range high" 6 "Reserved" 7 "Reserved";
VAL_ 1684 HFP_MapContentDisplay2 0 "Empty Display" 1 "Scanning Display" 2 "ParkOutConfirmation Display" 3 "Guidance Display";
VAL_ 1684 RPES_Authorized 0 "Not authorized" 1 "authorized";
VAL_ 1685 FOTAConditionCheckRequest 0 "Unavailable value" 1 "No request" 2 "Set Request" 3 "Reserved";
VAL_ 1686 DateTimeUTCMalfunction 0 "No malfunction" 1 "Malfunction";
VAL_ 1694 SGW_HFM_pairing 0 "Table Value161975";
VAL_ 1695 VehicleID 0 "Table Value16392";
VAL_ 1710 RemoteFunctionService_HFM_DOPTCU 0 "Table Value16371";
VAL_ 1720 HandDrivingActivationRequest 0 "No request" 1 "Right Hand Driving requested" 2 "Left Hand Driving requested" 3 "Reset request";
VAL_ 1722 RemoteFunctionService_SGW 0 "Table Value161973";
VAL_ 1730 PulseRecordingRequest 0 "No request" 1 "Record request";
VAL_ 1741 BatteryCool_eACLimitStatus 0 "No request" 1 "Uncap request" 2 "No uncap request" 3 "Not used";
VAL_ 1742 AEB_CancelReason_v2 0 "No display" 1 "VDC desactivated by driver (Canceled by)" 2 "VDC in regulation (Canceled by)" 3 "FrCam Blocked" 4 "FrCam High tempearture" 5 "FrCam Permanent Failure" 6 "Radar blocked" 7 "Radar Permanent Failure" 8 "Front side radar blocked" 9 "Front side radar permanent failure" 10 "Trailer Presence" 11 "Race mode" 12 "Bad weather" 13 "Accel Pedal high temp" 14 "ADAS ECU Temporary failure" 15 "ADAS ECU Permanent failure";
VAL_ 1742 LDW_CancelReason 0 "No display" 1 "Camera blocked" 2 "Camera is overheat (High Temperature)" 3 "Camera permanent failure" 4 "LDW Refuse: Race mode" 5 "ADAS ECU Temporary failure" 6 "ADAS ECU Permanent failure" 7 "Not Used";
VAL_ 1742 LKA_CancelReason 0 "No display" 1 "Front Camera is blocked" 2 "Front Camera is overheat (High Temperature)" 3 "Front Camera permanent failure" 4 "LKA Refuse: LCA Active" 5 "LKA Refuse: Race mode" 6 "VDC desactivated by driver State" 7 "VDC in regulation State";
VAL_ 1742 LCA_CancelReason 0 "No alert" 1 "LCA refused : ACC not activated" 2 "LCA Permanent Failure" 3 "FrCamera High temperature" 4 "FrCamera Visibility is Impaired" 5 "FrCamera Permanent Failure" 6 "FrRadar Blocked" 7 "FrRadar permanent failure" 8 "LCA Refused : HOD" 9 "LCA Cancel : Target lost" 10 "LCA Cancel : other" 11 "LCA Refused : other" 12 "LCA Refused : Race mode" 13 "Bad weather" 14 "Not used" 15 "Not used";
VAL_ 1742 ELKA_CancelReason_v2 0 "No alert" 1 "Front Camera blocked" 2 "Front Camera permanent failure" 3 "Front Camera high temperature" 4 "Radar blocked" 5 "Radar permanent failure" 6 "Rear Side radar blocked" 7 "Rear Side radar permanent failure" 8 "Trailer presence" 9 "Front Side radar blocked" 10 "Front Side radar permanent failure" 11 "VDC desactivated by driver State" 12 "VDC in regulation State" 13 "Deactivated: Race Mode" 14 "ADAS ECU Temporary failure" 15 "ADAS ECU Permanent failure";
VAL_ 1742 ADmodeStatus_Slow 0 "AD/RPK OFF" 1 "AD2 L2 regulation" 2 "AD1 L3 regulation" 3 "RPK regulation" 4 "AD/RPK OFF + TD or MRM in regulation" 5 "AD2 L2 regulation + TD or MRM in regulation" 6 "AD1 L3 regulation + TD or MRM in regulation" 7 "RPK regulation + TD or MRM in regulation";
VAL_ 1748 HFM_VKM_pairing 0 "Table Value609464";
VAL_ 1749 VKM_HFM_pairing 0 "Table Value609472";
VAL_ 1789 ADB_RemoteLightingRequest 0 "Remote Lighting is not requested" 1 "Remote Lighting is requested";
VAL_ 2033 Scrap_AuthorizationRequest 0 "Table Value16372";
VAL_ 2041 Scrap_AuthorizationStatus 0 "Table Value16373";
VAL_ 2563507968 SIGMA_CDM 0 "Table Value16461";
VAL_ 2563507968 SIGMA_DTCCDM 0 "Table Value26862";
VAL_ 2563508007 SIGMA_eHBox 0 "Table Value430561";
VAL_ 2563508007 SIGMA_DTCeHBox 0 "Table Value430559";
VAL_ 2563508009 SIGMA_PSD_R 0 "Table Value153060";
VAL_ 2563508009 SIGMA_DTCPSD_R 0 "Table Value153056";
VAL_ 2563508019 SIGMA_PBD 0 "Table Value16399";
VAL_ 2563508019 SIGMA_DTCPBD 0 "Table Value26865";
VAL_ 2563508021 SIGMA_RADAR 0 "Table Value16466";
VAL_ 2563508021 SIGMA_DTCRADAR 0 "Table Value26884";
VAL_ 2563508022 SIGMA_PSCU 0 "Table Value16465";
VAL_ 2563508022 SIGMA_DTCPSCU 0 "Table Value26866";
VAL_ 2563508030 SIGMA_SRad_RL 0 "Table Value16470";
VAL_ 2563508030 SIGMA_DTCSRad_RL 0 "Table Value26868";
VAL_ 2563508035 SIGMA_eRDC_L 0 "Table Value252236";
VAL_ 2563508035 SIGMA_DTCeRDC_L 0 "Table Value252232";
VAL_ 2563508037 SIGMA_eRDC_R 0 "Table Value252238";
VAL_ 2563508037 SIGMA_DTCeRDC_R 0 "Table Value252233";
VAL_ 2563508042 SIGMA_ANC 0 "Table Value16458";
VAL_ 2563508042 SIGMA_DTCANC 0 "Table Value26859";
VAL_ 2563508064 SIGMA_VDC 0 "Table Value16380";
VAL_ 2563508064 SIGMA_DTCVDC 0 "Table Value26886";
VAL_ 2563508066 SIGMA_EPS 0 "Table Value16377";
VAL_ 2563508066 SIGMA_DTCEPS 0 "Table Value26879";
VAL_ 2563508067 SIGMA_METER 0 "Table Value16379";
VAL_ 2563508067 SIGMA_DTCMETER 0 "Table Value26883";
VAL_ 2563508068 SIGMA_HVAC 0 "Table Value28686";
VAL_ 2563508068 SIGMA_DTCHVAC 0 "Table Value28682";
VAL_ 2563508069 SIGMA_BCM 0 "Table Value16381";
VAL_ 2563508069 SIGMA_DTCBCM 0 "Table Value26877";
VAL_ 2563508071 SIGMA_IVI 0 "Table Value16383";
VAL_ 2563508071 SIGMA_DTCIVI 0 "Table Value26882";
VAL_ 2563508072 SIGMA_4WD 0 "Table Value28679";
VAL_ 2563508072 SIGMA_DTC4WD 0 "Table Value28678";
VAL_ 2563508077 SIGMA_USM 0 "Table Value16384";
VAL_ 2563508077 SIGMA_DTCUSM 0 "Table Value26885";
VAL_ 2563508078 SIGMA_SONAR 0 "Table Value28703";
VAL_ 2563508078 SIGMA_DTCSONAR 0 "Table Value28702";
VAL_ 2563508079 SIGMA_DSMU 0 "Table Value16462";
VAL_ 2563508079 SIGMA_DTCDSMU 0 "Table Value26863";
VAL_ 2563508082 SIGMA_ACU 0 "Table Value16374";
VAL_ 2563508082 SIGMA_DTCACU 0 "Table Value26874";
VAL_ 2563508089 SIGMA_PSD_L 0 "Table Value153059";
VAL_ 2563508089 SIGMA_DTCPSD_L 0 "Table Value153054";
VAL_ 2563508093 SIGMA_ADAS 0 "Table Value16457";
VAL_ 2563508093 SIGMA_DTCADAS 0 "Table Value26875";
VAL_ 2563508099 SIGMA_A_IVC 0 "Table Value16456";
VAL_ 2563508099 SIGMA_DTCA_IVC 0 "Table Value26858";
VAL_ 2563508108 SIGMA_INV_ME 0 "Table Value27356";
VAL_ 2563508108 SIGMA_DTCINV_ME 0 "Table Value27351";
VAL_ 2563508115 SIGMA_OBC_AC 0 "Table Value28687";
VAL_ 2563508115 SIGMA_DTCOBC_AC 0 "Table Value28683";
VAL_ 2563508122 SIGMA_HEVC 0 "Table Value27338";
VAL_ 2563508122 SIGMA_DTCHEVC 0 "Table Value27347";
VAL_ 2563508130 SIGMA_AUDIOamp 0 "Table Value16459";
VAL_ 2563508130 SIGMA_DTCAUDIOamp 0 "Table Value26860";
VAL_ 2563508133 SIGMA_HNS 0 "Table Value27353";
VAL_ 2563508133 SIGMA_DTCHNS 0 "Table Value27348";
VAL_ 2563508139 SIGMA_VKM 0 "Table Value252239";
VAL_ 2563508139 SIGMA_DTCVKM 0 "Table Value252234";
VAL_ 2563508153 SIGMA_HFM 0 "Table Value16382";
VAL_ 2563508153 SIGMA_DTCHFM 0 "Table Value26881";
VAL_ 2563508154 SIGMA_AVM 0 "Table Value27338";
VAL_ 2563508154 SIGMA_DTCAVM 0 "Table Value27343";
VAL_ 2563508157 SIGMA_SCU 0 "Table Value28688";
VAL_ 2563508157 SIGMA_DTCSCU 0 "Table Value28684";
VAL_ 2563508164 SIGMA_eShifter 0 "Table Value153058";
VAL_ 2563508164 SIGMA_DTCeShifter 0 "Table Value153055";
VAL_ 2563508181 SIGMA_SRad_RR 0 "Table Value16471";
VAL_ 2563508181 SIGMA_DTCSRad_RR 0 "Table Value26871";
VAL_ 2563508189 SIGMA_FrCamera 0 "Table Value16378";
VAL_ 2563508189 SIGMA_DTCFrCamera 0 "Table Value26880";
VAL_ 2563508200 SIGMA_ECM 0 "Table Value16376";
VAL_ 2563508200 SIGMA_DTCECM 0 "Table Value26878";
VAL_ 2563508201 SIGMA_ATCU 0 "Table Value16375";
VAL_ 2563508201 SIGMA_DTCATCU 0 "Table Value26876";
VAL_ 2563508205 SIGMA_BMS_HV 0 "Table Value27340";
VAL_ 2563508205 SIGMA_DTCBMS_HV 0 "Table Value27344";
VAL_ 2563508207 SIGMA_INV_HSG 0 "Table Value27355";
VAL_ 2563508207 SIGMA_DTCINV_HSG 0 "Table Value27350";
VAL_ 2563567883 SIGMA_BMS_12V 0 "Table Value16460";
VAL_ 2563567883 SIGMA_DTCBMS_12V 0 "Table Value26861";
VAL_ 2563567951 SIGMA_EPS_sub 0 "Table Value28685";
VAL_ 2563567951 SIGMA_DTCEPS_sub 0 "Table Value28681";
VAL_ 2563567958 SIGMA_eShiftAct 0 "Table Value153057";
VAL_ 2563567958 SIGMA_DTCeShiftAct 0 "Table Value153053";
VAL_ 2563567968 SIGMA_HUD 0 "Table Value27354";
VAL_ 2563567968 SIGMA_DTCHUD 0 "Table Value27349";
VAL_ 2563568024 SIGMA_HPCU 0 "Table Value55692";
VAL_ 2563568024 SIGMA_DTCHPCU 0 "Table Value55693";
VAL_ 2563568093 SIGMA_DCDC_HV 0 "Table Value28677";
VAL_ 2563568093 SIGMA_DTCDCDC_HV 0 "Table Value28680";
VAL_ 2563568098 SIGMA_EBA 0 "Table Value16463";
VAL_ 2563568098 SIGMA_DTCEBA 0 "Table Value26864";
VAL_ 2563568101 SIGMA_INV_RE 0 "Table Value27357";
VAL_ 2563568101 SIGMA_DTCINV_RE 0 "Table Value27352";
VAL_ 2563568130 SIGMA_AirSUSP 0 "Table Value359670";
VAL_ 2563568130 SIGMA_DTCAirSUSP 0 "Table Value359671";
VAL_ 2563568148 SIGMA_BSG 0 "Table Value27341";
VAL_ 2563568148 SIGMA_DTCBSG 0 "Table Value27345";
VAL_ 2563568163 SIGMA_SRad_FL 0 "Table Value16468";
VAL_ 2563568163 SIGMA_DTCSRad_FL 0 "Table Value26869";
VAL_ 2563568164 SIGMA_SRad_FR 0 "Table Value16469";
VAL_ 2563568164 SIGMA_DTCSRad_FR 0 "Table Value26870";
VAL_ 2563568201 SIGMA_STBW 0 "Table Value161590";
VAL_ 2563568201 SIGMA_DTCSTBW 0 "Table Value161588";
VAL_ 2563568233 SIGMA_DMC 0 "Table Value27342";
VAL_ 2563568233 SIGMA_DTCDMC 0 "Table Value27346";
VAL_ 2563568267 SIGMA_RSCU3R 0 "Table Value407697";
VAL_ 2563568267 SIGMA_DTCRSCU3R 0 "Table Value407696";
VAL_ 2563568288 SIGMA_BLM_RPK 0 "Table Value55679";
VAL_ 2563568288 SIGMA_DTCBLM_RPK 0 "Table Value55690";
VAL_ 2563568290 SIGMA_SCCM 0 "Table Value16467";
VAL_ 2563568290 SIGMA_DTCSCCM 0 "Table Value26867";
VAL_ 2563568300 SIGMA_RSCU2R 0 "Table Value359675";
VAL_ 2563568300 SIGMA_DTCRSCU2R 0 "Table Value359672";
VAL_ 2563639107 SIGMA_eRDC_L_ReadMeReqRDIAG 0 "Table Value252235";
VAL_ 2563639109 SIGMA_eRDC_R_ReadMeReqRDIAG 0 "Table Value252237";
VAL_ 2563639149 SIGMA_USM_ReadMeReqRDIAG 0 "Table Value407698";
VAL_ 2609102862 BCM_WakeUp_Signal 0 "Table Value16475";
VAL_ 2609102915 ERDC_L_WakeUp_Signal 0 "Table Value219101";
VAL_ 2609102917 ERDC_R_WakeUp_Signal 0 "Table Value219102";
VAL_ 2615028210 FTOOLS_CGWtoHVAC 0 "Table Value30452";
VAL_ 2615034610 FTOOLS_CGWtoUSM 0 "Table Value27371";
VAL_ 2615056625 FTOOLS_CGWtoHPCU 0 "Table Value30449";
VAL_ 2615066866 FTOOLS_CGWtoHFM 0 "Table Value143654";
VAL_ 2615079320 FTOOLS_HPCUtoCGW 0 "Table Value30463";
VAL_ 2615079465 FTOOLS_HVACtoCGW 0 "Table Value30466";
VAL_ 2615079490 FTOOLS_USMtoCGW 0 "Table Value27377";
VAL_ 2615079616 FTOOLS_HFMtoCGW 0 "Table Value143657";
